VERSION "HNNBNNNYNNNNNNNNNNNNNNNNNNNNNNNNNNNNNNNNNN/4/%%%/4/'%**4NNN///"

NS_ :

BS_ :

BU_:  Airbag BAP_Tester ICAS1_Gateway ICAS1_KommunikationsServer LE1 LE2 Motor_BEV Schaltbetaetigung

BO_ 1019 TSK_Ausrollkurve_01: 8 Motor_BEV
 SG_ TSK_Ausrollkurve_Schub_Reku_01 m0 : 0|7@1+ (2.000000,0.000000) [0.000000|252.000000] "Unit_KiloMeterPerHour" ICAS1_Gateway
 SG_ TSK_Ausrollkurve_Schub_Reku_05 m1 : 0|7@1+ (2.000000,0.000000) [0.000000|252.000000] "Unit_KiloMeterPerHour" ICAS1_Gateway
 SG_ TSK_Ausrollkurve_Schub_Reku_09 m2 : 0|7@1+ (2.000000,0.000000) [0.000000|252.000000] "Unit_KiloMeterPerHour" ICAS1_Gateway
 SG_ TSK_Ausrollkurve_Schub_Reku_13 m3 : 0|7@1+ (2.000000,0.000000) [0.000000|252.000000] "Unit_KiloMeterPerHour" ICAS1_Gateway
 SG_ TSK_Ausrollkurve_Schub_Reku_17 m4 : 0|7@1+ (2.000000,0.000000) [0.000000|252.000000] "Unit_KiloMeterPerHour" ICAS1_Gateway
 SG_ TSK_Ausrollkurve_Schub_Reku_02 m0 : 7|7@1+ (2.000000,0.000000) [0.000000|252.000000] "Unit_KiloMeterPerHour" ICAS1_Gateway
 SG_ TSK_Ausrollkurve_Schub_Reku_06 m1 : 7|7@1+ (2.000000,0.000000) [0.000000|252.000000] "Unit_KiloMeterPerHour" ICAS1_Gateway
 SG_ TSK_Ausrollkurve_Schub_Reku_10 m2 : 7|7@1+ (2.000000,0.000000) [0.000000|252.000000] "Unit_KiloMeterPerHour" ICAS1_Gateway
 SG_ TSK_Ausrollkurve_Schub_Reku_14 m3 : 7|7@1+ (2.000000,0.000000) [0.000000|252.000000] "Unit_KiloMeterPerHour" ICAS1_Gateway
 SG_ TSK_Ausrollkurve_Schub_Reku_18 m4 : 7|7@1+ (2.000000,0.000000) [0.000000|252.000000] "Unit_KiloMeterPerHour" ICAS1_Gateway
 SG_ TSK_Ausrollkurve_Schub_Reku_03 m0 : 14|7@1+ (2.000000,0.000000) [0.000000|252.000000] "Unit_KiloMeterPerHour" ICAS1_Gateway
 SG_ TSK_Ausrollkurve_Schub_Reku_07 m1 : 14|7@1+ (2.000000,0.000000) [0.000000|252.000000] "Unit_KiloMeterPerHour" ICAS1_Gateway
 SG_ TSK_Ausrollkurve_Schub_Reku_11 m2 : 14|7@1+ (2.000000,0.000000) [0.000000|252.000000] "Unit_KiloMeterPerHour" ICAS1_Gateway
 SG_ TSK_Ausrollkurve_Schub_Reku_15 m3 : 14|7@1+ (2.000000,0.000000) [0.000000|252.000000] "Unit_KiloMeterPerHour" ICAS1_Gateway
 SG_ TSK_Ausrollkurve_Schub_Reku_19 m4 : 14|7@1+ (2.000000,0.000000) [0.000000|252.000000] "Unit_KiloMeterPerHour" ICAS1_Gateway
 SG_ TSK_Ausrollkurve_Schub_Reku_04 m0 : 21|7@1+ (2.000000,0.000000) [0.000000|252.000000] "Unit_KiloMeterPerHour" ICAS1_Gateway
 SG_ TSK_Ausrollkurve_Schub_Reku_08 m1 : 21|7@1+ (2.000000,0.000000) [0.000000|252.000000] "Unit_KiloMeterPerHour" ICAS1_Gateway
 SG_ TSK_Ausrollkurve_Schub_Reku_12 m2 : 21|7@1+ (2.000000,0.000000) [0.000000|252.000000] "Unit_KiloMeterPerHour" ICAS1_Gateway
 SG_ TSK_Ausrollkurve_Schub_Reku_16 m3 : 21|7@1+ (2.000000,0.000000) [0.000000|252.000000] "Unit_KiloMeterPerHour" ICAS1_Gateway
 SG_ TSK_Ausrollkurve_Schub_Reku_20 m4 : 21|7@1+ (2.000000,0.000000) [0.000000|252.000000] "Unit_KiloMeterPerHour" ICAS1_Gateway
 SG_ TSK_Ausrollkurve_Segeln_01 m0 : 28|7@1+ (2.000000,0.000000) [0.000000|252.000000] "Unit_KiloMeterPerHour" ICAS1_Gateway
 SG_ TSK_Ausrollkurve_Segeln_05 m1 : 28|7@1+ (2.000000,0.000000) [0.000000|252.000000] "Unit_KiloMeterPerHour" ICAS1_Gateway
 SG_ TSK_Ausrollkurve_Segeln_09 m2 : 28|7@1+ (2.000000,0.000000) [0.000000|252.000000] "Unit_KiloMeterPerHour" ICAS1_Gateway
 SG_ TSK_Ausrollkurve_Segeln_13 m3 : 28|7@1+ (2.000000,0.000000) [0.000000|252.000000] "Unit_KiloMeterPerHour" ICAS1_Gateway
 SG_ TSK_Ausrollkurve_Segeln_17 m4 : 28|7@1+ (2.000000,0.000000) [0.000000|252.000000] "Unit_KiloMeterPerHour" ICAS1_Gateway
 SG_ TSK_Ausrollkurve_Segeln_02 m0 : 35|7@1+ (2.000000,0.000000) [0.000000|252.000000] "Unit_KiloMeterPerHour" ICAS1_Gateway
 SG_ TSK_Ausrollkurve_Segeln_06 m1 : 35|7@1+ (2.000000,0.000000) [0.000000|252.000000] "Unit_KiloMeterPerHour" ICAS1_Gateway
 SG_ TSK_Ausrollkurve_Segeln_10 m2 : 35|7@1+ (2.000000,0.000000) [0.000000|252.000000] "Unit_KiloMeterPerHour" ICAS1_Gateway
 SG_ TSK_Ausrollkurve_Segeln_14 m3 : 35|7@1+ (2.000000,0.000000) [0.000000|252.000000] "Unit_KiloMeterPerHour" ICAS1_Gateway
 SG_ TSK_Ausrollkurve_Segeln_18 m4 : 35|7@1+ (2.000000,0.000000) [0.000000|252.000000] "Unit_KiloMeterPerHour" ICAS1_Gateway
 SG_ TSK_Ausrollkurve_Segeln_03 m0 : 42|7@1+ (2.000000,0.000000) [0.000000|252.000000] "Unit_KiloMeterPerHour" ICAS1_Gateway
 SG_ TSK_Ausrollkurve_Segeln_07 m1 : 42|7@1+ (2.000000,0.000000) [0.000000|252.000000] "Unit_KiloMeterPerHour" ICAS1_Gateway
 SG_ TSK_Ausrollkurve_Segeln_11 m2 : 42|7@1+ (2.000000,0.000000) [0.000000|252.000000] "Unit_KiloMeterPerHour" ICAS1_Gateway
 SG_ TSK_Ausrollkurve_Segeln_15 m3 : 42|7@1+ (2.000000,0.000000) [0.000000|252.000000] "Unit_KiloMeterPerHour" ICAS1_Gateway
 SG_ TSK_Ausrollkurve_Segeln_19 m4 : 42|7@1+ (2.000000,0.000000) [0.000000|252.000000] "Unit_KiloMeterPerHour" ICAS1_Gateway
 SG_ TSK_Ausrollkurve_Segeln_04 m0 : 49|7@1+ (2.000000,0.000000) [0.000000|252.000000] "Unit_KiloMeterPerHour" ICAS1_Gateway
 SG_ TSK_Ausrollkurve_Segeln_08 m1 : 49|7@1+ (2.000000,0.000000) [0.000000|252.000000] "Unit_KiloMeterPerHour" ICAS1_Gateway
 SG_ TSK_Ausrollkurve_Segeln_12 m2 : 49|7@1+ (2.000000,0.000000) [0.000000|252.000000] "Unit_KiloMeterPerHour" ICAS1_Gateway
 SG_ TSK_Ausrollkurve_Segeln_16 m3 : 49|7@1+ (2.000000,0.000000) [0.000000|252.000000] "Unit_KiloMeterPerHour" ICAS1_Gateway
 SG_ TSK_Ausrollkurve_Segeln_20 m4 : 49|7@1+ (2.000000,0.000000) [0.000000|252.000000] "Unit_KiloMeterPerHour" ICAS1_Gateway
 SG_ TSK_Ausrollkurve_Mux M : 56|3@1+ (1.000000,0.000000) [0.000000|7.000000] "" ICAS1_Gateway
 SG_ TSK_Ausrollkurve_Reku  : 59|1@1+ (1.000000,0.000000) [0.000000|1.000000] "" ICAS1_Gateway
 SG_ TSK_Ausrollkurve_Schrittweite  : 60|1@1+ (1.000000,0.000000) [0.000000|1.000000] "" ICAS1_Gateway
 SG_ TSK_Ausrollkurve_Zaehler  : 61|2@1+ (1.000000,0.000000) [0.000000|3.000000] "" ICAS1_Gateway

BO_ 1716 VIN_01: 8 ICAS1_Gateway
 SG_ VIN_01_MUX M : 0|2@1+ (1.000000,0.000000) [0.000000|3.000000] "" Airbag Motor_BEV
 SG_ KS_Geheimnis_1 m0 : 8|8@1+ (1.000000,0.000000) [0.000000|255.000000] "" Airbag
 SG_ VIN_4 m1 : 8|8@1+ (1.000000,0.000000) [0.000000|255.000000] "" Airbag Motor_BEV
 SG_ VIN_11 m2 : 8|8@1+ (1.000000,0.000000) [0.000000|255.000000] "" Airbag Motor_BEV
 SG_ KS_Geheimnis_2 m0 : 16|8@1+ (1.000000,0.000000) [0.000000|255.000000] "" Airbag
 SG_ VIN_5 m1 : 16|8@1+ (1.000000,0.000000) [0.000000|255.000000] "" Airbag Motor_BEV
 SG_ VIN_12 m2 : 16|8@1+ (1.000000,0.000000) [0.000000|255.000000] "" Airbag Motor_BEV
 SG_ KS_Geheimnis_3 m0 : 24|8@1+ (1.000000,0.000000) [0.000000|255.000000] "" Airbag
 SG_ VIN_6 m1 : 24|8@1+ (1.000000,0.000000) [0.000000|255.000000] "" Airbag Motor_BEV
 SG_ VIN_13 m2 : 24|8@1+ (1.000000,0.000000) [0.000000|255.000000] "" Airbag Motor_BEV
 SG_ KS_Geheimnis_4 m0 : 32|8@1+ (1.000000,0.000000) [0.000000|255.000000] "" Airbag
 SG_ VIN_7 m1 : 32|8@1+ (1.000000,0.000000) [0.000000|255.000000] "" Airbag Motor_BEV
 SG_ VIN_14 m2 : 32|8@1+ (1.000000,0.000000) [0.000000|255.000000] "" Airbag Motor_BEV
 SG_ VIN_1 m0 : 40|8@1+ (1.000000,0.000000) [0.000000|255.000000] "" Airbag Motor_BEV
 SG_ VIN_8 m1 : 40|8@1+ (1.000000,0.000000) [0.000000|255.000000] "" Airbag Motor_BEV
 SG_ VIN_15 m2 : 40|8@1+ (1.000000,0.000000) [0.000000|255.000000] "" Airbag Motor_BEV
 SG_ VIN_2 m0 : 48|8@1+ (1.000000,0.000000) [0.000000|255.000000] "" Airbag Motor_BEV
 SG_ VIN_9 m1 : 48|8@1+ (1.000000,0.000000) [0.000000|255.000000] "" Airbag Motor_BEV
 SG_ VIN_16 m2 : 48|8@1+ (1.000000,0.000000) [0.000000|255.000000] "" Airbag Motor_BEV
 SG_ VIN_3 m0 : 56|8@1+ (1.000000,0.000000) [0.000000|255.000000] "" Airbag Motor_BEV
 SG_ VIN_10 m1 : 56|8@1+ (1.000000,0.000000) [0.000000|255.000000] "" Airbag Motor_BEV
 SG_ VIN_17 m2 : 56|8@1+ (1.000000,0.000000) [0.000000|255.000000] "" Airbag Motor_BEV

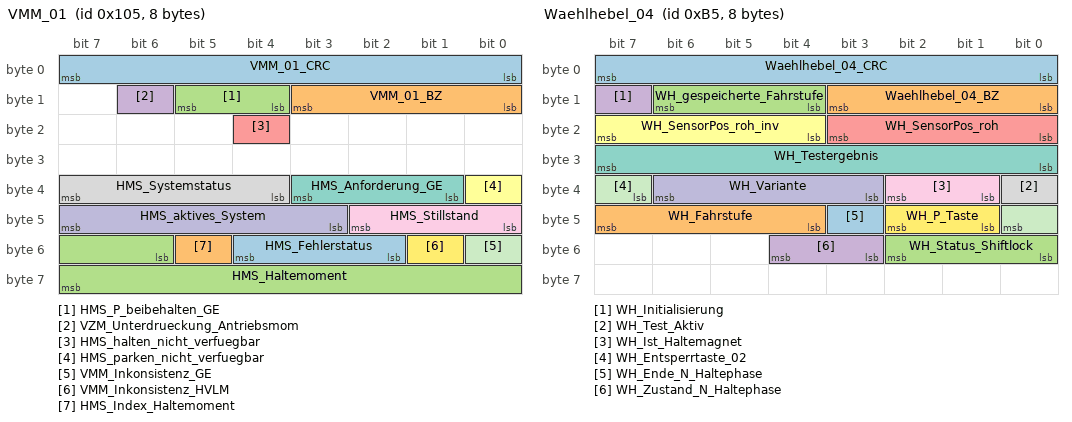
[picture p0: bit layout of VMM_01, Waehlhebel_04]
BO_ 261 VMM_01: 8 ICAS1_Gateway
 SG_ VMM_01_CRC  : 0|8@1+ (1.000000,0.000000) [0.000000|255.000000] "" Motor_BEV
 SG_ VMM_01_BZ  : 8|4@1+ (1.000000,0.000000) [0.000000|15.000000] "" Motor_BEV
 SG_ HMS_P_beibehalten_GE  : 12|2@1+ (1.000000,0.000000) [0.000000|3.000000] "" Vector__XXX
 SG_ VZM_Unterdrueckung_Antriebsmom  : 14|1@1+ (1.000000,0.000000) [0.000000|1.000000] "" Airbag Motor_BEV
 SG_ HMS_halten_nicht_verfuegbar  : 20|1@1+ (1.000000,0.000000) [0.000000|1.000000] "" Vector__XXX
 SG_ HMS_parken_nicht_verfuegbar  : 32|1@1+ (1.000000,0.000000) [0.000000|1.000000] "" Vector__XXX
 SG_ HMS_Anforderung_GE  : 33|3@1+ (1.000000,0.000000) [0.000000|7.000000] "" Vector__XXX
 SG_ HMS_Systemstatus  : 36|4@1+ (1.000000,0.000000) [0.000000|15.000000] "" Motor_BEV
 SG_ HMS_Stillstand  : 40|3@1+ (1.000000,0.000000) [0.000000|7.000000] "" Motor_BEV
 SG_ HMS_aktives_System  : 43|5@1+ (1.000000,0.000000) [0.000000|31.000000] "" Motor_BEV
 SG_ VMM_Inkonsistenz_GE  : 48|1@1+ (1.000000,0.000000) [0.000000|1.000000] "" Motor_BEV
 SG_ VMM_Inkonsistenz_HVLM  : 49|1@1+ (1.000000,0.000000) [0.000000|1.000000] "" Motor_BEV
 SG_ HMS_Fehlerstatus  : 50|3@1+ (1.000000,0.000000) [0.000000|7.000000] "" Vector__XXX
 SG_ HMS_Index_Haltemoment  : 53|1@1+ (1.000000,0.000000) [0.000000|1.000000] "" Motor_BEV
 SG_ HMS_Haltemoment  : 54|10@1+ (10.000000,0.000000) [0.000000|10210.000000] "Unit_NewtoMeter" Motor_BEV

BO_ 313 VMM_02: 32 ICAS1_Gateway
 SG_ VMM_02_CRC  : 0|8@1+ (1.000000,0.000000) [0.000000|255.000000] "" Motor_BEV
 SG_ VMM_02_BZ  : 8|4@1+ (1.000000,0.000000) [0.000000|15.000000] "" Motor_BEV
 SG_ VZM_aktiver_Basisservice  : 12|3@1+ (1.000000,0.000000) [0.000000|7.000000] "" Motor_BEV
 SG_ VZM_Anhalteweg_nicht_verfuegbar  : 15|1@1+ (1.000000,0.000000) [0.000000|1.000000] "" Motor_BEV
 SG_ VZM_Fahrer_bremst  : 16|1@1+ (1.000000,0.000000) [0.000000|1.000000] "" Motor_BEV
 SG_ VZM_QBit_Fahrer_bremst  : 17|1@1+ (1.000000,0.000000) [0.000000|1.000000] "" Motor_BEV
 SG_ VMM_MKB_codiert  : 18|1@1+ (1.000000,0.000000) [0.000000|1.000000] "" Airbag
 SG_ VMM_Inkonsistenz_EBKV  : 19|1@1+ (1.000000,0.000000) [0.000000|1.000000] "" Vector__XXX
 SG_ VMM_Notstopp_Status  : 20|3@1+ (1.000000,0.000000) [0.000000|7.000000] "" Motor_BEV
 SG_ VZM_Warnruck_nicht_verfuegbar  : 23|1@1+ (1.000000,0.000000) [0.000000|1.000000] "" Motor_BEV
 SG_ VZM_Warnruckeln_nicht_verfuegbar  : 24|1@1+ (1.000000,0.000000) [0.000000|1.000000] "" Motor_BEV
 SG_ VZM_Bkd_nicht_verfuegbar  : 25|1@1+ (1.000000,0.000000) [0.000000|1.000000] "" Motor_BEV
 SG_ VMM_Bremslicht_defekt  : 26|1@1+ (1.000000,0.000000) [0.000000|1.000000] "" Motor_BEV
 SG_ VZM_Fahrer_bremst_deutlich  : 27|1@1+ (1.000000,0.000000) [0.000000|1.000000] "" Airbag Motor_BEV
 SG_ VZM_TSK_SRBM_Anf  : 28|1@1+ (1.000000,0.000000) [0.000000|1.000000] "" Motor_BEV
 SG_ VZM_TSK_SRBM_nicht_verfuegbar  : 29|1@1+ (1.000000,0.000000) [0.000000|1.000000] "" Motor_BEV
 SG_ VZM_Verz_Reg_aktiv  : 30|5@1+ (1.000000,0.000000) [0.000000|31.000000] "" Motor_BEV
 SG_ VZM_Verz_Reg_nicht_verfuegbar  : 35|1@1+ (1.000000,0.000000) [0.000000|1.000000] "" Motor_BEV
 SG_ VMM_Inkonsistenz_KAS  : 36|1@1+ (1.000000,0.000000) [0.000000|1.000000] "" Motor_BEV
 SG_ VMM_Bremslicht_unplausibel  : 37|1@1+ (1.000000,0.000000) [0.000000|1.000000] "" Motor_BEV
 SG_ VMM_Inkonsistenz_ACC  : 38|1@1+ (1.000000,0.000000) [0.000000|1.000000] "" Motor_BEV
 SG_ VMM_Inkonsistenz_AWV_PCF  : 39|1@1+ (1.000000,0.000000) [0.000000|1.000000] "" Motor_BEV
 SG_ VMM_Inkonsistenz_ARA  : 40|1@1+ (1.000000,0.000000) [0.000000|1.000000] "" Motor_BEV
 SG_ VMM_Inkonsistenz_ParkAssist  : 41|1@1+ (1.000000,0.000000) [0.000000|1.000000] "" Motor_BEV
 SG_ VMM_Inkonsistenz_FAS_VK  : 42|1@1+ (1.000000,0.000000) [0.000000|1.000000] "" Motor_BEV
 SG_ VMM_Inkonsistenz_NV  : 43|1@1+ (1.000000,0.000000) [0.000000|1.000000] "" Motor_BEV
 SG_ VMM_Inkonsistenz_RCTA  : 44|1@1+ (1.000000,0.000000) [0.000000|1.000000] "" Motor_BEV
 SG_ VMM_Inkonsistenz_TSK  : 45|1@1+ (1.000000,0.000000) [0.000000|1.000000] "" Motor_BEV
 SG_ VMM_Inkonsistenz_MO  : 46|1@1+ (1.000000,0.000000) [0.000000|1.000000] "" Motor_BEV
 SG_ VMM_Inkonsistenz_AEB  : 47|1@1+ (1.000000,0.000000) [0.000000|1.000000] "" Vector__XXX
 SG_ VMM_Fahrer_Bremskraft_bestimmend  : 48|1@1+ (1.000000,0.000000) [0.000000|1.000000] "" Motor_BEV
 SG_ VMM_Inkonsistenz_EA  : 49|1@1+ (1.000000,0.000000) [0.000000|1.000000] "" Motor_BEV
 SG_ VZM_Status_Wegregelung  : 50|2@1+ (1.000000,0.000000) [0.000000|3.000000] "" Motor_BEV
 SG_ VZM_Verz_ASIL_Verfuegbarkeit  : 52|3@1+ (1.000000,0.000000) [0.000000|7.000000] "" Motor_BEV
 SG_ VZM_aktives_System  : 55|5@1+ (1.000000,0.000000) [0.000000|31.000000] "" Airbag Motor_BEV
 SG_ VZM_Verz_Begrenzung  : 60|1@1+ (1.000000,0.000000) [0.000000|1.000000] "" Motor_BEV
 SG_ VZM_Systemstatus  : 61|3@1+ (1.000000,0.000000) [0.000000|7.000000] "" Motor_BEV
 SG_ VZM_SRBM_Soll  : 64|12@1+ (8.000000,0.000000) [0.000000|32744.000000] "Unit_NewtoMeter" Motor_BEV
 SG_ VZM_SRBM_Ist  : 76|12@1+ (8.000000,0.000000) [0.000000|32744.000000] "Unit_NewtoMeter" Motor_BEV
 SG_ VZM_SRBM_max_Gradient  : 88|7@1+ (50.000000,0.000000) [0.000000|6250.000000] "Unit_NewtoMeterPerSecon" Motor_BEV
 SG_ VMM_Inkonsistenz_KAM  : 95|1@1+ (1.000000,0.000000) [0.000000|1.000000] "" Vector__XXX

BO_ 2463978663 VZE_04: 32 ICAS1_Gateway
 SG_ VZE_Anzeigemodus  : 0|2@1+ (1.000000,0.000000) [0.000000|3.000000] "" Vector__XXX
 SG_ VZE_Hinweistext  : 2|3@1+ (1.000000,0.000000) [1.000000|7.000000] "" Motor_BEV
 SG_ VZE_Verkehrszeichen_Einheit  : 8|1@1+ (1.000000,0.000000) [0.000000|1.000000] "" Vector__XXX
 SG_ VZE_Anzeigeunterdrueck_Zeichen_3  : 9|1@1+ (1.000000,0.000000) [0.000000|1.000000] "" Vector__XXX
 SG_ VZE_Anzeigeunterdrueck_Zeichen_2  : 10|1@1+ (1.000000,0.000000) [0.000000|1.000000] "" Vector__XXX
 SG_ VZE_Verkehrszeichen_1  : 11|8@1+ (1.000000,0.000000) [1.000000|255.000000] "" Motor_BEV
 SG_ VZE_Verkehrszeichen_2  : 19|8@1+ (1.000000,0.000000) [1.000000|255.000000] "" Vector__XXX
 SG_ VZE_Verkehrszeichen_3  : 27|8@1+ (1.000000,0.000000) [1.000000|255.000000] "" Vector__XXX
 SG_ VZE_Warnung_Verkehrszeichen_1  : 35|1@1+ (1.000000,0.000000) [0.000000|1.000000] "" Vector__XXX
 SG_ VZE_Warnung_Verkehrszeichen_2  : 36|1@1+ (1.000000,0.000000) [0.000000|1.000000] "" Vector__XXX
 SG_ VZE_Warnung_Verkehrszeichen_3  : 37|1@1+ (1.000000,0.000000) [0.000000|1.000000] "" Vector__XXX
 SG_ VZE_Zusatzschild_1  : 38|4@1+ (1.000000,0.000000) [1.000000|15.000000] "" Vector__XXX
 SG_ VZE_Zusatzschild_2  : 42|4@1+ (1.000000,0.000000) [1.000000|15.000000] "" Vector__XXX
 SG_ VZE_Zusatzschild_3  : 46|4@1+ (1.000000,0.000000) [1.000000|15.000000] "" Vector__XXX
 SG_ VZE_Anzeigeunterdrueck_Zeichen_1  : 50|1@1+ (1.000000,0.000000) [0.000000|1.000000] "" Vector__XXX
 SG_ VZE_Zeichen_01_KameraWied  : 51|1@1+ (1.000000,0.000000) [0.000000|1.000000] "" Motor_BEV
 SG_ VZE_Zeichen_02_KameraWied  : 52|1@1+ (1.000000,0.000000) [0.000000|1.000000] "" Vector__XXX
 SG_ VZE_Zeichen_03_KameraWied  : 53|1@1+ (1.000000,0.000000) [0.000000|1.000000] "" Vector__XXX
 SG_ VZE_Zeichen_01_Kamera  : 54|1@1+ (1.000000,0.000000) [0.000000|1.000000] "" Motor_BEV
 SG_ VZE_Zeichen_01_Karte  : 55|1@1+ (1.000000,0.000000) [0.000000|1.000000] "" Vector__XXX
 SG_ VZE_Zeichen_01_Gesetz  : 56|1@1+ (1.000000,0.000000) [0.000000|1.000000] "" Vector__XXX
 SG_ VZE_Zeichen_02_Kamera  : 57|1@1+ (1.000000,0.000000) [0.000000|1.000000] "" Vector__XXX
 SG_ VZE_Zeichen_02_Karte  : 58|1@1+ (1.000000,0.000000) [0.000000|1.000000] "" Vector__XXX
 SG_ VZE_Zeichen_02_Gesetz  : 59|1@1+ (1.000000,0.000000) [0.000000|1.000000] "" Vector__XXX
 SG_ VZE_Zeichen_03_Kamera  : 60|1@1+ (1.000000,0.000000) [0.000000|1.000000] "" Vector__XXX
 SG_ VZE_Zeichen_03_Karte  : 61|1@1+ (1.000000,0.000000) [0.000000|1.000000] "" Vector__XXX
 SG_ VZE_Zeichen_03_Gesetz  : 62|1@1+ (1.000000,0.000000) [0.000000|1.000000] "" Vector__XXX
 SG_ VZE_Gong  : 63|1@1+ (1.000000,0.000000) [0.000000|1.000000] "" Vector__XXX
 SG_ VZE_Anzeigeunterdrueck_Zeichen_5  : 72|1@1+ (1.000000,0.000000) [0.000000|1.000000] "" Vector__XXX
 SG_ VZE_Zeichen_05_KameraWied  : 73|1@1+ (1.000000,0.000000) [0.000000|1.000000] "" Vector__XXX
 SG_ VZE_Zeichen_05_Kamera  : 74|1@1+ (1.000000,0.000000) [0.000000|1.000000] "" Vector__XXX
 SG_ VZE_Verkehrszeichen_4  : 75|8@1+ (1.000000,0.000000) [1.000000|255.000000] "" Motor_BEV
 SG_ VZE_Verkehrszeichen_5  : 83|8@1+ (1.000000,0.000000) [1.000000|255.000000] "" Motor_BEV
 SG_ VZE_Anhaenger_Vmax  : 91|4@1+ (10.000000,10.000000) [10.000000|140.000000] "Unit_KiloMeterPerHour" Vector__XXX
 SG_ VZE_Zeichen_04_Gesetz  : 95|1@1+ (1.000000,0.000000) [0.000000|1.000000] "" Vector__XXX
 SG_ VZE_Zeichen_04_Kamera  : 96|1@1+ (1.000000,0.000000) [0.000000|1.000000] "" Vector__XXX
 SG_ VZE_Zeichen_04_KameraWied  : 97|1@1+ (1.000000,0.000000) [0.000000|1.000000] "" Vector__XXX
 SG_ VZE_Zeichen_04_Karte  : 98|1@1+ (1.000000,0.000000) [0.000000|1.000000] "" Vector__XXX
 SG_ VZE_Warnung_Verkehrszeichen_4  : 99|1@1+ (1.000000,0.000000) [0.000000|1.000000] "" Vector__XXX
 SG_ VZE_Warnung_Verkehrszeichen_5  : 100|1@1+ (1.000000,0.000000) [0.000000|1.000000] "" Vector__XXX
 SG_ VZE_Zeichen_05_Gesetz  : 101|1@1+ (1.000000,0.000000) [0.000000|1.000000] "" Vector__XXX
 SG_ VZE_Zusatzschild_4  : 102|4@1+ (1.000000,0.000000) [1.000000|15.000000] "" Vector__XXX
 SG_ VZE_Zusatzschild_5  : 106|4@1+ (1.000000,0.000000) [1.000000|15.000000] "" Vector__XXX
 SG_ VZE_Baustelle  : 110|2@1+ (1.000000,0.000000) [0.000000|3.000000] "" Vector__XXX
 SG_ VZE_Zeichen_05_Karte  : 112|1@1+ (1.000000,0.000000) [0.000000|1.000000] "" Vector__XXX
 SG_ VZE_Zeichen_05_Entfernung  : 113|7@1+ (1.000000,0.000000) [1.000000|127.000000] "Unit_Meter" Motor_BEV
 SG_ VZE_Zeichen_05_Entfernung_StdA  : 120|7@1+ (1.000000,0.000000) [1.000000|127.000000] "Unit_Meter" Motor_BEV
 SG_ VZE_Anzeigeunterdrueck_Zeichen_4  : 127|1@1+ (1.000000,0.000000) [0.000000|1.000000] "" Vector__XXX
 SG_ VZE_Verkehrszeichen_6  : 128|8@1+ (1.000000,0.000000) [1.000000|255.000000] "Unit_None" Motor_BEV
 SG_ VZE_Zusatzschild_6  : 136|4@1+ (1.000000,0.000000) [1.000000|15.000000] "" Vector__XXX
 SG_ VZE_Zeichen_06_Entfernung  : 140|7@1+ (1.000000,0.000000) [1.000000|127.000000] "Unit_Meter" Motor_BEV
 SG_ VZE_Zeichen_06_Entfernung_StdA  : 147|7@1+ (1.000000,0.000000) [1.000000|127.000000] "Unit_Meter" Motor_BEV
 SG_ VZE_Umweltinfo_Naesse  : 154|1@1+ (1.000000,0.000000) [0.000000|1.000000] "" Motor_BEV
 SG_ VZE_Umweltinfo_Nebel  : 155|1@1+ (1.000000,0.000000) [0.000000|1.000000] "" Motor_BEV
 SG_ VZE_Umweltinfo_Anhaengerbetrieb  : 156|1@1+ (1.000000,0.000000) [0.000000|1.000000] "" Vector__XXX
 SG_ VZE_Erweiterte_Information  : 157|8@1+ (1.000000,0.000000) [1.000000|255.000000] "Unit_None" Vector__XXX
 SG_ VZE_Tempowarnung_Status  : 165|1@1+ (1.000000,0.000000) [0.000000|1.000000] "" Vector__XXX
 SG_ VZE_Tempowarnung_Einheit  : 166|1@1+ (1.000000,0.000000) [0.000000|1.000000] "" Vector__XXX
 SG_ VZE_Tempowarnung_Offset  : 167|5@1+ (1.000000,0.000000) [1.000000|31.000000] "" Vector__XXX
 SG_ VZE_FoD_Status  : 206|2@1+ (1.000000,0.000000) [0.000000|3.000000] "" Vector__XXX
 SG_ VZE_Anzeige_ZS_1  : 208|4@1+ (1.000000,0.000000) [1.000000|15.000000] "Unit_None" Vector__XXX
 SG_ VZE_Anzeige_ZS_2  : 212|4@1+ (1.000000,0.000000) [1.000000|15.000000] "Unit_None" Vector__XXX
 SG_ VZE_Anzeige_ZS_3  : 216|4@1+ (1.000000,0.000000) [1.000000|15.000000] "Unit_None" Vector__XXX
 SG_ VZE_Hinweistext_03  : 220|4@1+ (1.000000,0.000000) [1.000000|15.000000] "" Vector__XXX
 SG_ VZE_Land  : 224|5@1+ (1.000000,0.000000) [1.000000|31.000000] "" Vector__XXX
 SG_ VZE_Warnung_VZ_1  : 229|1@1+ (1.000000,0.000000) [0.000000|1.000000] "" Vector__XXX
 SG_ VZE_Warnung_VZ_2  : 230|1@1+ (1.000000,0.000000) [0.000000|1.000000] "" Vector__XXX
 SG_ VZE_Warnung_VZ_3  : 231|1@1+ (1.000000,0.000000) [0.000000|1.000000] "" Vector__XXX
 SG_ VZE_Anzeige_VZ_1  : 232|8@1+ (1.000000,0.000000) [1.000000|255.000000] "" Vector__XXX
 SG_ VZE_Anzeige_VZ_2  : 240|8@1+ (1.000000,0.000000) [1.000000|255.000000] "Unit_None" Vector__XXX
 SG_ VZE_Anzeige_VZ_3  : 248|8@1+ (1.000000,0.000000) [1.000000|255.000000] "Unit_None" Vector__XXX

BO_ 181 Waehlhebel_04: 8 ICAS1_Gateway
 SG_ Waehlhebel_04_CRC  : 0|8@1+ (1.000000,0.000000) [0.000000|255.000000] "" Motor_BEV
 SG_ Waehlhebel_04_BZ  : 8|4@1+ (1.000000,0.000000) [0.000000|15.000000] "" Motor_BEV
 SG_ WH_gespeicherte_Fahrstufe  : 12|3@1+ (1.000000,0.000000) [0.000000|7.000000] "" Vector__XXX
 SG_ WH_Initialisierung  : 15|1@1+ (1.000000,0.000000) [0.000000|1.000000] "" Motor_BEV
 SG_ WH_SensorPos_roh  : 16|4@1+ (1.000000,0.000000) [0.000000|15.000000] "" Motor_BEV
 SG_ WH_SensorPos_roh_inv  : 20|4@1+ (1.000000,0.000000) [0.000000|15.000000] "" Motor_BEV
 SG_ WH_Testergebnis  : 24|8@1+ (1.000000,0.000000) [0.000000|255.000000] "" Vector__XXX
 SG_ WH_Test_Aktiv  : 32|1@1+ (1.000000,0.000000) [0.000000|1.000000] "" Vector__XXX
 SG_ WH_Ist_Haltemagnet  : 33|2@1+ (1.000000,0.000000) [0.000000|3.000000] "" Motor_BEV
 SG_ WH_Variante  : 35|4@1+ (1.000000,0.000000) [0.000000|15.000000] "" Motor_BEV
 SG_ WH_Entsperrtaste_02  : 39|2@1+ (1.000000,0.000000) [0.000000|3.000000] "" Motor_BEV
 SG_ WH_P_Taste  : 41|2@1+ (1.000000,0.000000) [0.000000|3.000000] "" Motor_BEV
 SG_ WH_Ende_N_Haltephase  : 43|1@1+ (1.000000,0.000000) [0.000000|1.000000] "" Vector__XXX
 SG_ WH_Fahrstufe  : 44|4@1+ (1.000000,0.000000) [0.000000|15.000000] "" Motor_BEV
 SG_ WH_Status_Shiftlock  : 48|3@1+ (1.000000,0.000000) [0.000000|7.000000] "" Motor_BEV
 SG_ WH_Zustand_N_Haltephase  : 51|2@1+ (1.000000,0.000000) [0.000000|3.000000] "" Vector__XXX

BO_ 2463978687 Waehlhebel_06: 8 ICAS1_Gateway
 SG_ WH_Fehler_Haltemagnet_Status  : 41|1@1+ (1.000000,0.000000) [0.000000|1.000000] "" Motor_BEV
 SG_ WH_Fehler_CRC_SBM  : 42|1@1+ (1.000000,0.000000) [0.000000|1.000000] "" Motor_BEV
 SG_ WH_Fehler_CRC_SBM_Status  : 43|1@1+ (1.000000,0.000000) [0.000000|1.000000] "" Motor_BEV
 SG_ WH_Fehler_Timeout_SBM  : 44|1@1+ (1.000000,0.000000) [0.000000|1.000000] "" Motor_BEV
 SG_ WH_Fehler_Timeout_SBM_Status  : 45|1@1+ (1.000000,0.000000) [0.000000|1.000000] "" Motor_BEV
 SG_ WH_Fehler_Ueberspannung  : 46|1@1+ (1.000000,0.000000) [0.000000|1.000000] "" Motor_BEV
 SG_ WH_Fehler_Ueberspannung_Status  : 47|1@1+ (1.000000,0.000000) [0.000000|1.000000] "" Motor_BEV
 SG_ WH_Fehler_BZ_SBM  : 48|1@1+ (1.000000,0.000000) [0.000000|1.000000] "" Motor_BEV
 SG_ WH_Fehler_BZ_SBM_Status  : 49|1@1+ (1.000000,0.000000) [0.000000|1.000000] "" Motor_BEV
 SG_ WH_Fehler_Unterspannung  : 50|1@1+ (1.000000,0.000000) [0.000000|1.000000] "" Motor_BEV
 SG_ WH_Fehler_Unterspannung_Status  : 51|1@1+ (1.000000,0.000000) [0.000000|1.000000] "" Motor_BEV
 SG_ WH_Fehler_Ausleuchtung  : 52|1@1+ (1.000000,0.000000) [0.000000|1.000000] "" Motor_BEV
 SG_ WH_Fehler_Ausleuchtung_Status  : 53|1@1+ (1.000000,0.000000) [0.000000|1.000000] "" Motor_BEV
 SG_ WH_Fehler_Entsperrtaste  : 54|1@1+ (1.000000,0.000000) [0.000000|1.000000] "" Motor_BEV
 SG_ WH_Fehler_Entsperrtaste_Status  : 55|1@1+ (1.000000,0.000000) [0.000000|1.000000] "" Motor_BEV
 SG_ WH_Fehler_P_Taste  : 56|1@1+ (1.000000,0.000000) [0.000000|1.000000] "" Motor_BEV
 SG_ WH_Fehler_P_Taste_Status  : 57|1@1+ (1.000000,0.000000) [0.000000|1.000000] "" Motor_BEV
 SG_ WH_Fehler_Sensor_einfach  : 58|1@1+ (1.000000,0.000000) [0.000000|1.000000] "" Motor_BEV
 SG_ WH_Fehler_Sensor_einfach_Status  : 59|1@1+ (1.000000,0.000000) [0.000000|1.000000] "" Motor_BEV
 SG_ WH_Fehler_Sensor_mehrfach  : 60|1@1+ (1.000000,0.000000) [0.000000|1.000000] "" Motor_BEV
 SG_ WH_Fehler_Sensor_mehrfach_Status  : 61|1@1+ (1.000000,0.000000) [0.000000|1.000000] "" Motor_BEV
 SG_ WH_Fehler_Shiftlock  : 62|1@1+ (1.000000,0.000000) [0.000000|1.000000] "" Motor_BEV
 SG_ WH_Fehler_Shiftlock_Status  : 63|1@1+ (1.000000,0.000000) [0.000000|1.000000] "" Motor_BEV

BO_ 916 WBA_03: 8 Motor_BEV
 SG_ WBA_03_CRC  : 0|8@1+ (1.000000,0.000000) [0.000000|255.000000] "" ICAS1_Gateway
 SG_ WBA_03_BZ  : 8|4@1+ (1.000000,0.000000) [0.000000|15.000000] "" ICAS1_Gateway
 SG_ WBA_Fahrstufe_02  : 12|4@1+ (1.000000,0.000000) [0.000000|15.000000] "" ICAS1_Gateway ICAS1_KommunikationsServer
 SG_ WBA_ZielFahrstufe  : 16|4@1+ (1.000000,0.000000) [0.000000|15.000000] "" ICAS1_Gateway
 SG_ WBA_GE_Warnung_02  : 20|4@1+ (1.000000,0.000000) [0.000000|15.000000] "" ICAS1_Gateway
 SG_ WBA_eing_Gang_02  : 24|4@1+ (1.000000,0.000000) [0.000000|15.000000] "" ICAS1_Gateway
 SG_ WBA_GE_Texte  : 28|3@1+ (1.000000,0.000000) [0.000000|7.000000] "" ICAS1_Gateway
 SG_ WBA_Segeln_aktiv  : 31|1@1+ (1.000000,0.000000) [0.000000|1.000000] "" ICAS1_Gateway
 SG_ WBA_Schaltschema_02  : 32|3@1+ (1.000000,0.000000) [0.000000|7.000000] "" ICAS1_Gateway
 SG_ WBA_Schaltschema_FS_inaktiv  : 35|2@1+ (1.000000,0.000000) [0.000000|3.000000] "" ICAS1_Gateway
 SG_ WBA_GE_Zusatzwarnungen  : 37|3@1+ (1.000000,0.000000) [0.000000|7.000000] "" ICAS1_Gateway
 SG_ GE_Sollgang  : 40|4@1+ (1.000000,0.000000) [0.000000|15.000000] "" ICAS1_Gateway
 SG_ GE_Tipschaltempf_verfuegbar  : 44|1@1+ (1.000000,0.000000) [0.000000|1.000000] "" ICAS1_Gateway
 SG_ WBA_GE_Texte_02  : 45|3@1+ (1.000000,0.000000) [0.000000|7.000000] "" ICAS1_Gateway
 SG_ WBA_Schaltschema_Tippgasse  : 48|1@1+ (1.000000,0.000000) [0.000000|1.000000] "" ICAS1_Gateway
 SG_ WBA_Schaltschema_Fahreraktion  : 49|1@1+ (1.000000,0.000000) [0.000000|1.000000] "" ICAS1_Gateway
 SG_ WBA_Schaltschema_FS_vorwaerts  : 50|2@1+ (1.000000,0.000000) [0.000000|3.000000] "" ICAS1_Gateway
 SG_ WBA_Shiftlock_Lampe  : 52|1@1+ (1.000000,0.000000) [0.000000|1.000000] "" ICAS1_Gateway
 SG_ WBA_Anforderung_Akustik  : 53|1@1+ (1.000000,0.000000) [0.000000|1.000000] "" ICAS1_Gateway
 SG_ WBA_Blinken  : 54|1@1+ (1.000000,0.000000) [0.000000|1.000000] "" ICAS1_Gateway
 SG_ GE_Wiederstart_Anz_Std  : 55|1@1+ (1.000000,0.000000) [0.000000|1.000000] "" ICAS1_Gateway
 SG_ GE_Stoppverbot_Anz_01  : 56|1@1+ (1.000000,0.000000) [0.000000|1.000000] "" ICAS1_Gateway
 SG_ GE_Stoppverbot_Anz_02  : 57|1@1+ (1.000000,0.000000) [0.000000|1.000000] "" ICAS1_Gateway
 SG_ GE_Stoppverbot_Anz_03  : 58|1@1+ (1.000000,0.000000) [0.000000|1.000000] "" ICAS1_Gateway
 SG_ GE_Stoppverbot_Anz_04  : 59|1@1+ (1.000000,0.000000) [0.000000|1.000000] "" ICAS1_Gateway
 SG_ GE_Stoppverbot_Anz_05  : 60|1@1+ (1.000000,0.000000) [0.000000|1.000000] "" ICAS1_Gateway
 SG_ GE_Stoppverbot_Anz_06  : 61|1@1+ (1.000000,0.000000) [0.000000|1.000000] "" ICAS1_Gateway
 SG_ GE_Stoppverbot_Anz_07  : 62|1@1+ (1.000000,0.000000) [0.000000|1.000000] "" ICAS1_Gateway
 SG_ GE_Stoppverbot_Anz_Std  : 63|1@1+ (1.000000,0.000000) [0.000000|1.000000] "" ICAS1_Gateway

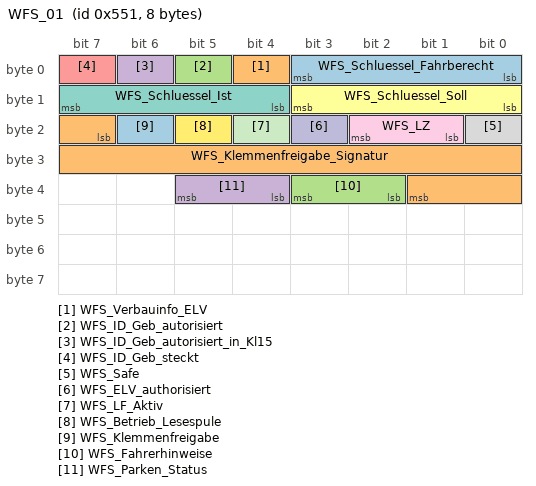
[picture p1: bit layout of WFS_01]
BO_ 1361 WFS_01: 8 ICAS1_Gateway
 SG_ WFS_Schluessel_Fahrberecht  : 0|4@1+ (1.000000,0.000000) [0.000000|15.000000] "" Vector__XXX
 SG_ WFS_Verbauinfo_ELV  : 4|1@1+ (1.000000,0.000000) [0.000000|1.000000] "" Vector__XXX
 SG_ WFS_ID_Geb_autorisiert  : 5|1@1+ (1.000000,0.000000) [0.000000|1.000000] "" Vector__XXX
 SG_ WFS_ID_Geb_autorisiert_in_Kl15  : 6|1@1+ (1.000000,0.000000) [0.000000|1.000000] "" Vector__XXX
 SG_ WFS_ID_Geb_steckt  : 7|1@1+ (1.000000,0.000000) [0.000000|1.000000] "" Vector__XXX
 SG_ WFS_Schluessel_Soll  : 8|4@1+ (1.000000,0.000000) [0.000000|15.000000] "" Vector__XXX
 SG_ WFS_Schluessel_Ist  : 12|4@1+ (1.000000,0.000000) [0.000000|15.000000] "" Vector__XXX
 SG_ WFS_Safe  : 16|1@1+ (1.000000,0.000000) [0.000000|1.000000] "" Vector__XXX
 SG_ WFS_LZ  : 17|2@1+ (1.000000,0.000000) [0.000000|3.000000] "" Vector__XXX
 SG_ WFS_ELV_authorisiert  : 19|1@1+ (1.000000,0.000000) [0.000000|1.000000] "" Vector__XXX
 SG_ WFS_LF_Aktiv  : 20|1@1+ (1.000000,0.000000) [0.000000|1.000000] "" Vector__XXX
 SG_ WFS_Betrieb_Lesespule  : 21|1@1+ (1.000000,0.000000) [0.000000|1.000000] "" Vector__XXX
 SG_ WFS_Klemmenfreigabe  : 22|1@1+ (1.000000,0.000000) [0.000000|1.000000] "" Motor_BEV
 SG_ WFS_Klemmenfreigabe_Signatur  : 23|11@1+ (1.000000,0.000000) [0.000000|2047.000000] "" Vector__XXX
 SG_ WFS_Fahrerhinweise  : 34|2@1+ (1.000000,0.000000) [0.000000|3.000000] "" Vector__XXX
 SG_ WFS_Parken_Status  : 36|2@1+ (1.000000,0.000000) [0.000000|3.000000] "" Vector__XXX

BO_ 2617028096 XCP_Airbag_CRO_01: 64 Vector__XXX
 SG_ XCP_Airbag_CRO_01_Data  : 0|512@1+ (1.000000,0.000000) [0.000000|13407807929942597099574024998205846127479365820592393377723561443721764030073546976801874298166903427690031858186486050853753882811946569946433649006084096.000000] "" Airbag

BO_ 2617028097 XCP_Airbag_DTO_01: 64 Airbag
 SG_ XCP_Airbag_DTO_01_Data  : 0|512@1+ (1.000000,0.000000) [0.000000|13407807929942597099574024998205846127479365820592393377723561443721764030073546976801874298166903427690031858186486050853753882811946569946433649006084096.000000] "" Vector__XXX

BO_ 2617239040 XCP_EMotor_01_CRO_01: 64 Vector__XXX
 SG_ XCP_EMotor_01_CRO_01_Data  : 0|64@1+ (1.000000,0.000000) [0.000000|18446744073709551616.000000] "" LE1

BO_ 2617239041 XCP_EMotor_01_DTO_01: 64 LE1
 SG_ XCP_EMotor_01_DTO_01_Data  : 0|64@1+ (1.000000,0.000000) [0.000000|18446744073709551616.000000] "" Vector__XXX

BO_ 2617239042 XCP_EMotor_01_DTO_02: 64 LE1
 SG_ XCP_EMotor_01_DTO_02_Data  : 0|64@1+ (1.000000,0.000000) [0.000000|18446744073709551616.000000] "" Vector__XXX

BO_ 2617239043 XCP_EMotor_01_DTO_03: 64 LE1
 SG_ XCP_EMotor_01_DTO_03_Data  : 0|64@1+ (1.000000,0.000000) [0.000000|18446744073709551616.000000] "" Vector__XXX

BO_ 2617239044 XCP_EMotor_01_DTO_04: 64 LE1
 SG_ XCP_EMotor_01_DTO_04_Data  : 0|64@1+ (1.000000,0.000000) [0.000000|18446744073709551616.000000] "" Vector__XXX

BO_ 2617122304 XCP_EMotor_02_CRO_01: 64 Vector__XXX
 SG_ XCP_EMotor_02_CRO_01_Data  : 0|64@1+ (1.000000,0.000000) [0.000000|18446744073709551616.000000] "" LE2

BO_ 2617122305 XCP_EMotor_02_DTO_01: 64 LE2
 SG_ XCP_EMotor_02_DTO_01_Data  : 0|64@1+ (1.000000,0.000000) [0.000000|18446744073709551616.000000] "" Vector__XXX

BO_ 2617122306 XCP_EMotor_02_DTO_02: 64 LE2
 SG_ XCP_EMotor_02_DTO_02_Data  : 0|64@1+ (1.000000,0.000000) [0.000000|18446744073709551616.000000] "" Vector__XXX

BO_ 2617122307 XCP_EMotor_02_DTO_03: 64 LE2
 SG_ XCP_EMotor_02_DTO_03_Data  : 0|64@1+ (1.000000,0.000000) [0.000000|18446744073709551616.000000] "" Vector__XXX

BO_ 2617122308 XCP_EMotor_02_DTO_04: 64 LE2
 SG_ XCP_EMotor_02_DTO_04_Data  : 0|64@1+ (1.000000,0.000000) [0.000000|18446744073709551616.000000] "" Vector__XXX

BO_ 2617226768 XCP_Motor_CRO_01: 64 Vector__XXX
 SG_ XCP_Motor_CRO_01_Data  : 0|64@1+ (1.000000,0.000000) [0.000000|18446744073709551616.000000] "" Motor_BEV

BO_ 2617226769 XCP_Motor_DTO_01: 64 Motor_BEV
 SG_ XCP_Motor_DTO_01_Data  : 0|64@1+ (1.000000,0.000000) [0.000000|18446744073709551616.000000] "" Vector__XXX

BO_ 1411 ZV_02: 8 ICAS1_Gateway
 SG_ ZV_verriegeln_Anf  : 0|1@1+ (1.000000,0.000000) [0.000000|1.000000] "" Vector__XXX
 SG_ ZV_STSG_HFS_Anf  : 1|1@1+ (1.000000,0.000000) [0.000000|1.000000] "" Vector__XXX
 SG_ ZV_STSG_HBFS_Anf  : 2|1@1+ (1.000000,0.000000) [0.000000|1.000000] "" Vector__XXX
 SG_ ZV_Anf_Challenge_Auth  : 3|1@1+ (1.000000,0.000000) [0.000000|1.000000] "" Vector__XXX
 SG_ BCM_FH_Freigabe  : 12|1@1+ (1.000000,0.000000) [0.000000|1.000000] "" Vector__XXX
 SG_ BCM_Komfortfkt_Freigabe  : 13|1@1+ (1.000000,0.000000) [0.000000|1.000000] "" Vector__XXX
 SG_ BCM_HSK_Freigabe  : 14|1@1+ (1.000000,0.000000) [0.000000|1.000000] "" Vector__XXX
 SG_ BCM_Verdeck_Freigabe  : 15|1@1+ (1.000000,0.000000) [0.000000|1.000000] "" Vector__XXX
 SG_ ZV_verriegelt_intern_ist  : 16|1@1+ (1.000000,0.000000) [0.000000|1.000000] "" Vector__XXX
 SG_ ZV_verriegelt_extern_ist  : 17|1@1+ (1.000000,0.000000) [0.000000|1.000000] "" Airbag
 SG_ ZV_verriegelt_intern_soll  : 18|1@1+ (1.000000,0.000000) [0.000000|1.000000] "" Vector__XXX
 SG_ ZV_verriegelt_extern_soll  : 19|1@1+ (1.000000,0.000000) [0.000000|1.000000] "" Airbag
 SG_ ZV_gesafet_extern_ist  : 20|1@1+ (1.000000,0.000000) [0.000000|1.000000] "" Vector__XXX
 SG_ ZV_gesafet_extern_soll  : 21|1@1+ (1.000000,0.000000) [0.000000|1.000000] "" Vector__XXX
 SG_ ZV_Einzeltuerentriegelung  : 22|1@1+ (1.000000,0.000000) [0.000000|1.000000] "" Vector__XXX
 SG_ ZV_Heckeinzelentriegelung  : 23|1@1+ (1.000000,0.000000) [0.000000|1.000000] "" Vector__XXX
 SG_ ZV_FT_offen  : 24|1@1+ (1.000000,0.000000) [0.000000|1.000000] "" Motor_BEV
 SG_ ZV_BT_offen  : 25|1@1+ (1.000000,0.000000) [0.000000|1.000000] "" Motor_BEV
 SG_ ZV_HFS_offen  : 26|1@1+ (1.000000,0.000000) [0.000000|1.000000] "" Motor_BEV
 SG_ ZV_HBFS_offen  : 27|1@1+ (1.000000,0.000000) [0.000000|1.000000] "" Motor_BEV
 SG_ ZV_HD_offen  : 28|1@1+ (1.000000,0.000000) [0.000000|1.000000] "" Motor_BEV
 SG_ ZV_HS_offen  : 29|1@1+ (1.000000,0.000000) [0.000000|1.000000] "" Vector__XXX
 SG_ IRUE_aktiv  : 30|1@1+ (1.000000,0.000000) [0.000000|1.000000] "" Vector__XXX
 SG_ DWA_aktiv  : 31|1@1+ (1.000000,0.000000) [0.000000|1.000000] "" Vector__XXX
 SG_ FFB_HDF_Taste  : 34|1@1+ (1.000000,0.000000) [0.000000|1.000000] "" Vector__XXX
 SG_ FFB_Panik_Taste  : 35|1@1+ (1.000000,0.000000) [0.000000|1.000000] "" Vector__XXX
 SG_ FFB_Auf_Taste  : 36|1@1+ (1.000000,0.000000) [0.000000|1.000000] "" Vector__XXX
 SG_ FFB_Zu_Taste  : 37|1@1+ (1.000000,0.000000) [0.000000|1.000000] "" Vector__XXX
 SG_ FFB_CarFinder  : 38|1@1+ (1.000000,0.000000) [0.000000|1.000000] "" Vector__XXX
 SG_ FFB_Komfortoeffnen  : 39|1@1+ (1.000000,0.000000) [0.000000|1.000000] "" Vector__XXX
 SG_ FFB_Komfortschliessen  : 40|1@1+ (1.000000,0.000000) [0.000000|1.000000] "" Vector__XXX
 SG_ FBS_IDG_in_Reichweite  : 41|1@1+ (1.000000,0.000000) [0.000000|1.000000] "" Vector__XXX
 SG_ ZV_Schluessel_Zugang  : 42|4@1+ (1.000000,0.000000) [0.000000|15.000000] "" Vector__XXX
 SG_ ZV_SafeFunktion_aktiv  : 46|1@1+ (1.000000,0.000000) [0.000000|1.000000] "" Vector__XXX
 SG_ FBS_Warn_Schluessel_Batt  : 47|1@1+ (1.000000,0.000000) [0.000000|1.000000] "" Vector__XXX
 SG_ ZV_Oeffnungsmodus  : 48|2@1+ (1.000000,0.000000) [0.000000|3.000000] "" Vector__XXX
 SG_ ZV_ist_Zustand_verfuegbar  : 54|1@1+ (1.000000,0.000000) [0.000000|1.000000] "" Vector__XXX
 SG_ IRUE_Taster_Fkts_LED  : 55|1@1+ (1.000000,0.000000) [0.000000|1.000000] "" Vector__XXX
 SG_ ZV_Tankklappe_offen  : 56|1@1+ (1.000000,0.000000) [0.000000|1.000000] "" Vector__XXX
 SG_ ZV_Rollo_auf  : 57|1@1+ (1.000000,0.000000) [0.000000|1.000000] "" Vector__XXX
 SG_ ZV_Rollo_zu  : 58|1@1+ (1.000000,0.000000) [0.000000|1.000000] "" Vector__XXX
 SG_ ZV_SAD_auf  : 59|1@1+ (1.000000,0.000000) [0.000000|1.000000] "" Vector__XXX
 SG_ ZV_SAD_zu  : 60|1@1+ (1.000000,0.000000) [0.000000|1.000000] "" Vector__XXX
 SG_ ZV_verriegelt_soll  : 62|2@1+ (1.000000,0.000000) [0.000000|3.000000] "" Vector__XXX

CM_ BO_ 1716 "200msbeiD4undfolgende";
CM_ BO_ 916 "ersetztWBA_02";
CM_ BO_ 2617239042 "abMQB";
CM_ BO_ 2617239043 "abMQB";
CM_ BO_ 2617239044 "abMQB";
CM_ SG_ 1019 TSK_Ausrollkurve_Schub_Reku_01 "DiesesSignalsendetdieStützstelle1derSchub-/Rekuausrollkurve.";
CM_ SG_ 1019 TSK_Ausrollkurve_Schub_Reku_05 "DiesesSignalsendetdieStützstelle5derSchub-/Rekuausrollkurve.";
CM_ SG_ 1019 TSK_Ausrollkurve_Schub_Reku_09 "DiesesSignalsendetdieStützstelle9derSchub-/Rekuausrollkurve.";
CM_ SG_ 1019 TSK_Ausrollkurve_Schub_Reku_13 "DiesesSignalsendetdieStützstelle13derSchub-/Rekuausrollkurve.";
CM_ SG_ 1019 TSK_Ausrollkurve_Schub_Reku_17 "DiesesSignalsendetdieStützstelle17derSchub-/Rekuausrollkurve.";
CM_ SG_ 1019 TSK_Ausrollkurve_Schub_Reku_02 "DiesesSignalsendetdieStützstelle2derSchub-/Rekuausrollkurve.";
CM_ SG_ 1019 TSK_Ausrollkurve_Schub_Reku_06 "DiesesSignalsendetdieStützstelle6derSchub-/Rekuausrollkurve.";
CM_ SG_ 1019 TSK_Ausrollkurve_Schub_Reku_10 "DiesesSignalsendetdieStützstelle10derSchub-/Rekuausrollkurve.";
CM_ SG_ 1019 TSK_Ausrollkurve_Schub_Reku_14 "DiesesSignalsendetdieStützstelle14derSchub-/Rekuausrollkurve.";
CM_ SG_ 1019 TSK_Ausrollkurve_Schub_Reku_18 "DiesesSignalsendetdieStützstelle18derSchub-/Rekuausrollkurve.";
CM_ SG_ 1019 TSK_Ausrollkurve_Schub_Reku_03 "DiesesSignalsendetdieStützstelle3derSchub-/Rekuausrollkurve.";
CM_ SG_ 1019 TSK_Ausrollkurve_Schub_Reku_07 "DiesesSignalsendetdieStützstelle7derSchub-/Rekuausrollkurve.";
CM_ SG_ 1019 TSK_Ausrollkurve_Schub_Reku_11 "DiesesSignalsendetdieStützstelle11derSchub-/Rekuausrollkurve.";
CM_ SG_ 1019 TSK_Ausrollkurve_Schub_Reku_15 "DiesesSignalsendetdieStützstelle15derSchub-/Rekuausrollkurve.";
CM_ SG_ 1019 TSK_Ausrollkurve_Schub_Reku_19 "DiesesSignalsendetdieStützstelle19derSchub-/Rekuausrollkurve.";
CM_ SG_ 1019 TSK_Ausrollkurve_Schub_Reku_04 "DiesesSignalsendetdieStützstelle4derSchub-/Rekuausrollkurve.";
CM_ SG_ 1019 TSK_Ausrollkurve_Schub_Reku_08 "DiesesSignalsendetdieStützstelle8derSchub-/Rekuausrollkurve.";
CM_ SG_ 1019 TSK_Ausrollkurve_Schub_Reku_12 "DiesesSignalsendetdieStützstelle12derSchub-/Rekuausrollkurve.";
CM_ SG_ 1019 TSK_Ausrollkurve_Schub_Reku_16 "DiesesSignalsendetdieStützstelle16derSchub-/Rekuausrollkurve.";
CM_ SG_ 1019 TSK_Ausrollkurve_Schub_Reku_20 "DiesesSignalsendetdieStützstelle20derSchub-/Rekuausrollkurve.";
CM_ SG_ 1019 TSK_Ausrollkurve_Segeln_01 "DiesesSignalsendetdieStützstelle1derSegelausrollkurve.";
CM_ SG_ 1019 TSK_Ausrollkurve_Segeln_05 "DiesesSignalsendetdieStützstelle5derSegelausrollkurve.";
CM_ SG_ 1019 TSK_Ausrollkurve_Segeln_09 "DiesesSignalsendetdieStützstelle9derSegelausrollkurve.";
CM_ SG_ 1019 TSK_Ausrollkurve_Segeln_13 "DiesesSignalsendetdieStützstelle13derSegelausrollkurve.";
CM_ SG_ 1019 TSK_Ausrollkurve_Segeln_17 "DiesesSignalsendetdieStützstelle17derSegelausrollkurve.";
CM_ SG_ 1019 TSK_Ausrollkurve_Segeln_02 "DiesesSignalsendetdieStützstelle2derSegelausrollkurve.";
CM_ SG_ 1019 TSK_Ausrollkurve_Segeln_06 "DiesesSignalsendetdieStützstelle6derSegelausrollkurve.";
CM_ SG_ 1019 TSK_Ausrollkurve_Segeln_10 "DiesesSignalsendetdieStützstelle10derSegelausrollkurve.";
CM_ SG_ 1019 TSK_Ausrollkurve_Segeln_14 "DiesesSignalsendetdieStützstelle14derSegelausrollkurve.";
CM_ SG_ 1019 TSK_Ausrollkurve_Segeln_18 "DiesesSignalsendetdieStützstelle18derSegelausrollkurve.";
CM_ SG_ 1019 TSK_Ausrollkurve_Segeln_03 "DiesesSignalsendetdieStützstelle3derSegelausrollkurve.";
CM_ SG_ 1019 TSK_Ausrollkurve_Segeln_07 "DiesesSignalsendetdieStützstelle7derSegelausrollkurve.";
CM_ SG_ 1019 TSK_Ausrollkurve_Segeln_11 "DiesesSignalsendetdieStützstelle11derSegelausrollkurve.";
CM_ SG_ 1019 TSK_Ausrollkurve_Segeln_15 "DiesesSignalsendetdieStützstelle15derSegelausrollkurve.";
CM_ SG_ 1019 TSK_Ausrollkurve_Segeln_19 "DiesesSignalsendetdieStützstelle19derSegelausrollkurve.";
CM_ SG_ 1019 TSK_Ausrollkurve_Segeln_04 "DiesesSignalsendetdieStützstelle4derSegelausrollkurve.";
CM_ SG_ 1019 TSK_Ausrollkurve_Segeln_08 "DiesesSignalsendetdieStützstelle8derSegelausrollkurve.";
CM_ SG_ 1019 TSK_Ausrollkurve_Segeln_12 "DiesesSignalsendetdieStützstelle12derSegelausrollkurve.";
CM_ SG_ 1019 TSK_Ausrollkurve_Segeln_16 "DiesesSignalsendetdieStützstelle16derSegelausrollkurve.";
CM_ SG_ 1019 TSK_Ausrollkurve_Segeln_20 "DiesesSignalsendetdieStützstelle20derSegelausrollkurve.";
CM_ SG_ 1019 TSK_Ausrollkurve_Mux "DiesesSignaldientalsMultiplexzählerfürdieSegel-bzw.Schub-/RekuAusrollkurve";
CM_ SG_ 1019 TSK_Ausrollkurve_Reku "DiesesSignalzeigtan,obbeiderSchub-/RekuausrollkurveaktuellRekuperationberücksichtigtwird.";
CM_ SG_ 1019 TSK_Ausrollkurve_Schrittweite "DiesesSignaldientdientzurUmschaltungderStützstellenschrittweitederSegel-bzw.Schub-/Rekuausrollkurve";
CM_ SG_ 1019 TSK_Ausrollkurve_Zaehler "DiesesSignalermöglichtdieUnterscheidungderAusrollkurven.EswirdnachdervollständigenÜbertragungeinerKennlinieinkrementiert.";
CM_ SG_ 1716 VIN_01_MUX "Achtung:
Die Botschaft ist nicht linear gemultiplext!!!
Sondern 0,1,0,2,0, usw.";
CM_ SG_ 1716 VIN_4 "Initwert:
0x2D bei Fahrzeugen mit Wegfahrsperrengeneration >= 5
0x58 bei Fahrzeugen mit Wegfahrsperrengeneration < 5 (z.B. WFS-4)";
CM_ SG_ 1716 VIN_11 "Initwert:
0x2D bei Fahrzeugen mit Wegfahrsperrengeneration >= 5
0x58 bei Fahrzeugen mit Wegfahrsperrengeneration < 5 (z.B. WFS-4)";
CM_ SG_ 1716 VIN_5 "Initwert:
0x2D bei Fahrzeugen mit Wegfahrsperrengeneration >= 5
0x58 bei Fahrzeugen mit Wegfahrsperrengeneration < 5 (z.B. WFS-4)";
CM_ SG_ 1716 VIN_12 "Initwert:
0x2D bei Fahrzeugen mit Wegfahrsperrengeneration >= 5
0x58 bei Fahrzeugen mit Wegfahrsperrengeneration < 5 (z.B. WFS-4)";
CM_ SG_ 1716 VIN_6 "Initwert:
0x2D bei Fahrzeugen mit Wegfahrsperrengeneration >= 5
0x58 bei Fahrzeugen mit Wegfahrsperrengeneration < 5 (z.B. WFS-4)";
CM_ SG_ 1716 VIN_13 "Initwert:
0x2D bei Fahrzeugen mit Wegfahrsperrengeneration >= 5
0x58 bei Fahrzeugen mit Wegfahrsperrengeneration < 5 (z.B. WFS-4)";
CM_ SG_ 1716 VIN_7 "Initwert:
0x2D bei Fahrzeugen mit Wegfahrsperrengeneration >= 5
0x58 bei Fahrzeugen mit Wegfahrsperrengeneration < 5 (z.B. WFS-4)";
CM_ SG_ 1716 VIN_14 "Initwert:
0x2D bei Fahrzeugen mit Wegfahrsperrengeneration >= 5
0x58 bei Fahrzeugen mit Wegfahrsperrengeneration < 5 (z.B. WFS-4)";
CM_ SG_ 1716 VIN_1 "Initwert:
0x2D bei Fahrzeugen mit Wegfahrsperrengeneration >= 5
0x58 bei Fahrzeugen mit Wegfahrsperrengeneration < 5 (z.B. WFS-4)";
CM_ SG_ 1716 VIN_8 "Initwert:
0x2D bei Fahrzeugen mit Wegfahrsperrengeneration >= 5
0x58 bei Fahrzeugen mit Wegfahrsperrengeneration < 5 (z.B. WFS-4)";
CM_ SG_ 1716 VIN_15 "Initwert:
0x2D bei Fahrzeugen mit Wegfahrsperrengeneration >= 5
0x58 bei Fahrzeugen mit Wegfahrsperrengeneration < 5 (z.B. WFS-4)";
CM_ SG_ 1716 VIN_2 "Initwert:
0x2D bei Fahrzeugen mit Wegfahrsperrengeneration >= 5
0x58 bei Fahrzeugen mit Wegfahrsperrengeneration < 5 (z.B. WFS-4)";
CM_ SG_ 1716 VIN_9 "Initwert:
0x2D bei Fahrzeugen mit Wegfahrsperrengeneration >= 5
0x58 bei Fahrzeugen mit Wegfahrsperrengeneration < 5 (z.B. WFS-4)";
CM_ SG_ 1716 VIN_16 "Initwert:
0x2D bei Fahrzeugen mit Wegfahrsperrengeneration >= 5
0x58 bei Fahrzeugen mit Wegfahrsperrengeneration < 5 (z.B. WFS-4)";
CM_ SG_ 1716 VIN_3 "Initwert:
0x2D bei Fahrzeugen mit Wegfahrsperrengeneration >= 5
0x58 bei Fahrzeugen mit Wegfahrsperrengeneration < 5 (z.B. WFS-4)";
CM_ SG_ 1716 VIN_10 "Initwert:
0x2D bei Fahrzeugen mit Wegfahrsperrengeneration >= 5
0x58 bei Fahrzeugen mit Wegfahrsperrengeneration < 5 (z.B. WFS-4)";
CM_ SG_ 1716 VIN_17 "Initwert:
0x2D bei Fahrzeugen mit Wegfahrsperrengeneration >= 5
0x58 bei Fahrzeugen mit Wegfahrsperrengeneration < 5 (z.B. WFS-4)";
CM_ SG_ 261 VMM_01_CRC "FürMLB:
Berechnung siehe Lastenheft 'Kommunikationsabsicherung für FlexRay und CAN'
Ab MQB und MLBevo:
Berechnung siehe Lastenheft 'End-to-End Kommunikationsabsicherung'

Endwerte siehe Begleitdokument 'S-PDU Kennungsfolgen'";
CM_ SG_ 261 VMM_01_BZ "4bitBotschaftszähler,wirdmitjederSendebotschaftinkrementiert";
CM_ SG_ 261 HMS_P_beibehalten_GE "FordertdasGetriebeaufinStellung'P'zubleiben.";
CM_ SG_ 261 VZM_Unterdrueckung_Antriebsmom "MitdiesemSignalwirddemTSKsignalisiertobeinpositivesAntriebsmomentangefordertwerdenkann.IneinerNotbremsungistdaspositiveAntriebsmomentzuunterdrücken.";
CM_ SG_ 261 HMS_halten_nicht_verfuegbar "RueckmeldungHMS-Teilfunktion'Halten'nichtverfuegbar.";
CM_ SG_ 261 HMS_parken_nicht_verfuegbar "RueckmeldungHMS-Teilfunktionen'Parken'nichtverfuegbar.";
CM_ SG_ 261 HMS_Anforderung_GE "FordertvomGetriebebestimmteSchaltstellungenan.";
CM_ SG_ 261 HMS_Systemstatus "ZeigtdenaktuellenSystemstatusdesHMSan.";
CM_ SG_ 261 HMS_Stillstand "DasSignalzeigt,basierendaufdenvierESP-Raddrehzahlinformatioen,gefiltertund/oderentprelltmehrstufigdenFahrzeuggeschwindigkeitszustandan.";
CM_ SG_ 261 HMS_aktives_System "Zeigtan,vonwelchemSystemdieAnforderunggeradeumgesetztwird.";
CM_ SG_ 261 VMM_Inkonsistenz_GE "Zeigtan,obdieKommunikationunddieAnforderungenplausibelsind.";
CM_ SG_ 261 VMM_Inkonsistenz_HVLM "RückmeldungInkonsistenzHVLM";
CM_ SG_ 261 HMS_Fehlerstatus "ZeigtdenFehlerstatusdesHaltemanagementsystemsHMSan.
Details zu den Werten 3/4:
3=Systemeinschränkung, Parken EPB oder GSG nicht möglich
4=Systemstörung bzw. Parken EPB und GSG nicht möglich  ";
CM_ SG_ 261 HMS_Index_Haltemoment "Zeigtan,obdasSummen-HMS_HaltemomenteinBremsmoment(bergab)odereinAntriebsmoment(bergauf)darstellt.";
CM_ SG_ 261 HMS_Haltemoment "ZeigtinAbhängigkeitvonHMS_Index_HaltemomentdasnotwendigeSummen-Radmomentan(bergab:Bremsmoment;bergauf:Antriebsmoment),dasmindestensnotwendigistumdasFahrzeuganderaktuellenNeigungzuhalten.";
CM_ SG_ 313 VMM_02_CRC "FürMLB:
Berechnung siehe Lastenheft 'Kommunikationsabsicherung für FlexRay und CAN'
Ab MQB und MLBevo:
Berechnung siehe Lastenheft 'End-to-End Kommunikationsabsicherung'

Endwerte siehe Begleitdokument 'S-PDU Kennungsfolgen'";
CM_ SG_ 313 VMM_02_BZ "4bitBotschaftszähler,wirdmitjederSendebotschaftinkrementiert";
CM_ SG_ 313 VZM_aktiver_Basisservice "IndiesemSignalwirdderaktiveBasisservicedesVerzögerungsmanagementzurückgegeben.";
CM_ SG_ 313 VZM_Anhalteweg_nicht_verfuegbar "RückmeldungobdieAnhaltewegregelungverfügbarist.";
CM_ SG_ 313 VZM_Fahrer_bremst "BitwirdgesetztbeimÜberschreitenderBremsdruckschwelle

Weiterführende Informationen im Lastenheft spezifiziert und in der entsprechenden Fachabteilung zu erfragen.";
CM_ SG_ 313 VZM_QBit_Fahrer_bremst "GültigkeitderBremsdruckschwelleninformationdesSignalsVZM_Fahrer_bremstundVZM_Fahrer_bremst_deutlich
0x1 = Druckschwelleninformation kann noch nicht oder aufgrund eines Fehlers nicht ausgegeben werden";
CM_ SG_ 313 VMM_MKB_codiert "DasSignalkennzeichnetdenCodierstatusdesESC-SGbzgl.derFunktionMultikollisionsbremse.";
CM_ SG_ 313 VMM_Inkonsistenz_EBKV "RückmeldungInkonsistenzEBKV";
CM_ SG_ 313 VMM_Notstopp_Status "StatusdesNotstoppsystems";
CM_ SG_ 313 VZM_Warnruck_nicht_verfuegbar "RückmeldungobeineinfacherWarnruckangefordertwerdenkann.";
CM_ SG_ 313 VZM_Warnruckeln_nicht_verfuegbar "RückmeldungobmehrfacheinWarnruckdurchgeführtwerdenkann.";
CM_ SG_ 313 VZM_Bkd_nicht_verfuegbar "DiesesSignalgibteineRückmeldungobeineBremsenkonditionierung(PrefillundSystemtotzeitminimierung)verfügbarist.";
CM_ SG_ 313 VMM_Bremslicht_defekt "RückmeldungobbeideBremslichterdefektsind.BeigestecktemAnhängerwerdendieAnhängerbremslichterausgewertet.";
CM_ SG_ 313 VZM_Fahrer_bremst_deutlich "RückmeldunganAWVobderFahrerdasBremspedaldeutlichbetätigthat";
CM_ SG_ 313 VZM_TSK_SRBM_Anf "QuittierungfürTSK(SRBM=Summenradbremsmoment)Anforderung";
CM_ SG_ 313 VZM_TSK_SRBM_nicht_verfuegbar "RückmeldungobdaseinSummenradbremsmomentangefordertwerdenkann.";
CM_ SG_ 313 VZM_Verz_Reg_aktiv "RueckmeldungVerzoegerungsregelungaktiv";
CM_ SG_ 313 VZM_Verz_Reg_nicht_verfuegbar "IndiesemSignalwirdausgegebenobeineVerzögerungsregelungverfügbarist.";
CM_ SG_ 313 VMM_Inkonsistenz_KAS "RückmeldungInkonsistenzKAS";
CM_ SG_ 313 VMM_Bremslicht_unplausibel "BremslichtplausibilitätausBasisderCANAnforderung";
CM_ SG_ 313 VMM_Inkonsistenz_ACC "RückmeldungInkonsistenzACC";
CM_ SG_ 313 VMM_Inkonsistenz_AWV_PCF "RückmeldungInkonsistenzAWVPCF";
CM_ SG_ 313 VMM_Inkonsistenz_ARA "RückmeldungInkonsistenzARA1.0";
CM_ SG_ 313 VMM_Inkonsistenz_ParkAssist "RückmeldungInkonsistenzderParkendenSysteme";
CM_ SG_ 313 VMM_Inkonsistenz_FAS_VK "RückmeldungInkonsistenzFahrerassistenzsystem";
CM_ SG_ 313 VMM_Inkonsistenz_NV "RückmeldungInkonsistenzNightvision";
CM_ SG_ 313 VMM_Inkonsistenz_RCTA "RückmeldungInkonsistenzdesRCTA";
CM_ SG_ 313 VMM_Inkonsistenz_TSK "RückmeldungInkonsistenzTSK";
CM_ SG_ 313 VMM_Inkonsistenz_MO "RückmeldungInkonsistenzMO";
CM_ SG_ 313 VMM_Inkonsistenz_AEB "RückmeldungInkonsistenzvomAEB";
CM_ SG_ 313 VMM_Fahrer_Bremskraft_bestimmend "DiesesSignalgibteineRückmeldungobderFahrerstärkerbremstalsdieangeforderteBremsung.";
CM_ SG_ 313 VMM_Inkonsistenz_EA "RückmeldungInkonsistenzEA";
CM_ SG_ 313 VZM_Status_Wegregelung "RückmeldungderWegregelungobdieserServiceInaktiv,aktivoderpassivist.
Bei Passiv_Überwachend Bremseingriff durch VZM im Notfall möglich.";
CM_ SG_ 313 VZM_Verz_ASIL_Verfuegbarkeit "DiesesSignalgibtdieRückmeldunginwelchemASILBereichaktuellverzögertwird.";
CM_ SG_ 313 VZM_aktives_System "RückmeldungüberdasaktivanforderndeSystembeidemVerzögerungsmanagement.";
CM_ SG_ 313 VZM_Verz_Begrenzung "RückmeldungangeforderteVerzögerungoderSummenradbremsmomentwirdbegrenztumgesetzt";
CM_ SG_ 313 VZM_Systemstatus "IndiesemSignalwirdderaktuelleSystemstatusdesVerzögerungsmanagmentsausgeben.";
CM_ SG_ 313 VZM_SRBM_Soll "GibtdasangeforderteSummenradbremsmomentaus.";
CM_ SG_ 313 VZM_SRBM_Ist "GibtdasaktuelleSummenradbremsmomentaus.";
CM_ SG_ 313 VZM_SRBM_max_Gradient "RückmeldungaktuellerMaximalgradient";
CM_ SG_ 313 VMM_Inkonsistenz_KAM "RückmeldungInkonsistenzderKamera";
CM_ SG_ 2463978663 VZE_Anzeigemodus "SteuertdieverschiedenenMöglichkeitenderAnzeige.";
CM_ SG_ 2463978663 VZE_Hinweistext "ÜberIndexwirdeinHinweistextbeschrieben,derdurchdasKombidargestelltewerdensoll.

Wertebereich lt. Hashtabelle";
CM_ SG_ 2463978663 VZE_Verkehrszeichen_Einheit "SignalgibtanobdasübertrageneVerkehrszeicheninmphoderkm/hübermitteltwird";
CM_ SG_ 2463978663 VZE_Anzeigeunterdrueck_Zeichen_3 "AnzeigerelevanzdesZeichensinVZE_Verkehrszeichen_3";
CM_ SG_ 2463978663 VZE_Anzeigeunterdrueck_Zeichen_2 "AnzeigerelevanzdesZeichensinVZE_Verkehrszeichen_2";
CM_ SG_ 2463978663 VZE_Verkehrszeichen_1 "DasSignalspiegelteinesderVerkehrszeichen:Geschwindigkeitsgebot,Überholverbot,Aufhebungszeichenwider.

Wertebereich lt. Hashtabelle";
CM_ SG_ 2463978663 VZE_Verkehrszeichen_2 "DasSignalspiegelteinesderVerkehrszeichen:Geschwindigkeitsgebot,Überholverbot,Aufhebungszeichenwider.

Wertebereich lt. Hashtabelle";
CM_ SG_ 2463978663 VZE_Verkehrszeichen_3 "DasSignalspiegelteinesderVerkehrszeichen:Geschwindigkeitsgebot,Überholverbot,Aufhebungszeichenwider.

Wertebereich lt. Hashtabelle";
CM_ SG_ 2463978663 VZE_Warnung_Verkehrszeichen_1 "IstdasSignalgesetzt,soistfürdasVerkehrszeichen1eineWarnungauszugeben.";
CM_ SG_ 2463978663 VZE_Warnung_Verkehrszeichen_2 "IstdasSignalgesetzt,soistfürdasVerkehrszeichen2eineWarnungauszugeben.";
CM_ SG_ 2463978663 VZE_Warnung_Verkehrszeichen_3 "IstdasSignalgesetzt,soistfürdasVerkehrszeichen3eineWarnungauszugeben.";
CM_ SG_ 2463978663 VZE_Zusatzschild_1 "Zusatzsschild,daszuVerkehrszeichen1angezeigtwerdensoll.

Wertebereich lt. Hashtabelle";
CM_ SG_ 2463978663 VZE_Zusatzschild_2 "Zusatzsschild,daszuVerkehrszeichen2angezeigtwerdensoll.

Wertebereich lt. Hashtabelle";
CM_ SG_ 2463978663 VZE_Zusatzschild_3 "Zusatzsschild,daszuVerkehrszeichen3angezeigtwerdensoll.

Wertebereich lt. Hashtabelle";
CM_ SG_ 2463978663 VZE_Anzeigeunterdrueck_Zeichen_1 "SteuerungssignalzurSteuerungderSichtbarkeitvonVerkehrszeichen";
CM_ SG_ 2463978663 VZE_Zeichen_01_KameraWied "DasVZE-TempolimitinVerkehrszeichen1wurdealsWiederholungsschildvonderKameraerkannt.";
CM_ SG_ 2463978663 VZE_Zeichen_02_KameraWied "DasVZE-TempolimitinVerkehrszeichen2wurdealsWiederholungsschildvonderKameraerkannt.";
CM_ SG_ 2463978663 VZE_Zeichen_03_KameraWied "DasVZE-TempolimitinVerkehrszeichen3wurdealsWiederholungsschildvonderKameraerkannt.";
CM_ SG_ 2463978663 VZE_Zeichen_01_Kamera "DasVZE-TempolimitinVerkehrszeichen1wurdevonderKameraerkannt.";
CM_ SG_ 2463978663 VZE_Zeichen_01_Karte "DasVZE-TempolimitinVerkehrszeichen1stammtausdenNavigationskartendaten.";
CM_ SG_ 2463978663 VZE_Zeichen_01_Gesetz "DasVZE-TempolimitinVerkehrszeichen1istdasgesetzlichgeltendeTempolimit(jeLand/Straßenklasse).";
CM_ SG_ 2463978663 VZE_Zeichen_02_Kamera "DasVZE-TempolimitinVerkehrszeichen2wurdevonderKameraerkannt.";
CM_ SG_ 2463978663 VZE_Zeichen_02_Karte "DasVZE-TempolimitinVerkehrszeichen2stammtausdenNavigationskartendaten.";
CM_ SG_ 2463978663 VZE_Zeichen_02_Gesetz "DasVZE-TempolimitinVerkehrszeichen2istdasgesetzlichgeltendeTempolimit(jeLand/Straßenklasse).";
CM_ SG_ 2463978663 VZE_Zeichen_03_Kamera "DasVZE-TempolimitinVerkehrszeichen3wurdevonderKameraerkannt.";
CM_ SG_ 2463978663 VZE_Zeichen_03_Karte "DasVZE-TempolimitinVerkehrszeichen3stammtausdenNavigationskartendaten.";
CM_ SG_ 2463978663 VZE_Zeichen_03_Gesetz "DasVZE-TempolimitinVerkehrszeichen3istdasgesetzlichgeltendeTempolimit(jeLand/Straßenklasse).";
CM_ SG_ 2463978663 VZE_Gong "DasSignalsignalisiertdemKombiinstrumentobbeiderVZE-TempowarnungeinGonggetriggertwerdensoll.";
CM_ SG_ 2463978663 VZE_Anzeigeunterdrueck_Zeichen_5 "AnzeigerelevanzdesZeichensinVZE_Anzeigerelevanz_Zeichen_5";
CM_ SG_ 2463978663 VZE_Zeichen_05_KameraWied "DasVZE-TempolimitwurdealsWiederholungsschildvonderKameraerkannt.";
CM_ SG_ 2463978663 VZE_Zeichen_05_Kamera "DasVZE-TempolimitwurdevonderKameraerkannt.";
CM_ SG_ 2463978663 VZE_Verkehrszeichen_4 "DasSignalspiegelteinesderVerkehrszeichen:Geschwindigkeitsgebot,Überholverbot,Aufhebungszeichenwider.

Wertebereich lt. Hashtabelle";
CM_ SG_ 2463978663 VZE_Verkehrszeichen_5 "DasSignalspiegelteinesderVerkehrszeichen:Geschwindigkeitsgebot,Überholverbot,Aufhebungszeichenwider.

Wertebereich lt. Hashtabelle";
CM_ SG_ 2463978663 VZE_Anhaenger_Vmax "ÜbertragungderausKundeneinstellungundländerspezifischenRegelungen(StVO,Rechtsprechung...)berechnetenlegalenHöchstgeschwindigkeitfürdasGespann.

10+ 0*10 = 10 km/h
10+ 1*10 = 20 km/h
...
10+ 5*10 = 60 km/h
10+ 6*10 = 70 km/h
...
10+ 1";
CM_ SG_ 2463978663 VZE_Zeichen_04_Gesetz "DasVZE-TempolimitistdasgesetzlichgeltendeTempolimit(jeLand/Straßenklasse).";
CM_ SG_ 2463978663 VZE_Zeichen_04_Kamera "DasVZE-TempolimitwurdevonderKameraerkannt.";
CM_ SG_ 2463978663 VZE_Zeichen_04_KameraWied "DasVZE-TempolimitwurdealsWiederholungsschildvonderKameraerkannt.";
CM_ SG_ 2463978663 VZE_Zeichen_04_Karte "DasVZE-TempolimitstammtausdenNavigationskartendaten.";
CM_ SG_ 2463978663 VZE_Warnung_Verkehrszeichen_4 "IstdasSignalgesetzt,soistfürdasVerkehrszeichen4eineWarnungauszugeben.";
CM_ SG_ 2463978663 VZE_Warnung_Verkehrszeichen_5 "IstdasSignalgesetzt,soistfürdasVerkehrszeichen5eineWarnungauszugeben.";
CM_ SG_ 2463978663 VZE_Zeichen_05_Gesetz "DasVZE-TempolimitistdasgesetzlichgeltendeTempolimit(jeLand/Straßenklasse).";
CM_ SG_ 2463978663 VZE_Zusatzschild_4 "Zusatzsschild,daszuVerkehrszeichen4angezeigtwerdensoll.

Wertebereich lt. Hashtabelle";
CM_ SG_ 2463978663 VZE_Zusatzschild_5 "Zusatzsschild,daszuVerkehrszeichen5angezeigtwerdensoll.

Wertebereich lt. Hashtabelle";
CM_ SG_ 2463978663 VZE_Baustelle "DasSignalgibtan,obaktuelleinBaustellenschildvonderVZEerkanntwurde.";
CM_ SG_ 2463978663 VZE_Zeichen_05_Karte "DasVZE-TempolimitstammtausdenNavigationskartendaten.";
CM_ SG_ 2463978663 VZE_Zeichen_05_Entfernung "IndemSignalwirddieEntfernungzumVerkehrszeichen5übertragen";
CM_ SG_ 2463978663 VZE_Zeichen_05_Entfernung_StdA "IndemSignalwirddieStandardabweichungbzgl.derEntfernungzumVerkehrszeichen5übertragen";
CM_ SG_ 2463978663 VZE_Anzeigeunterdrueck_Zeichen_4 "AnzeigerelevanzdesZeichensinVZE_Anzeigerelevanz_Zeichen_4";
CM_ SG_ 2463978663 VZE_Verkehrszeichen_6 "DasSignalspiegelteinesderVerkehrszeichen:Geschwindigkeitsgebot,Überholverbot,Aufhebungszeichenwider.

Wertebereich lt. Hashtabelle";
CM_ SG_ 2463978663 VZE_Zusatzschild_6 "Zusatzsschild,daszuVerkehrszeichen6angezeigtwerdensoll.

Wertebereich lt. Hashtabelle";
CM_ SG_ 2463978663 VZE_Zeichen_06_Entfernung "IndemSignalwirddieEntfernungzumVerkehrszeichen6übertragen";
CM_ SG_ 2463978663 VZE_Zeichen_06_Entfernung_StdA "IndemSignalwirddieStandardabweichungbzgl.derEntfernungzumVerkehrszeichen6übertragen";
CM_ SG_ 2463978663 VZE_Umweltinfo_Naesse "IndemSignalwerdenfürdieVerkehrszeichenerkennungrelevanteUmweltinformationenübertragen.

Info: Nässe";
CM_ SG_ 2463978663 VZE_Umweltinfo_Nebel "IndemSignalwerdenfürdieVerkehrszeichenerkennungrelevanteUmweltinformationenübertragen.

Info: Nebel";
CM_ SG_ 2463978663 VZE_Umweltinfo_Anhaengerbetrieb "IndemSignalwerdenfürdieVerkehrszeichenerkennungrelevanteUmweltinformationenübertragen.

Info: Anhängerbetrieb";
CM_ SG_ 2463978663 VZE_Erweiterte_Information "IndemSignalspiegelterweiterteVerkehrszeicheninformationenwieder(Ortsschild,Autobahnbeginn,Autobahnende)

Wertebereich lt. Hashtabelle";
CM_ SG_ 2463978663 VZE_Tempowarnung_Status "0-Tempowarnungaktiv
1 -  Tempowarnung desktiv";
CM_ SG_ 2463978663 VZE_Tempowarnung_Einheit "0-EinheitWarnoffsetkm/h
1 -  Einheit Warnoffset mph";
CM_ SG_ 2463978663 VZE_Tempowarnung_Offset "dasSignalüberträgtdenimCAR:MenügewähltenOffsetfürdieVZE-TempowarnungandaspACCSteuergerät.DiezugrhörigeEinheitwirdimSignalVZE_Tempowarnung_Einheitübertragen";
CM_ SG_ 2463978663 VZE_FoD_Status "StatusderVZEfürFoD";
CM_ SG_ 2463978663 VZE_Anzeige_ZS_1 "Zusatzsschild,daszuVerkehrszeichen1angezeigtwerdensoll.

Wertebereich lt. Hashtabelle";
CM_ SG_ 2463978663 VZE_Anzeige_ZS_2 "Zusatzsschild,daszuVerkehrszeichen1angezeigtwerdensoll.

Wertebereich lt. Hashtabelle";
CM_ SG_ 2463978663 VZE_Anzeige_ZS_3 "Zusatzsschild,daszuVerkehrszeichen1angezeigtwerdensoll.

Wertebereich lt. Hashtabelle";
CM_ SG_ 2463978663 VZE_Hinweistext_03 "ÜberIndexwirdeinHinweistextbeschrieben,derdurchdasKombidargestelltewerdensoll.

Wertebereich lt. Hashtabelle";
CM_ SG_ 2463978663 VZE_Land "SteuertdieverschiedenenMöglichkeitenderAnzeige.";
CM_ SG_ 2463978663 VZE_Warnung_VZ_1 "IstdasSignalgesetzt,soistfürdasVerkehrszeichen1eineWarnungauszugeben.";
CM_ SG_ 2463978663 VZE_Warnung_VZ_2 "IstdasSignalgesetzt,soistfürdasVerkehrszeichen1eineWarnungauszugeben.";
CM_ SG_ 2463978663 VZE_Warnung_VZ_3 "IstdasSignalgesetzt,soistfürdasVerkehrszeichen1eineWarnungauszugeben.";
CM_ SG_ 2463978663 VZE_Anzeige_VZ_1 "DasSignalspiegelteinesderVerkehrszeichen:Geschwindigkeitsgebot,Überholverbot,Aufhebungszeichenwider.

Wertebereich lt. Hashtabelle";
CM_ SG_ 2463978663 VZE_Anzeige_VZ_2 "DasSignalspiegelteinesderVerkehrszeichen:Geschwindigkeitsgebot,Überholverbot,Aufhebungszeichenwider.

Wertebereich lt. Hashtabelle";
CM_ SG_ 2463978663 VZE_Anzeige_VZ_3 "DasSignalspiegelteinesderVerkehrszeichen:Geschwindigkeitsgebot,Überholverbot,Aufhebungszeichenwider.

Wertebereich lt. Hashtabelle";
CM_ SG_ 181 Waehlhebel_04_CRC "FürMLB:
'Berechnung siehe Lastenheft 'Kommunikationsabsicherung für FlexRay und CAN''

Ab MQB und MLBevo:
'Berechnung siehe Lastenheft 'End-to-End Kommunikationsabsicherung''

Endwerte siehe Begleitdokument 'S-PDU Kennungsfolgen'";
CM_ SG_ 181 WH_gespeicherte_Fahrstufe "Kurzzeit-FahrstufenspeicherunginAbhängigkeitvonGE_Ist_Fahrstufe.";
CM_ SG_ 181 WH_Initialisierung "DasBitzeigtdemEmpfängeran,dassderWählhebelinderInitialisierungist(z.B.Reset).DasSignalstehtfürmaximal500msabSendebeginnauf1,danachdauerhaftauf0.";
CM_ SG_ 181 WH_SensorPos_roh "ZustandWählhebelposition.WirddasSignalWH_Variantenichtbedient,istdieSignalcodierung
wie im MQB zu verwenden.

MQB:
0=Init
1=Position_1
2=Position_2
3=Position_3
4=nicht_betaetigt
5=Position_D
6=Position_N
7=Position_R
8=Position_P
";
CM_ SG_ 181 WH_SensorPos_roh_inv "ZustandWählhebelposition.WirddasSignalWH_Variantenichtbedient,istdieSignalcodierung
wie im MQB zu verwenden.

MQB:
0=Fehler
1=Position_Tipp_Gasse
2=Position_L
3=Position_S
4=Position_Tipp_-
5=Position_Tipp_+
6=Position_N_ohne_Spotausl";
CM_ SG_ 181 WH_Testergebnis "Ergebnis(Antwort)desControllertestsinitiertdurchTestFreigabeFlag
und Testparameter 1 + 2";
CM_ SG_ 181 WH_Test_Aktiv "DasBitwirdauf1gesetzt,wenneingültigesTestergebnis(Antwort)gesendetwird.";
CM_ SG_ 181 WH_Ist_Haltemagnet "StatusderAnsteuerungdesParksperren-HaltemagnetenimWaehlhebel";
CM_ SG_ 181 WH_Variante "VerwendeteSchaltungs-VarianteimFahrzeug
Beschreibung:

Rastierter Wählhebel
Übermittlung Absolutpositionen P,R,N,D,S,M

Tasten:
Übermittlung Absolutpositionen P,R,N,D

Monostabil_2x2:
Übermittlung Relativpositionen, Entsperrtaste und P-Taste";
CM_ SG_ 181 WH_Entsperrtaste_02 "DasBitzeigtdenentprelltenStatusderEntsperrtasteamWählhebelan,inklusiveFehler-undInit-Zuständen.";
CM_ SG_ 181 WH_P_Taste "DasSignalzeigtdenStatusderP-Tastean.";
CM_ SG_ 181 WH_Ende_N_Haltephase "SignalisiertdemGetriebe/ASGdasEndederN-Haltephase,damitdieParksperreeingelegtwerdenkann.";
CM_ SG_ 181 WH_Fahrstufe "FahrstufenwunschderSchaltbetätigung(berechnetausFahreraktionamBedienelement)";
CM_ SG_ 181 WH_Status_Shiftlock "StatusdesHardware-Shiftlocks(dieSchaltbetätigungkanninPoderNgesperrtwerden)";
CM_ SG_ 181 WH_Zustand_N_Haltephase "SignalisiertdemSchaltbetätigungsmaster(GSGbzw.ASG),inwelchemZustandsichdieN-HaltephaseinderSchaltbetätigungbefindet.AbhängigdavonfordertderSchaltbetätigungsmsterPanoderbehältNbei.";
CM_ SG_ 2463978687 WH_Fehler_Haltemagnet_Status "StatusdesTests'ElektrischerFehlerHaltemagnetansteuerung'";
CM_ SG_ 2463978687 WH_Fehler_CRC_SBM "FehlerderChecksummedesSchaltbetätigungsmasterserkannt";
CM_ SG_ 2463978687 WH_Fehler_CRC_SBM_Status "StatusdesTests'FehlerderChecksummedesSchaltbetätigungsmasterserkannt'";
CM_ SG_ 2463978687 WH_Fehler_Timeout_SBM "TimeoutdesSchaltbetätigungsmasterserkannt";
CM_ SG_ 2463978687 WH_Fehler_Timeout_SBM_Status "StatusdesTests'TimeoutdesSchaltbetätigungsmasterserkannt'";
CM_ SG_ 2463978687 WH_Fehler_Ueberspannung "Ueberspannungsfehlererkannt";
CM_ SG_ 2463978687 WH_Fehler_Ueberspannung_Status "StatusdesTests'Ueberspannungsfehlererkannt'";
CM_ SG_ 2463978687 WH_Fehler_BZ_SBM "FehlerdesBotschaftszählersdesSchaltbetätigungsmasterserkannt";
CM_ SG_ 2463978687 WH_Fehler_BZ_SBM_Status "StatusdesTests'FehlerdesBotschaftszählersdesSchaltbetätigungsmasterserkannt'";
CM_ SG_ 2463978687 WH_Fehler_Unterspannung "Unterspannungsfehlererkannt";
CM_ SG_ 2463978687 WH_Fehler_Unterspannung_Status "StatusdesTests'Unterspannungsfehlererkannt'";
CM_ SG_ 2463978687 WH_Fehler_Ausleuchtung "FehlerinderAusleuchtungderFahrstufeerkannt";
CM_ SG_ 2463978687 WH_Fehler_Ausleuchtung_Status "StatusdesTests'FehlerinderAusleuchtungderFahrstufeerkannt'";
CM_ SG_ 2463978687 WH_Fehler_Entsperrtaste "FehlerderEntsperrtasteerkannt";
CM_ SG_ 2463978687 WH_Fehler_Entsperrtaste_Status "StatusdesTests'FehlerderEntsperrtasteerkannt'";
CM_ SG_ 2463978687 WH_Fehler_P_Taste "FehlerderP-Tasteerkannt";
CM_ SG_ 2463978687 WH_Fehler_P_Taste_Status "StatusdesTests'FehlerderP-Tasteerkannt'";
CM_ SG_ 2463978687 WH_Fehler_Sensor_einfach "EinfacherPositionssensorfehlererkannt";
CM_ SG_ 2463978687 WH_Fehler_Sensor_einfach_Status "StatusdesTests'einfacherPositionssensorfehlererkannt'";
CM_ SG_ 2463978687 WH_Fehler_Sensor_mehrfach "MehrfacherPositionssensorfehlererkannt";
CM_ SG_ 2463978687 WH_Fehler_Sensor_mehrfach_Status "StatusdesTests'mehrfacherPositionssensorfehlererkannt'";
CM_ SG_ 2463978687 WH_Fehler_Shiftlock "FehlerHardware-Shiftlockerkannt";
CM_ SG_ 2463978687 WH_Fehler_Shiftlock_Status "StatusdesTests'FehlerHardware-Shiftlockerkannt'";
CM_ SG_ 916 WBA_03_CRC "FürMLB:
'Berechnung siehe Lastenheft 'Kommunikationsabsicherung für FlexRay und CAN''

Ab MQB und MLBevo:
'Berechnung siehe Lastenheft 'End-to-End Kommunikationsabsicherung''

Endwerte siehe Begleitdokument 'S-PDU Kennungsfolgen'";
CM_ SG_ 916 WBA_Fahrstufe_02 "BeiAutomatgetriebenwirdindiesemSignaldieaktuelleanzuzeigendeFahrstufeausgegeben.

Die Signalkodierungen 0x9, 0xA und 0xB werden im MSS-R8NF und MQB-A1/B/A2 verwendet.

Die Signalkodierungen 0xC und 0xD werden nur im MQB-A1/B/A2 verwendet.
";
CM_ SG_ 916 WBA_ZielFahrstufe "Zielfahrprogramm(Darstellung),fürgetipptesS/E/MmitneuemWählhebelimMQB";
CM_ SG_ 916 WBA_GE_Warnung_02 "PrioritätswarnungenGetriebe";
CM_ SG_ 916 WBA_eing_Gang_02 "DasAutomatikgetriebegibtdenaktuelleingelegtenGangaus.
Besonderheiten:
0x0 = marktabhängig wird auf Ganganzeige zur Fahrstufe komplett verzichtet
0xA = kurzzeitige Unterdrückung der Ganganzeige (z. B. Segeln, Zwischenstellung, etc.)";
CM_ SG_ 916 WBA_GE_Texte "FahrerhinweisefürdasKombi";
CM_ SG_ 916 WBA_Segeln_aktiv "GetriebegehtindenSegelbetrieb";
CM_ SG_ 916 WBA_Schaltschema_02 "Basis-LayoutdesSchaltschemaszurAnzeigeimKombiinstrument";
CM_ SG_ 916 WBA_Schaltschema_FS_inaktiv "Gibtan,welcheFahrstufeninnerhalbvonWBA_Schaltschema_02aktuellnichterreichbarsind(z.B.aufgrundzuhoherFahrzeuggeschwindigkeitoderfehlenderFahrbereitschaft).";
CM_ SG_ 916 WBA_GE_Zusatzwarnungen "PrioritaetswarnungenGetriebeanKombi
Audi MLB Wertebereich 0 bis 3
VW MQB Projekte verwenden nur den Wertebereich 0 bis 2
VW MQB Getriebefehler werden über das Signal  GE_Warnungen_02 gesendet.";
CM_ SG_ 916 GE_Sollgang "SignalisiertdenSollgang,indengetipptwerdensoll.AbhängigvomSignal'WBA_eing_Gang_02'unddemSollgangkanndanndasKombidieHochschaltempfehlunginTipdarstellen.";
CM_ SG_ 916 GE_Tipschaltempf_verfuegbar "Signalisierung,obeineHochschaltempfehlungimTipmodusverfügbaristodernicht.";
CM_ SG_ 916 WBA_GE_Texte_02 "FahrerhinweisefürdasKombi";
CM_ SG_ 916 WBA_Schaltschema_Tippgasse "ZeigtdenVerbaueinerTippgassezurAnzeigeimSchaltschemaan.";
CM_ SG_ 916 WBA_Schaltschema_Fahreraktion "SignalisiertFahreraktionanderSchaltbetaetigung";
CM_ SG_ 916 WBA_Schaltschema_FS_vorwaerts "Zeigtan,welchederzweiVorwärtsfahrstufenaktivistundobindieinaktivegeschaltetwerdenkann.";
CM_ SG_ 916 WBA_Shiftlock_Lampe "SignalisiertdemKombi,dassdieShiftlock-Lampe(grünes'Bremsetreten'Symbol)anzuzeigenist.

Anmerkung: Signal ist nur von Kombis auszuwerten, die die Shiftlock-Info über Soft- oder Hard-LED und nicht als reine Textmeldung anzeigen.";
CM_ SG_ 916 WBA_Anforderung_Akustik "AnforderungeinesSignaltonsbeiAnwahlderFahrstufeR";
CM_ SG_ 916 WBA_Blinken "DiesesBitsteuertdieFehlerlampeanoderwirdzumBlinkenderWBA-Anzeigegenutzt-nurfallsWBA_Senderkennung=00(GSG)
";
CM_ SG_ 916 GE_Wiederstart_Anz_Std "DiesesSignalgibtdiedetaillierteBegründungfüreinenWiederstartvomGetriebesteuergerätan.";
CM_ SG_ 916 GE_Stoppverbot_Anz_01 "DiesesSignalgibtdiedetaillierteBegründungfüreinStoppverbotvomGetriebesteuergerätan.";
CM_ SG_ 916 GE_Stoppverbot_Anz_02 "DiesesSignalgibtdiedetaillierteBegründungfüreinStoppverbotvomGetriebesteuergerätan.";
CM_ SG_ 916 GE_Stoppverbot_Anz_03 "DiesesSignalgibtdiedetaillierteBegründungfüreinStoppverbotvomGetriebesteuergerätan.";
CM_ SG_ 916 GE_Stoppverbot_Anz_04 "DiesesSignalgibtdiedetaillierteBegründungfüreinStoppverbotvomGetriebesteuergerätan.";
CM_ SG_ 916 GE_Stoppverbot_Anz_05 "DiesesSignalgibtdiedetaillierteBegründungfüreinStoppverbotvomGetriebesteuergerätan.";
CM_ SG_ 916 GE_Stoppverbot_Anz_06 "DiesesSignalgibtdiedetaillierteBegründungfüreinStoppverbotvomGetriebesteuergerätan.";
CM_ SG_ 916 GE_Stoppverbot_Anz_07 "DiesesSignalgibtdiedetaillierteBegründungfüreinStoppverbotvomGetriebesteuergerätan.";
CM_ SG_ 916 GE_Stoppverbot_Anz_Std "DiesesSignalgibtdiedetaillierteBegründungfüreinStoppverbotvomGetriebesteuergerätan.";
CM_ SG_ 1361 WFS_Schluessel_Fahrberecht "SchlüsselnummerFahrberechtigung
0 = ungueltig, xxxx = Schluessel-Nr.";
CM_ SG_ 1361 WFS_Verbauinfo_ELV "InfoüberdieKonfigurationderELVimWFS-Master";
CM_ SG_ 1361 WFS_ID_Geb_autorisiert "AuthorisierungSchluessel(ID-Geber)
";
CM_ SG_ 1361 WFS_ID_Geb_autorisiert_in_Kl15 "AuthorisierungdesSchlüsselsimaktivenKlemme-15-Zyklus";
CM_ SG_ 1361 WFS_ID_Geb_steckt "Schluessel(ID-Geber)imZuendschloss
";
CM_ SG_ 1361 WFS_Schluessel_Soll "SollwertderzulernendenSchluessel";
CM_ SG_ 1361 WFS_Schluessel_Ist "IstwertdergelerntenSchluessel";
CM_ SG_ 1361 WFS_Safe "StatusWFS
";
CM_ SG_ 1361 WFS_LZ "AnforderungausLastenheftWFSV
";
CM_ SG_ 1361 WFS_ELV_authorisiert "AuthorisierungderelektrischenLenkungsverriegelunganderWFS";
CM_ SG_ 1361 WFS_LF_Aktiv "LFSchluesselkommunikation
";
CM_ SG_ 1361 WFS_Betrieb_Lesespule "SchlüsselkommunikationüberdieLesespule";
CM_ SG_ 1361 WFS_Klemmenfreigabe "FreigabevonderWFSzumEinschaltenderKlemme15undKlemmeS";
CM_ SG_ 1361 WFS_Klemmenfreigabe_Signatur "SignaturzurKlemmenfreigabedurchdieWFS";
CM_ SG_ 1361 WFS_Fahrerhinweise "Meldungen,Fahrer-undWarnhinweisederWegfahrsperre";
CM_ SG_ 1361 WFS_Parken_Status "SchnittstellezwischenWFSundZFASfürdasPilotierteParkenuminRichtungZFASdenStatusderWFSimBCM2zukommunizieren";
CM_ SG_ 2617226768 XCP_Motor_CRO_01_Data "INCA->MSG";
CM_ SG_ 2617226769 XCP_Motor_DTO_01_Data "MSG->INCA";
CM_ SG_ 1411 ZV_verriegeln_Anf "GesammelteexterneZV-VerriegelungsanforderungdesKunden(z.B.zurAktivierungderAnzeigedesLadezustandsüberAussenlicht).";
CM_ SG_ 1411 ZV_STSG_HFS_Anf "DieZVforderteinenLaufbzw.StoppderSchiebetüran.";
CM_ SG_ 1411 ZV_STSG_HBFS_Anf "DieZVforderteinenLaufbzw.StoppderSchiebetüran.";
CM_ SG_ 1411 ZV_Anf_Challenge_Auth "AnforderunganallebeteiligtenSteuergerätedieChallengeandenZV-Masterzusenden.";
CM_ SG_ 1411 BCM_FH_Freigabe "FunktionsfreigabeFensterheber";
CM_ SG_ 1411 BCM_Komfortfkt_Freigabe "globaleFreigabederKomfortfunktion";
CM_ SG_ 1411 BCM_HSK_Freigabe "Handschuhkastenfreigabe";
CM_ SG_ 1411 BCM_Verdeck_Freigabe "FreigabeVerdeckbetrieb
";
CM_ SG_ 1411 ZV_verriegelt_intern_ist "Istzustand:VerriegelungFahrzeuginnen
";
CM_ SG_ 1411 ZV_verriegelt_extern_ist "Istzustand:VerriegelungFahrzeugaussen
";
CM_ SG_ 1411 ZV_verriegelt_intern_soll "Sollzustand:VerriegelungFahrzeuginnen
";
CM_ SG_ 1411 ZV_verriegelt_extern_soll "Sollzustand:VerriegelungFahrzeugaussen
";
CM_ SG_ 1411 ZV_gesafet_extern_ist "Istzustand:Fahrzeugaussengesafet
";
CM_ SG_ 1411 ZV_gesafet_extern_soll "Sollzustand:Fahrzeuggesafetextern
";
CM_ SG_ 1411 ZV_Einzeltuerentriegelung "EinzeltürentriegelungZV
";
CM_ SG_ 1411 ZV_Heckeinzelentriegelung "Heckdeckeleinzelentriegelung";
CM_ SG_ 1411 ZV_FT_offen "gespiegeltesBitFT_Tuer_geoeffnetTSG_FT_1Botschaft";
CM_ SG_ 1411 ZV_BT_offen "gespiegeltesBitBT_Tuer_geoeffnetTSG_BT_1Botschaft";
CM_ SG_ 1411 ZV_HFS_offen "gespiegeltesBitHFS_Tuer_geoeffnetTSG_HFS_1Botschaft";
CM_ SG_ 1411 ZV_HBFS_offen "gespiegeltesBitHBFS_Tuer_geoeffnetTSG_HBFS_1Botschaft";
CM_ SG_ 1411 ZV_HD_offen "StatusHeckdeckel
";
CM_ SG_ 1411 ZV_HS_offen "StatusHeckscheibe
";
CM_ SG_ 1411 IRUE_aktiv "StatusInnenraumüberwachung
";
CM_ SG_ 1411 DWA_aktiv "StatusDWA
";
CM_ SG_ 1411 FFB_HDF_Taste "HDFTasteamFunkschluessel
";
CM_ SG_ 1411 FFB_Panik_Taste "PanikTasteFunkschluessel
";
CM_ SG_ 1411 FFB_Auf_Taste "Auf-TasteFunkschluessel

";
CM_ SG_ 1411 FFB_Zu_Taste "Zu-TasteFunkschluessel
";
CM_ SG_ 1411 FFB_CarFinder "CarFinderFunktion(Blinkenohnezuentriegeln)";
CM_ SG_ 1411 FFB_Komfortoeffnen "KomfortoeffnenFunk
";
CM_ SG_ 1411 FFB_Komfortschliessen "KomfortschliessenFunk
";
CM_ SG_ 1411 FBS_IDG_in_Reichweite "FürelektrischbetätigteTürenundKlappenmussfüreineBetätigungüberFunkeineReichweitenbegrenzungeingeführtwerden.DieseBitzeigtan,dasssichderFunkschlüsselinnerhalbdergefordertenReichweitebefindet";
CM_ SG_ 1411 ZV_Schluessel_Zugang "aktuelleFunkschlüsselnummer";
CM_ SG_ 1411 ZV_SafeFunktion_aktiv "StatusübermittlungobdieSafeFunktionimFzg.aktivist.DasKombibenötigtdasSignal,umdenTextSafelockaktivanzuzeigen.";
CM_ SG_ 1411 FBS_Warn_Schluessel_Batt "KombiPrioWarnungSchluesselBatterie
'Bitte Schlüsselbatterie wechseln!'";
CM_ SG_ 1411 ZV_Oeffnungsmodus "KonfigurierterOeffnungsmodusfuerZV:
0 = globale Oeffnung (alle Tueren)
1 = ZV mit Einzeltuerentriegelung (FFB - nur Fahrertuer, Kessy - nur bediente Tuer)
2 = ZV individuell selektive Oeffnung (FFB - Fahrerseite, Kessy - bediente Tuer + Fahrertuer)";
CM_ SG_ 1411 ZV_ist_Zustand_verfuegbar "VerfügbarkeitIST-ZustandZV

";
CM_ SG_ 1411 IRUE_Taster_Fkts_LED "AnforderungFunktions-LEDIRUE-Taster(LEDwirdvomTSGangesteuert)
MQB: Bei Verbau eines einzelnen Taster zur Deaktivierung von IRUE und NGS wird dieses Signal zur Ansteuerung der Funktions-LED gesendet.";
CM_ SG_ 1411 ZV_Tankklappe_offen "ÖffnungsstatusderTankklappe";
CM_ SG_ 1411 ZV_Rollo_auf "KomfortöffnendesDachrollos";
CM_ SG_ 1411 ZV_Rollo_zu "KomfortschließendesDachrollos";
CM_ SG_ 1411 ZV_SAD_auf "KomfortöffnendesSchiebeausstelldaches";
CM_ SG_ 1411 ZV_SAD_zu "KomfortschließendesSchiebeausstelldaches";
CM_ SG_ 1411 ZV_verriegelt_soll "FahrzeugGesamtverriegelungsstatusSollzustandfürLadestecker-undLadeklappenverriegelung.";
BA_DEF_ BO_ "DiagRequest" ENUM "No", "Yes";
BA_DEF_ BO_ "DiagResponse" ENUM "No", "Yes";
BA_DEF_ BO_ "DiagState" ENUM "No", "Yes";
BA_DEF_ BO_ "GenMsgChkConstant" HEX 0 4095;
BA_DEF_ BO_ "GenMsgCycleTime" INT 0 65535;
BA_DEF_ BO_ "GenMsgCycleTimeFast" INT 0 65535;
BA_DEF_ BO_ "GenMsgDelayTime" INT 0 100000;
BA_DEF_ BO_ "GenMsgILSupport" ENUM "No", "Yes";
BA_DEF_ BO_ "GenMsgNrOfRepetition" INT 0 100;
BA_DEF_ BO_ "GenMsgPDUConstants" STRING;
BA_DEF_ BO_ "GenMsgSendType" ENUM "Cyclic", "not_used", "not_used", "not_used", "not_used", "not_used", "not_used", "IfActive", "NoMsgSendType";
BA_DEF_ BO_ "GenMsgStartDelayTime" INT 0 100000;
BA_DEF_ BO_ "NmMessage" ENUM "No", "Yes";
BA_DEF_ BO_ "NmhMessage" ENUM "No", "Yes";
BA_DEF_ BO_ "MsgType" ENUM "Application", "NM", "NMH", "TP2.0", "ISO-TP", "BAP", "EID", "KS";
BA_DEF_ BO_ "VAGTP20_API" HEX 0 255;
BA_DEF_ BO_ "VAGTP20_DynConnection" ENUM "No", "Yes";
BA_DEF_ BO_ "VAGTP20_DynSetup" ENUM "No", "Yes";
BA_DEF_ BO_ "VAGTP20_StatConnection" ENUM "No", "Yes";
BA_DEF_ BO_ "CANFD_BRS" ENUM "0", "1";
BA_DEF_ BO_ "VFrameFormat" ENUM "StandardCAN", "ExtendedCAN", "reserved", "reserved", "reserved", "reserved", "reserved", "reserved", "reserved", "reserved", "reserved", "reserved", "reserved", "reserved", "StandardCAN_FD", "ExtendedCAN_FD";
BA_DEF_ SG_ "GenSigActiveRepetitions" INT -2147483648 2147483647;
BA_DEF_ SG_ "GenSigInactiveValue" INT -2147483648 2147483647;
BA_DEF_ SG_ "GenSigSendType" ENUM "Cyclic", "OnWrite", "OnWriteWithRepetition", "OnChange", "OnChangeWithRepetition", "IfActive", "IfActiveWithRepetition", "NoSigSendType", "OnChangeAndIfActive", "OnChangeAndIfActiveWithRepetition";
BA_DEF_ SG_ "GenSigStartValue" INT -2147483648 2147483647;
BA_DEF_ SG_ "NWM-WakeupAllowed" ENUM "No", "Yes";
BA_DEF_ SG_ "GenSigFuncType" ENUM "NoFunction", "MsgCounter", "CRC-8", "XOR", "XOR-2", "DatedBit", "SW-Kl15", "CHK", "Constant", "Protocol", "CRC-8-SAE_J1850";
BA_DEF_ SG_ "GenSigSwitchedByIgnition" ENUM "No", "Yes";
BA_DEF_ SG_ "Fehlerwert" HEX 0 2147483647;
BA_DEF_ SG_ "GenSigMissingSourceValue" HEX 0 2147483647;
BA_DEF_DEF_  "DiagRequest" "No";
BA_DEF_DEF_  "DiagResponse" "No";
BA_DEF_DEF_  "DiagState" "No";
BA_DEF_DEF_  "GenMsgChkConstant" 0;
BA_DEF_DEF_  "GenMsgCycleTime" 0;
BA_DEF_DEF_  "GenMsgCycleTimeFast" 0;
BA_DEF_DEF_  "GenMsgDelayTime" 0;
BA_DEF_DEF_  "GenMsgILSupport" "No";
BA_DEF_DEF_  "GenMsgNrOfRepetition" 0;
BA_DEF_DEF_  "GenMsgPDUConstants" "";
BA_DEF_DEF_  "GenMsgSendType" "NoMsgSendType";
BA_DEF_DEF_  "GenMsgStartDelayTime" 0;
BA_DEF_DEF_  "NmMessage" "No";
BA_DEF_DEF_  "NmhMessage" "No";
BA_DEF_DEF_  "MsgType" "Application";
BA_DEF_DEF_  "VAGTP20_API" 0;
BA_DEF_DEF_  "VAGTP20_DynConnection" "No";
BA_DEF_DEF_  "VAGTP20_DynSetup" "No";
BA_DEF_DEF_  "VAGTP20_StatConnection" "No";
BA_DEF_DEF_  "CANFD_BRS" "1";
BA_DEF_DEF_  "VFrameFormat" "StandardCAN";
BA_DEF_DEF_  "GenSigActiveRepetitions" 0;
BA_DEF_DEF_  "GenSigInactiveValue" 0;
BA_DEF_DEF_  "GenSigSendType" "NoSigSendType";
BA_DEF_DEF_  "GenSigStartValue" 0;
BA_DEF_DEF_  "NWM-WakeupAllowed" "No";
BA_DEF_DEF_  "GenSigFuncType" "NoFunction";
BA_DEF_DEF_  "GenSigSwitchedByIgnition" "Yes";
BA_DEF_DEF_  "Fehlerwert" 0;
BA_DEF_DEF_  "GenSigMissingSourceValue" 0;
BA_ "GenMsgCycleTime" BO_ 1019 80;
BA_ "GenMsgILSupport" BO_ 1019 "Yes";
BA_ "GenMsgSendType" BO_ 1019 "Cyclic";
BA_ "VFrameFormat" BO_ 1019 "StandardCAN_FD";
BA_ "GenMsgCycleTime" BO_ 1716 200;
BA_ "GenMsgILSupport" BO_ 1716 "Yes";
BA_ "GenMsgSendType" BO_ 1716 "Cyclic";
BA_ "VFrameFormat" BO_ 1716 "StandardCAN_FD";
BA_ "GenMsgCycleTime" BO_ 261 20;
BA_ "GenMsgILSupport" BO_ 261 "Yes";
BA_ "GenMsgPDUConstants" BO_ 261 "0xde,0x0e,0xa7,0x1d,0xc3,0x83,0xbd,0x82,0x8c,0xa2,0x0c,0x7b,0x4d,0x3c,0x58,0x79";
BA_ "GenMsgSendType" BO_ 261 "Cyclic";
BA_ "VFrameFormat" BO_ 261 "StandardCAN_FD";
BA_ "GenMsgCycleTime" BO_ 313 20;
BA_ "GenMsgILSupport" BO_ 313 "Yes";
BA_ "GenMsgPDUConstants" BO_ 313 "0xed,0x03,0x1c,0x13,0xc6,0x23,0x78,0x7a,0x8b,0x40,0x14,0x51,0xbf,0x68,0x32,0xba";
BA_ "GenMsgSendType" BO_ 313 "Cyclic";
BA_ "VFrameFormat" BO_ 313 "StandardCAN_FD";
BA_ "GenMsgCycleTime" BO_ 2463978663 200;
BA_ "GenMsgDelayTime" BO_ 2463978663 40;
BA_ "GenMsgILSupport" BO_ 2463978663 "Yes";
BA_ "GenMsgSendType" BO_ 2463978663 "Cyclic";
BA_ "VFrameFormat" BO_ 2463978663 "ExtendedCAN_FD";
BA_ "GenMsgChkConstant" BO_ 181 228;
BA_ "GenMsgCycleTime" BO_ 181 10;
BA_ "GenMsgILSupport" BO_ 181 "Yes";
BA_ "GenMsgPDUConstants" BO_ 181 "0xe4,0xe4,0xe4,0xe4,0xe4,0xe4,0xe4,0xe4,0xe4,0xe4,0xe4,0xe4,0xe4,0xe4,0xe4,0xe4";
BA_ "GenMsgSendType" BO_ 181 "Cyclic";
BA_ "VFrameFormat" BO_ 181 "StandardCAN_FD";
BA_ "GenMsgCycleTime" BO_ 2463978687 1000;
BA_ "GenMsgDelayTime" BO_ 2463978687 100;
BA_ "GenMsgILSupport" BO_ 2463978687 "Yes";
BA_ "GenMsgSendType" BO_ 2463978687 "Cyclic";
BA_ "VFrameFormat" BO_ 2463978687 "ExtendedCAN_FD";
BA_ "GenMsgCycleTime" BO_ 916 160;
BA_ "GenMsgDelayTime" BO_ 916 10;
BA_ "GenMsgILSupport" BO_ 916 "Yes";
BA_ "GenMsgPDUConstants" BO_ 916 "0x47,0x94,0x92,0x6a,0x67,0xb5,0x0d,0x38,0xe3,0x8a,0x5d,0xb4,0x54,0xab,0xae,0x27";
BA_ "GenMsgSendType" BO_ 916 "Cyclic";
BA_ "VFrameFormat" BO_ 916 "StandardCAN_FD";
BA_ "GenMsgCycleTime" BO_ 1361 200;
BA_ "GenMsgDelayTime" BO_ 1361 50;
BA_ "GenMsgILSupport" BO_ 1361 "Yes";
BA_ "GenMsgSendType" BO_ 1361 "Cyclic";
BA_ "VFrameFormat" BO_ 1361 "StandardCAN_FD";
BA_ "MsgType" BO_ 2617028096 "EID";
BA_ "VFrameFormat" BO_ 2617028096 "ExtendedCAN_FD";
BA_ "MsgType" BO_ 2617028097 "EID";
BA_ "VFrameFormat" BO_ 2617028097 "ExtendedCAN_FD";
BA_ "MsgType" BO_ 2617239040 "EID";
BA_ "VFrameFormat" BO_ 2617239040 "ExtendedCAN_FD";
BA_ "MsgType" BO_ 2617239041 "EID";
BA_ "VFrameFormat" BO_ 2617239041 "ExtendedCAN_FD";
BA_ "MsgType" BO_ 2617239042 "EID";
BA_ "VFrameFormat" BO_ 2617239042 "ExtendedCAN_FD";
BA_ "MsgType" BO_ 2617239043 "EID";
BA_ "VFrameFormat" BO_ 2617239043 "ExtendedCAN_FD";
BA_ "MsgType" BO_ 2617239044 "EID";
BA_ "VFrameFormat" BO_ 2617239044 "ExtendedCAN_FD";
BA_ "MsgType" BO_ 2617122304 "EID";
BA_ "VFrameFormat" BO_ 2617122304 "ExtendedCAN_FD";
BA_ "MsgType" BO_ 2617122305 "EID";
BA_ "VFrameFormat" BO_ 2617122305 "ExtendedCAN_FD";
BA_ "MsgType" BO_ 2617122306 "EID";
BA_ "VFrameFormat" BO_ 2617122306 "ExtendedCAN_FD";
BA_ "MsgType" BO_ 2617122307 "EID";
BA_ "VFrameFormat" BO_ 2617122307 "ExtendedCAN_FD";
BA_ "MsgType" BO_ 2617122308 "EID";
BA_ "VFrameFormat" BO_ 2617122308 "ExtendedCAN_FD";
BA_ "MsgType" BO_ 2617226768 "EID";
BA_ "VFrameFormat" BO_ 2617226768 "ExtendedCAN_FD";
BA_ "MsgType" BO_ 2617226769 "EID";
BA_ "VFrameFormat" BO_ 2617226769 "ExtendedCAN_FD";
BA_ "GenMsgCycleTime" BO_ 1411 200;
BA_ "GenMsgCycleTimeFast" BO_ 1411 50;
BA_ "GenMsgDelayTime" BO_ 1411 20;
BA_ "GenMsgILSupport" BO_ 1411 "Yes";
BA_ "GenMsgNrOfRepetition" BO_ 1411 3;
BA_ "GenMsgSendType" BO_ 1411 "Cyclic";
BA_ "VFrameFormat" BO_ 1411 "StandardCAN_FD";
BA_ "GenSigStartValue" SG_ 1019 TSK_Ausrollkurve_Schub_Reku_01 127;
BA_ "GenSigSwitchedByIgnition" SG_ 1019 TSK_Ausrollkurve_Schub_Reku_01 "No";
BA_ "GenSigStartValue" SG_ 1019 TSK_Ausrollkurve_Schub_Reku_05 127;
BA_ "GenSigSwitchedByIgnition" SG_ 1019 TSK_Ausrollkurve_Schub_Reku_05 "No";
BA_ "GenSigStartValue" SG_ 1019 TSK_Ausrollkurve_Schub_Reku_09 127;
BA_ "GenSigSwitchedByIgnition" SG_ 1019 TSK_Ausrollkurve_Schub_Reku_09 "No";
BA_ "GenSigStartValue" SG_ 1019 TSK_Ausrollkurve_Schub_Reku_13 127;
BA_ "GenSigSwitchedByIgnition" SG_ 1019 TSK_Ausrollkurve_Schub_Reku_13 "No";
BA_ "GenSigStartValue" SG_ 1019 TSK_Ausrollkurve_Schub_Reku_17 127;
BA_ "GenSigSwitchedByIgnition" SG_ 1019 TSK_Ausrollkurve_Schub_Reku_17 "No";
BA_ "GenSigStartValue" SG_ 1019 TSK_Ausrollkurve_Schub_Reku_02 127;
BA_ "GenSigSwitchedByIgnition" SG_ 1019 TSK_Ausrollkurve_Schub_Reku_02 "No";
BA_ "GenSigStartValue" SG_ 1019 TSK_Ausrollkurve_Schub_Reku_06 127;
BA_ "GenSigSwitchedByIgnition" SG_ 1019 TSK_Ausrollkurve_Schub_Reku_06 "No";
BA_ "GenSigStartValue" SG_ 1019 TSK_Ausrollkurve_Schub_Reku_10 127;
BA_ "GenSigSwitchedByIgnition" SG_ 1019 TSK_Ausrollkurve_Schub_Reku_10 "No";
BA_ "GenSigStartValue" SG_ 1019 TSK_Ausrollkurve_Schub_Reku_14 127;
BA_ "GenSigSwitchedByIgnition" SG_ 1019 TSK_Ausrollkurve_Schub_Reku_14 "No";
BA_ "GenSigStartValue" SG_ 1019 TSK_Ausrollkurve_Schub_Reku_18 127;
BA_ "GenSigSwitchedByIgnition" SG_ 1019 TSK_Ausrollkurve_Schub_Reku_18 "No";
BA_ "GenSigStartValue" SG_ 1019 TSK_Ausrollkurve_Schub_Reku_03 127;
BA_ "GenSigSwitchedByIgnition" SG_ 1019 TSK_Ausrollkurve_Schub_Reku_03 "No";
BA_ "GenSigStartValue" SG_ 1019 TSK_Ausrollkurve_Schub_Reku_07 127;
BA_ "GenSigSwitchedByIgnition" SG_ 1019 TSK_Ausrollkurve_Schub_Reku_07 "No";
BA_ "GenSigStartValue" SG_ 1019 TSK_Ausrollkurve_Schub_Reku_11 127;
BA_ "GenSigSwitchedByIgnition" SG_ 1019 TSK_Ausrollkurve_Schub_Reku_11 "No";
BA_ "GenSigStartValue" SG_ 1019 TSK_Ausrollkurve_Schub_Reku_15 127;
BA_ "GenSigSwitchedByIgnition" SG_ 1019 TSK_Ausrollkurve_Schub_Reku_15 "No";
BA_ "GenSigStartValue" SG_ 1019 TSK_Ausrollkurve_Schub_Reku_19 127;
BA_ "GenSigSwitchedByIgnition" SG_ 1019 TSK_Ausrollkurve_Schub_Reku_19 "No";
BA_ "GenSigStartValue" SG_ 1019 TSK_Ausrollkurve_Schub_Reku_04 127;
BA_ "GenSigSwitchedByIgnition" SG_ 1019 TSK_Ausrollkurve_Schub_Reku_04 "No";
BA_ "GenSigStartValue" SG_ 1019 TSK_Ausrollkurve_Schub_Reku_08 127;
BA_ "GenSigSwitchedByIgnition" SG_ 1019 TSK_Ausrollkurve_Schub_Reku_08 "No";
BA_ "GenSigStartValue" SG_ 1019 TSK_Ausrollkurve_Schub_Reku_12 127;
BA_ "GenSigSwitchedByIgnition" SG_ 1019 TSK_Ausrollkurve_Schub_Reku_12 "No";
BA_ "GenSigStartValue" SG_ 1019 TSK_Ausrollkurve_Schub_Reku_16 127;
BA_ "GenSigSwitchedByIgnition" SG_ 1019 TSK_Ausrollkurve_Schub_Reku_16 "No";
BA_ "GenSigStartValue" SG_ 1019 TSK_Ausrollkurve_Schub_Reku_20 127;
BA_ "GenSigSwitchedByIgnition" SG_ 1019 TSK_Ausrollkurve_Schub_Reku_20 "No";
BA_ "GenSigStartValue" SG_ 1019 TSK_Ausrollkurve_Segeln_01 127;
BA_ "GenSigSwitchedByIgnition" SG_ 1019 TSK_Ausrollkurve_Segeln_01 "No";
BA_ "GenSigStartValue" SG_ 1019 TSK_Ausrollkurve_Segeln_05 127;
BA_ "GenSigSwitchedByIgnition" SG_ 1019 TSK_Ausrollkurve_Segeln_05 "No";
BA_ "GenSigStartValue" SG_ 1019 TSK_Ausrollkurve_Segeln_09 127;
BA_ "GenSigSwitchedByIgnition" SG_ 1019 TSK_Ausrollkurve_Segeln_09 "No";
BA_ "GenSigStartValue" SG_ 1019 TSK_Ausrollkurve_Segeln_13 127;
BA_ "GenSigSwitchedByIgnition" SG_ 1019 TSK_Ausrollkurve_Segeln_13 "No";
BA_ "GenSigStartValue" SG_ 1019 TSK_Ausrollkurve_Segeln_17 127;
BA_ "GenSigSwitchedByIgnition" SG_ 1019 TSK_Ausrollkurve_Segeln_17 "No";
BA_ "GenSigStartValue" SG_ 1019 TSK_Ausrollkurve_Segeln_02 127;
BA_ "GenSigSwitchedByIgnition" SG_ 1019 TSK_Ausrollkurve_Segeln_02 "No";
BA_ "GenSigStartValue" SG_ 1019 TSK_Ausrollkurve_Segeln_06 127;
BA_ "GenSigSwitchedByIgnition" SG_ 1019 TSK_Ausrollkurve_Segeln_06 "No";
BA_ "GenSigStartValue" SG_ 1019 TSK_Ausrollkurve_Segeln_10 127;
BA_ "GenSigSwitchedByIgnition" SG_ 1019 TSK_Ausrollkurve_Segeln_10 "No";
BA_ "GenSigStartValue" SG_ 1019 TSK_Ausrollkurve_Segeln_14 127;
BA_ "GenSigSwitchedByIgnition" SG_ 1019 TSK_Ausrollkurve_Segeln_14 "No";
BA_ "GenSigStartValue" SG_ 1019 TSK_Ausrollkurve_Segeln_18 127;
BA_ "GenSigSwitchedByIgnition" SG_ 1019 TSK_Ausrollkurve_Segeln_18 "No";
BA_ "GenSigStartValue" SG_ 1019 TSK_Ausrollkurve_Segeln_03 127;
BA_ "GenSigSwitchedByIgnition" SG_ 1019 TSK_Ausrollkurve_Segeln_03 "No";
BA_ "GenSigStartValue" SG_ 1019 TSK_Ausrollkurve_Segeln_07 127;
BA_ "GenSigSwitchedByIgnition" SG_ 1019 TSK_Ausrollkurve_Segeln_07 "No";
BA_ "GenSigStartValue" SG_ 1019 TSK_Ausrollkurve_Segeln_11 127;
BA_ "GenSigSwitchedByIgnition" SG_ 1019 TSK_Ausrollkurve_Segeln_11 "No";
BA_ "GenSigStartValue" SG_ 1019 TSK_Ausrollkurve_Segeln_15 127;
BA_ "GenSigSwitchedByIgnition" SG_ 1019 TSK_Ausrollkurve_Segeln_15 "No";
BA_ "GenSigStartValue" SG_ 1019 TSK_Ausrollkurve_Segeln_19 127;
BA_ "GenSigSwitchedByIgnition" SG_ 1019 TSK_Ausrollkurve_Segeln_19 "No";
BA_ "GenSigStartValue" SG_ 1019 TSK_Ausrollkurve_Segeln_04 127;
BA_ "GenSigSwitchedByIgnition" SG_ 1019 TSK_Ausrollkurve_Segeln_04 "No";
BA_ "GenSigStartValue" SG_ 1019 TSK_Ausrollkurve_Segeln_08 127;
BA_ "GenSigSwitchedByIgnition" SG_ 1019 TSK_Ausrollkurve_Segeln_08 "No";
BA_ "GenSigStartValue" SG_ 1019 TSK_Ausrollkurve_Segeln_12 127;
BA_ "GenSigSwitchedByIgnition" SG_ 1019 TSK_Ausrollkurve_Segeln_12 "No";
BA_ "GenSigStartValue" SG_ 1019 TSK_Ausrollkurve_Segeln_16 127;
BA_ "GenSigSwitchedByIgnition" SG_ 1019 TSK_Ausrollkurve_Segeln_16 "No";
BA_ "GenSigStartValue" SG_ 1019 TSK_Ausrollkurve_Segeln_20 127;
BA_ "GenSigSwitchedByIgnition" SG_ 1019 TSK_Ausrollkurve_Segeln_20 "No";
BA_ "GenSigSendType" SG_ 1019 TSK_Ausrollkurve_Mux "Cyclic";
BA_ "GenSigSwitchedByIgnition" SG_ 1019 TSK_Ausrollkurve_Mux "No";
BA_ "GenSigSendType" SG_ 1019 TSK_Ausrollkurve_Reku "Cyclic";
BA_ "GenSigSwitchedByIgnition" SG_ 1019 TSK_Ausrollkurve_Reku "No";
BA_ "GenSigSendType" SG_ 1019 TSK_Ausrollkurve_Schrittweite "Cyclic";
BA_ "GenSigSwitchedByIgnition" SG_ 1019 TSK_Ausrollkurve_Schrittweite "No";
BA_ "GenSigSendType" SG_ 1019 TSK_Ausrollkurve_Zaehler "Cyclic";
BA_ "GenSigSwitchedByIgnition" SG_ 1019 TSK_Ausrollkurve_Zaehler "No";
BA_ "GenSigSendType" SG_ 1716 VIN_01_MUX "Cyclic";
BA_ "GenSigSwitchedByIgnition" SG_ 1716 VIN_01_MUX "No";
BA_ "GenSigSwitchedByIgnition" SG_ 1716 KS_Geheimnis_1 "No";
BA_ "GenSigStartValue" SG_ 1716 VIN_4 45;
BA_ "GenSigSwitchedByIgnition" SG_ 1716 VIN_4 "No";
BA_ "GenSigStartValue" SG_ 1716 VIN_11 45;
BA_ "GenSigSwitchedByIgnition" SG_ 1716 VIN_11 "No";
BA_ "GenSigSwitchedByIgnition" SG_ 1716 KS_Geheimnis_2 "No";
BA_ "GenSigStartValue" SG_ 1716 VIN_5 45;
BA_ "GenSigSwitchedByIgnition" SG_ 1716 VIN_5 "No";
BA_ "GenSigStartValue" SG_ 1716 VIN_12 45;
BA_ "GenSigSwitchedByIgnition" SG_ 1716 VIN_12 "No";
BA_ "GenSigSwitchedByIgnition" SG_ 1716 KS_Geheimnis_3 "No";
BA_ "GenSigStartValue" SG_ 1716 VIN_6 45;
BA_ "GenSigSwitchedByIgnition" SG_ 1716 VIN_6 "No";
BA_ "GenSigStartValue" SG_ 1716 VIN_13 45;
BA_ "GenSigSwitchedByIgnition" SG_ 1716 VIN_13 "No";
BA_ "GenSigSwitchedByIgnition" SG_ 1716 KS_Geheimnis_4 "No";
BA_ "GenSigStartValue" SG_ 1716 VIN_7 45;
BA_ "GenSigSwitchedByIgnition" SG_ 1716 VIN_7 "No";
BA_ "GenSigStartValue" SG_ 1716 VIN_14 45;
BA_ "GenSigSwitchedByIgnition" SG_ 1716 VIN_14 "No";
BA_ "GenSigStartValue" SG_ 1716 VIN_1 45;
BA_ "GenSigSwitchedByIgnition" SG_ 1716 VIN_1 "No";
BA_ "GenSigStartValue" SG_ 1716 VIN_8 45;
BA_ "GenSigSwitchedByIgnition" SG_ 1716 VIN_8 "No";
BA_ "GenSigStartValue" SG_ 1716 VIN_15 45;
BA_ "GenSigSwitchedByIgnition" SG_ 1716 VIN_15 "No";
BA_ "GenSigStartValue" SG_ 1716 VIN_2 45;
BA_ "GenSigSwitchedByIgnition" SG_ 1716 VIN_2 "No";
BA_ "GenSigStartValue" SG_ 1716 VIN_9 45;
BA_ "GenSigSwitchedByIgnition" SG_ 1716 VIN_9 "No";
BA_ "GenSigStartValue" SG_ 1716 VIN_16 45;
BA_ "GenSigSwitchedByIgnition" SG_ 1716 VIN_16 "No";
BA_ "GenSigStartValue" SG_ 1716 VIN_3 45;
BA_ "GenSigSwitchedByIgnition" SG_ 1716 VIN_3 "No";
BA_ "GenSigStartValue" SG_ 1716 VIN_10 45;
BA_ "GenSigSwitchedByIgnition" SG_ 1716 VIN_10 "No";
BA_ "GenSigStartValue" SG_ 1716 VIN_17 45;
BA_ "GenSigSwitchedByIgnition" SG_ 1716 VIN_17 "No";
BA_ "GenSigSendType" SG_ 261 VMM_01_CRC "Cyclic";
BA_ "GenSigFuncType" SG_ 261 VMM_01_CRC "CRC-8";
BA_ "GenSigSwitchedByIgnition" SG_ 261 VMM_01_CRC "No";
BA_ "GenSigSendType" SG_ 261 VMM_01_BZ "Cyclic";
BA_ "GenSigFuncType" SG_ 261 VMM_01_BZ "MsgCounter";
BA_ "GenSigSwitchedByIgnition" SG_ 261 VMM_01_BZ "No";
BA_ "GenSigSendType" SG_ 261 HMS_P_beibehalten_GE "Cyclic";
BA_ "GenSigStartValue" SG_ 261 HMS_P_beibehalten_GE 2;
BA_ "GenSigSwitchedByIgnition" SG_ 261 HMS_P_beibehalten_GE "No";
BA_ "Fehlerwert" SG_ 261 HMS_P_beibehalten_GE 3;
BA_ "GenSigSendType" SG_ 261 VZM_Unterdrueckung_Antriebsmom "Cyclic";
BA_ "GenSigSwitchedByIgnition" SG_ 261 VZM_Unterdrueckung_Antriebsmom "No";
BA_ "GenSigSendType" SG_ 261 HMS_halten_nicht_verfuegbar "Cyclic";
BA_ "GenSigSwitchedByIgnition" SG_ 261 HMS_halten_nicht_verfuegbar "No";
BA_ "GenSigSendType" SG_ 261 HMS_parken_nicht_verfuegbar "Cyclic";
BA_ "GenSigSwitchedByIgnition" SG_ 261 HMS_parken_nicht_verfuegbar "No";
BA_ "GenSigSendType" SG_ 261 HMS_Anforderung_GE "Cyclic";
BA_ "GenSigSwitchedByIgnition" SG_ 261 HMS_Anforderung_GE "No";
BA_ "GenSigSendType" SG_ 261 HMS_Systemstatus "Cyclic";
BA_ "GenSigStartValue" SG_ 261 HMS_Systemstatus 14;
BA_ "GenSigSwitchedByIgnition" SG_ 261 HMS_Systemstatus "No";
BA_ "Fehlerwert" SG_ 261 HMS_Systemstatus 15;
BA_ "GenSigSendType" SG_ 261 HMS_Stillstand "Cyclic";
BA_ "GenSigStartValue" SG_ 261 HMS_Stillstand 6;
BA_ "GenSigSwitchedByIgnition" SG_ 261 HMS_Stillstand "No";
BA_ "Fehlerwert" SG_ 261 HMS_Stillstand 7;
BA_ "GenSigSendType" SG_ 261 HMS_aktives_System "Cyclic";
BA_ "GenSigSwitchedByIgnition" SG_ 261 HMS_aktives_System "No";
BA_ "GenSigSendType" SG_ 261 VMM_Inkonsistenz_GE "Cyclic";
BA_ "GenSigSwitchedByIgnition" SG_ 261 VMM_Inkonsistenz_GE "No";
BA_ "GenSigSendType" SG_ 261 VMM_Inkonsistenz_HVLM "Cyclic";
BA_ "GenSigSwitchedByIgnition" SG_ 261 VMM_Inkonsistenz_HVLM "No";
BA_ "GenSigSendType" SG_ 261 HMS_Fehlerstatus "Cyclic";
BA_ "GenSigSwitchedByIgnition" SG_ 261 HMS_Fehlerstatus "No";
BA_ "GenSigSendType" SG_ 261 HMS_Index_Haltemoment "Cyclic";
BA_ "GenSigSwitchedByIgnition" SG_ 261 HMS_Index_Haltemoment "No";
BA_ "GenSigSendType" SG_ 261 HMS_Haltemoment "Cyclic";
BA_ "GenSigStartValue" SG_ 261 HMS_Haltemoment 1022;
BA_ "GenSigSwitchedByIgnition" SG_ 261 HMS_Haltemoment "No";
BA_ "Fehlerwert" SG_ 261 HMS_Haltemoment 1023;
BA_ "GenSigSendType" SG_ 313 VMM_02_CRC "Cyclic";
BA_ "GenSigFuncType" SG_ 313 VMM_02_CRC "CRC-8";
BA_ "GenSigSwitchedByIgnition" SG_ 313 VMM_02_CRC "No";
BA_ "GenSigSendType" SG_ 313 VMM_02_BZ "Cyclic";
BA_ "GenSigFuncType" SG_ 313 VMM_02_BZ "MsgCounter";
BA_ "GenSigSwitchedByIgnition" SG_ 313 VMM_02_BZ "No";
BA_ "GenSigSendType" SG_ 313 VZM_aktiver_Basisservice "Cyclic";
BA_ "GenSigSwitchedByIgnition" SG_ 313 VZM_aktiver_Basisservice "No";
BA_ "GenSigSendType" SG_ 313 VZM_Anhalteweg_nicht_verfuegbar "Cyclic";
BA_ "GenSigSwitchedByIgnition" SG_ 313 VZM_Anhalteweg_nicht_verfuegbar "No";
BA_ "GenSigSendType" SG_ 313 VZM_Fahrer_bremst "Cyclic";
BA_ "GenSigSwitchedByIgnition" SG_ 313 VZM_Fahrer_bremst "No";
BA_ "GenSigSendType" SG_ 313 VZM_QBit_Fahrer_bremst "Cyclic";
BA_ "GenSigStartValue" SG_ 313 VZM_QBit_Fahrer_bremst 1;
BA_ "GenSigSwitchedByIgnition" SG_ 313 VZM_QBit_Fahrer_bremst "No";
BA_ "GenSigSendType" SG_ 313 VMM_MKB_codiert "Cyclic";
BA_ "GenSigSwitchedByIgnition" SG_ 313 VMM_MKB_codiert "No";
BA_ "GenSigSendType" SG_ 313 VMM_Inkonsistenz_EBKV "Cyclic";
BA_ "GenSigSwitchedByIgnition" SG_ 313 VMM_Inkonsistenz_EBKV "No";
BA_ "GenSigSendType" SG_ 313 VMM_Notstopp_Status "Cyclic";
BA_ "GenSigSwitchedByIgnition" SG_ 313 VMM_Notstopp_Status "No";
BA_ "Fehlerwert" SG_ 313 VMM_Notstopp_Status 7;
BA_ "GenSigSendType" SG_ 313 VZM_Warnruck_nicht_verfuegbar "Cyclic";
BA_ "GenSigSwitchedByIgnition" SG_ 313 VZM_Warnruck_nicht_verfuegbar "No";
BA_ "GenSigSendType" SG_ 313 VZM_Warnruckeln_nicht_verfuegbar "Cyclic";
BA_ "GenSigSwitchedByIgnition" SG_ 313 VZM_Warnruckeln_nicht_verfuegbar "No";
BA_ "GenSigSendType" SG_ 313 VZM_Bkd_nicht_verfuegbar "Cyclic";
BA_ "GenSigSwitchedByIgnition" SG_ 313 VZM_Bkd_nicht_verfuegbar "No";
BA_ "GenSigSendType" SG_ 313 VMM_Bremslicht_defekt "Cyclic";
BA_ "GenSigSwitchedByIgnition" SG_ 313 VMM_Bremslicht_defekt "No";
BA_ "GenSigSendType" SG_ 313 VZM_Fahrer_bremst_deutlich "Cyclic";
BA_ "GenSigSwitchedByIgnition" SG_ 313 VZM_Fahrer_bremst_deutlich "No";
BA_ "GenSigSendType" SG_ 313 VZM_TSK_SRBM_Anf "Cyclic";
BA_ "GenSigSwitchedByIgnition" SG_ 313 VZM_TSK_SRBM_Anf "No";
BA_ "GenSigSendType" SG_ 313 VZM_TSK_SRBM_nicht_verfuegbar "Cyclic";
BA_ "GenSigSwitchedByIgnition" SG_ 313 VZM_TSK_SRBM_nicht_verfuegbar "No";
BA_ "GenSigSendType" SG_ 313 VZM_Verz_Reg_aktiv "Cyclic";
BA_ "GenSigSwitchedByIgnition" SG_ 313 VZM_Verz_Reg_aktiv "No";
BA_ "GenSigSendType" SG_ 313 VZM_Verz_Reg_nicht_verfuegbar "Cyclic";
BA_ "GenSigSwitchedByIgnition" SG_ 313 VZM_Verz_Reg_nicht_verfuegbar "No";
BA_ "GenSigSendType" SG_ 313 VMM_Inkonsistenz_KAS "Cyclic";
BA_ "GenSigSwitchedByIgnition" SG_ 313 VMM_Inkonsistenz_KAS "No";
BA_ "GenSigSendType" SG_ 313 VMM_Bremslicht_unplausibel "Cyclic";
BA_ "GenSigSwitchedByIgnition" SG_ 313 VMM_Bremslicht_unplausibel "No";
BA_ "GenSigSendType" SG_ 313 VMM_Inkonsistenz_ACC "Cyclic";
BA_ "GenSigSwitchedByIgnition" SG_ 313 VMM_Inkonsistenz_ACC "No";
BA_ "GenSigSendType" SG_ 313 VMM_Inkonsistenz_AWV_PCF "Cyclic";
BA_ "GenSigSwitchedByIgnition" SG_ 313 VMM_Inkonsistenz_AWV_PCF "No";
BA_ "GenSigSendType" SG_ 313 VMM_Inkonsistenz_ARA "Cyclic";
BA_ "GenSigSwitchedByIgnition" SG_ 313 VMM_Inkonsistenz_ARA "No";
BA_ "GenSigSendType" SG_ 313 VMM_Inkonsistenz_ParkAssist "Cyclic";
BA_ "GenSigSwitchedByIgnition" SG_ 313 VMM_Inkonsistenz_ParkAssist "No";
BA_ "GenSigSendType" SG_ 313 VMM_Inkonsistenz_FAS_VK "Cyclic";
BA_ "GenSigSwitchedByIgnition" SG_ 313 VMM_Inkonsistenz_FAS_VK "No";
BA_ "GenSigSendType" SG_ 313 VMM_Inkonsistenz_NV "Cyclic";
BA_ "GenSigSwitchedByIgnition" SG_ 313 VMM_Inkonsistenz_NV "No";
BA_ "GenSigSendType" SG_ 313 VMM_Inkonsistenz_RCTA "Cyclic";
BA_ "GenSigSwitchedByIgnition" SG_ 313 VMM_Inkonsistenz_RCTA "No";
BA_ "GenSigSendType" SG_ 313 VMM_Inkonsistenz_TSK "Cyclic";
BA_ "GenSigSwitchedByIgnition" SG_ 313 VMM_Inkonsistenz_TSK "No";
BA_ "GenSigSendType" SG_ 313 VMM_Inkonsistenz_MO "Cyclic";
BA_ "GenSigSwitchedByIgnition" SG_ 313 VMM_Inkonsistenz_MO "No";
BA_ "GenSigSendType" SG_ 313 VMM_Inkonsistenz_AEB "Cyclic";
BA_ "GenSigSwitchedByIgnition" SG_ 313 VMM_Inkonsistenz_AEB "No";
BA_ "GenSigSendType" SG_ 313 VMM_Fahrer_Bremskraft_bestimmend "Cyclic";
BA_ "GenSigSwitchedByIgnition" SG_ 313 VMM_Fahrer_Bremskraft_bestimmend "No";
BA_ "GenSigSendType" SG_ 313 VMM_Inkonsistenz_EA "Cyclic";
BA_ "GenSigSwitchedByIgnition" SG_ 313 VMM_Inkonsistenz_EA "No";
BA_ "GenSigSendType" SG_ 313 VZM_Status_Wegregelung "Cyclic";
BA_ "GenSigSwitchedByIgnition" SG_ 313 VZM_Status_Wegregelung "No";
BA_ "GenSigSendType" SG_ 313 VZM_Verz_ASIL_Verfuegbarkeit "Cyclic";
BA_ "GenSigSwitchedByIgnition" SG_ 313 VZM_Verz_ASIL_Verfuegbarkeit "No";
BA_ "GenSigSendType" SG_ 313 VZM_aktives_System "Cyclic";
BA_ "GenSigSwitchedByIgnition" SG_ 313 VZM_aktives_System "No";
BA_ "GenSigSendType" SG_ 313 VZM_Verz_Begrenzung "Cyclic";
BA_ "GenSigSwitchedByIgnition" SG_ 313 VZM_Verz_Begrenzung "No";
BA_ "GenSigSendType" SG_ 313 VZM_Systemstatus "Cyclic";
BA_ "GenSigSwitchedByIgnition" SG_ 313 VZM_Systemstatus "No";
BA_ "Fehlerwert" SG_ 313 VZM_Systemstatus 4;
BA_ "GenSigSendType" SG_ 313 VZM_SRBM_Soll "Cyclic";
BA_ "GenSigStartValue" SG_ 313 VZM_SRBM_Soll 4094;
BA_ "GenSigSwitchedByIgnition" SG_ 313 VZM_SRBM_Soll "No";
BA_ "Fehlerwert" SG_ 313 VZM_SRBM_Soll 4095;
BA_ "GenSigSendType" SG_ 313 VZM_SRBM_Ist "Cyclic";
BA_ "GenSigStartValue" SG_ 313 VZM_SRBM_Ist 4094;
BA_ "GenSigSwitchedByIgnition" SG_ 313 VZM_SRBM_Ist "No";
BA_ "Fehlerwert" SG_ 313 VZM_SRBM_Ist 4095;
BA_ "GenSigSendType" SG_ 313 VZM_SRBM_max_Gradient "Cyclic";
BA_ "GenSigStartValue" SG_ 313 VZM_SRBM_max_Gradient 126;
BA_ "GenSigSwitchedByIgnition" SG_ 313 VZM_SRBM_max_Gradient "No";
BA_ "Fehlerwert" SG_ 313 VZM_SRBM_max_Gradient 127;
BA_ "GenSigSendType" SG_ 313 VMM_Inkonsistenz_KAM "Cyclic";
BA_ "GenSigSwitchedByIgnition" SG_ 313 VMM_Inkonsistenz_KAM "No";
BA_ "GenSigSendType" SG_ 2463978663 VZE_Anzeigemodus "OnChange";
BA_ "GenSigSendType" SG_ 2463978663 VZE_Hinweistext "OnChange";
BA_ "GenSigSendType" SG_ 2463978663 VZE_Verkehrszeichen_Einheit "OnChange";
BA_ "GenSigSwitchedByIgnition" SG_ 2463978663 VZE_Verkehrszeichen_Einheit "No";
BA_ "GenSigSendType" SG_ 2463978663 VZE_Anzeigeunterdrueck_Zeichen_3 "OnChange";
BA_ "GenSigSendType" SG_ 2463978663 VZE_Anzeigeunterdrueck_Zeichen_2 "OnChange";
BA_ "GenSigSendType" SG_ 2463978663 VZE_Verkehrszeichen_1 "OnChange";
BA_ "GenSigSendType" SG_ 2463978663 VZE_Verkehrszeichen_2 "OnChange";
BA_ "GenSigSendType" SG_ 2463978663 VZE_Verkehrszeichen_3 "OnChange";
BA_ "GenSigSendType" SG_ 2463978663 VZE_Warnung_Verkehrszeichen_1 "OnChange";
BA_ "GenSigSendType" SG_ 2463978663 VZE_Warnung_Verkehrszeichen_2 "OnChange";
BA_ "GenSigSendType" SG_ 2463978663 VZE_Warnung_Verkehrszeichen_3 "OnChange";
BA_ "GenSigSendType" SG_ 2463978663 VZE_Zusatzschild_1 "OnChange";
BA_ "GenSigSendType" SG_ 2463978663 VZE_Zusatzschild_2 "OnChange";
BA_ "GenSigSendType" SG_ 2463978663 VZE_Zusatzschild_3 "OnChange";
BA_ "GenSigSendType" SG_ 2463978663 VZE_Anzeigeunterdrueck_Zeichen_1 "OnChange";
BA_ "GenSigSendType" SG_ 2463978663 VZE_Zeichen_01_KameraWied "OnChange";
BA_ "GenSigSendType" SG_ 2463978663 VZE_Zeichen_02_KameraWied "OnChange";
BA_ "GenSigSendType" SG_ 2463978663 VZE_Zeichen_03_KameraWied "OnChange";
BA_ "GenSigSendType" SG_ 2463978663 VZE_Zeichen_01_Kamera "OnChange";
BA_ "GenSigSendType" SG_ 2463978663 VZE_Zeichen_01_Karte "OnChange";
BA_ "GenSigSendType" SG_ 2463978663 VZE_Zeichen_01_Gesetz "OnChange";
BA_ "GenSigSendType" SG_ 2463978663 VZE_Zeichen_02_Kamera "OnChange";
BA_ "GenSigSendType" SG_ 2463978663 VZE_Zeichen_02_Karte "OnChange";
BA_ "GenSigSendType" SG_ 2463978663 VZE_Zeichen_02_Gesetz "OnChange";
BA_ "GenSigSendType" SG_ 2463978663 VZE_Zeichen_03_Kamera "OnChange";
BA_ "GenSigSendType" SG_ 2463978663 VZE_Zeichen_03_Karte "OnChange";
BA_ "GenSigSendType" SG_ 2463978663 VZE_Zeichen_03_Gesetz "OnChange";
BA_ "GenSigSendType" SG_ 2463978663 VZE_Gong "OnChange";
BA_ "GenSigSendType" SG_ 2463978663 VZE_Anzeigeunterdrueck_Zeichen_5 "OnChange";
BA_ "GenSigSendType" SG_ 2463978663 VZE_Zeichen_05_KameraWied "OnChange";
BA_ "GenSigSendType" SG_ 2463978663 VZE_Zeichen_05_Kamera "OnChange";
BA_ "GenSigSendType" SG_ 2463978663 VZE_Verkehrszeichen_4 "OnChange";
BA_ "GenSigSendType" SG_ 2463978663 VZE_Verkehrszeichen_5 "OnChange";
BA_ "GenSigSendType" SG_ 2463978663 VZE_Anhaenger_Vmax "OnChange";
BA_ "GenSigStartValue" SG_ 2463978663 VZE_Anhaenger_Vmax 14;
BA_ "Fehlerwert" SG_ 2463978663 VZE_Anhaenger_Vmax 15;
BA_ "GenSigSendType" SG_ 2463978663 VZE_Zeichen_04_Gesetz "OnChange";
BA_ "GenSigSendType" SG_ 2463978663 VZE_Zeichen_04_Kamera "OnChange";
BA_ "GenSigSendType" SG_ 2463978663 VZE_Zeichen_04_KameraWied "OnChange";
BA_ "GenSigSendType" SG_ 2463978663 VZE_Zeichen_04_Karte "OnChange";
BA_ "GenSigSendType" SG_ 2463978663 VZE_Warnung_Verkehrszeichen_4 "OnChange";
BA_ "GenSigSendType" SG_ 2463978663 VZE_Warnung_Verkehrszeichen_5 "OnChange";
BA_ "GenSigSendType" SG_ 2463978663 VZE_Zeichen_05_Gesetz "OnChange";
BA_ "GenSigSendType" SG_ 2463978663 VZE_Zusatzschild_4 "OnChange";
BA_ "GenSigSendType" SG_ 2463978663 VZE_Zusatzschild_5 "OnChange";
BA_ "GenSigSendType" SG_ 2463978663 VZE_Baustelle "OnChange";
BA_ "GenSigSendType" SG_ 2463978663 VZE_Zeichen_05_Karte "OnChange";
BA_ "GenSigSendType" SG_ 2463978663 VZE_Zeichen_05_Entfernung "Cyclic";
BA_ "GenSigSendType" SG_ 2463978663 VZE_Zeichen_05_Entfernung_StdA "Cyclic";
BA_ "GenSigSendType" SG_ 2463978663 VZE_Anzeigeunterdrueck_Zeichen_4 "OnChange";
BA_ "GenSigSendType" SG_ 2463978663 VZE_Verkehrszeichen_6 "Cyclic";
BA_ "GenSigSendType" SG_ 2463978663 VZE_Zusatzschild_6 "Cyclic";
BA_ "GenSigSendType" SG_ 2463978663 VZE_Zeichen_06_Entfernung "Cyclic";
BA_ "GenSigSendType" SG_ 2463978663 VZE_Zeichen_06_Entfernung_StdA "Cyclic";
BA_ "GenSigSendType" SG_ 2463978663 VZE_Umweltinfo_Naesse "Cyclic";
BA_ "GenSigSendType" SG_ 2463978663 VZE_Umweltinfo_Nebel "Cyclic";
BA_ "GenSigSendType" SG_ 2463978663 VZE_Umweltinfo_Anhaengerbetrieb "Cyclic";
BA_ "GenSigSendType" SG_ 2463978663 VZE_Erweiterte_Information "Cyclic";
BA_ "GenSigSendType" SG_ 2463978663 VZE_Tempowarnung_Status "Cyclic";
BA_ "GenSigSwitchedByIgnition" SG_ 2463978663 VZE_Tempowarnung_Status "No";
BA_ "GenSigSendType" SG_ 2463978663 VZE_Tempowarnung_Einheit "Cyclic";
BA_ "GenSigSendType" SG_ 2463978663 VZE_Tempowarnung_Offset "Cyclic";
BA_ "GenSigSendType" SG_ 2463978663 VZE_FoD_Status "Cyclic";
BA_ "GenSigSwitchedByIgnition" SG_ 2463978663 VZE_FoD_Status "No";
BA_ "GenSigSendType" SG_ 2463978663 VZE_Anzeige_ZS_1 "Cyclic";
BA_ "GenSigSwitchedByIgnition" SG_ 2463978663 VZE_Anzeige_ZS_1 "No";
BA_ "GenSigSendType" SG_ 2463978663 VZE_Anzeige_ZS_2 "Cyclic";
BA_ "GenSigSwitchedByIgnition" SG_ 2463978663 VZE_Anzeige_ZS_2 "No";
BA_ "GenSigSendType" SG_ 2463978663 VZE_Anzeige_ZS_3 "Cyclic";
BA_ "GenSigSwitchedByIgnition" SG_ 2463978663 VZE_Anzeige_ZS_3 "No";
BA_ "GenSigSendType" SG_ 2463978663 VZE_Hinweistext_03 "Cyclic";
BA_ "GenSigSwitchedByIgnition" SG_ 2463978663 VZE_Hinweistext_03 "No";
BA_ "GenSigSendType" SG_ 2463978663 VZE_Land "Cyclic";
BA_ "GenSigSwitchedByIgnition" SG_ 2463978663 VZE_Land "No";
BA_ "GenSigSendType" SG_ 2463978663 VZE_Warnung_VZ_1 "Cyclic";
BA_ "GenSigSwitchedByIgnition" SG_ 2463978663 VZE_Warnung_VZ_1 "No";
BA_ "GenSigSendType" SG_ 2463978663 VZE_Warnung_VZ_2 "Cyclic";
BA_ "GenSigSwitchedByIgnition" SG_ 2463978663 VZE_Warnung_VZ_2 "No";
BA_ "GenSigSendType" SG_ 2463978663 VZE_Warnung_VZ_3 "Cyclic";
BA_ "GenSigSwitchedByIgnition" SG_ 2463978663 VZE_Warnung_VZ_3 "No";
BA_ "GenSigSendType" SG_ 2463978663 VZE_Anzeige_VZ_1 "Cyclic";
BA_ "GenSigSwitchedByIgnition" SG_ 2463978663 VZE_Anzeige_VZ_1 "No";
BA_ "GenSigSendType" SG_ 2463978663 VZE_Anzeige_VZ_2 "Cyclic";
BA_ "GenSigSwitchedByIgnition" SG_ 2463978663 VZE_Anzeige_VZ_2 "No";
BA_ "GenSigSendType" SG_ 2463978663 VZE_Anzeige_VZ_3 "Cyclic";
BA_ "GenSigSwitchedByIgnition" SG_ 2463978663 VZE_Anzeige_VZ_3 "No";
BA_ "GenSigSendType" SG_ 181 Waehlhebel_04_CRC "Cyclic";
BA_ "GenSigFuncType" SG_ 181 Waehlhebel_04_CRC "CRC-8";
BA_ "GenSigSwitchedByIgnition" SG_ 181 Waehlhebel_04_CRC "No";
BA_ "GenSigSendType" SG_ 181 Waehlhebel_04_BZ "Cyclic";
BA_ "GenSigFuncType" SG_ 181 Waehlhebel_04_BZ "MsgCounter";
BA_ "GenSigSwitchedByIgnition" SG_ 181 Waehlhebel_04_BZ "No";
BA_ "GenSigSendType" SG_ 181 WH_gespeicherte_Fahrstufe "Cyclic";
BA_ "GenSigSwitchedByIgnition" SG_ 181 WH_gespeicherte_Fahrstufe "No";
BA_ "GenSigSendType" SG_ 181 WH_Initialisierung "Cyclic";
BA_ "GenSigStartValue" SG_ 181 WH_Initialisierung 1;
BA_ "GenSigSwitchedByIgnition" SG_ 181 WH_Initialisierung "No";
BA_ "GenSigSendType" SG_ 181 WH_SensorPos_roh "Cyclic";
BA_ "GenSigSwitchedByIgnition" SG_ 181 WH_SensorPos_roh "No";
BA_ "Fehlerwert" SG_ 181 WH_SensorPos_roh 15;
BA_ "GenSigSendType" SG_ 181 WH_SensorPos_roh_inv "Cyclic";
BA_ "GenSigStartValue" SG_ 181 WH_SensorPos_roh_inv 15;
BA_ "GenSigSwitchedByIgnition" SG_ 181 WH_SensorPos_roh_inv "No";
BA_ "GenSigSendType" SG_ 181 WH_Testergebnis "Cyclic";
BA_ "GenSigSwitchedByIgnition" SG_ 181 WH_Testergebnis "No";
BA_ "GenSigSendType" SG_ 181 WH_Test_Aktiv "Cyclic";
BA_ "GenSigSwitchedByIgnition" SG_ 181 WH_Test_Aktiv "No";
BA_ "GenSigSendType" SG_ 181 WH_Ist_Haltemagnet "Cyclic";
BA_ "GenSigSwitchedByIgnition" SG_ 181 WH_Ist_Haltemagnet "No";
BA_ "Fehlerwert" SG_ 181 WH_Ist_Haltemagnet 3;
BA_ "GenSigSendType" SG_ 181 WH_Variante "Cyclic";
BA_ "GenSigSwitchedByIgnition" SG_ 181 WH_Variante "No";
BA_ "GenSigSendType" SG_ 181 WH_Entsperrtaste_02 "Cyclic";
BA_ "GenSigSwitchedByIgnition" SG_ 181 WH_Entsperrtaste_02 "No";
BA_ "Fehlerwert" SG_ 181 WH_Entsperrtaste_02 3;
BA_ "GenSigSendType" SG_ 181 WH_P_Taste "Cyclic";
BA_ "GenSigSwitchedByIgnition" SG_ 181 WH_P_Taste "No";
BA_ "Fehlerwert" SG_ 181 WH_P_Taste 3;
BA_ "GenSigSendType" SG_ 181 WH_Ende_N_Haltephase "Cyclic";
BA_ "GenSigSwitchedByIgnition" SG_ 181 WH_Ende_N_Haltephase "No";
BA_ "GenSigSendType" SG_ 181 WH_Fahrstufe "Cyclic";
BA_ "GenSigSwitchedByIgnition" SG_ 181 WH_Fahrstufe "No";
BA_ "Fehlerwert" SG_ 181 WH_Fahrstufe 15;
BA_ "GenSigSendType" SG_ 181 WH_Status_Shiftlock "Cyclic";
BA_ "GenSigSwitchedByIgnition" SG_ 181 WH_Status_Shiftlock "No";
BA_ "Fehlerwert" SG_ 181 WH_Status_Shiftlock 7;
BA_ "GenSigSendType" SG_ 181 WH_Zustand_N_Haltephase "Cyclic";
BA_ "GenSigSwitchedByIgnition" SG_ 181 WH_Zustand_N_Haltephase "No";
BA_ "GenSigSendType" SG_ 2463978687 WH_Fehler_Haltemagnet_Status "OnChange";
BA_ "GenSigSwitchedByIgnition" SG_ 2463978687 WH_Fehler_Haltemagnet_Status "No";
BA_ "GenSigSendType" SG_ 2463978687 WH_Fehler_CRC_SBM "OnChange";
BA_ "GenSigSwitchedByIgnition" SG_ 2463978687 WH_Fehler_CRC_SBM "No";
BA_ "GenSigSendType" SG_ 2463978687 WH_Fehler_CRC_SBM_Status "OnChange";
BA_ "GenSigSwitchedByIgnition" SG_ 2463978687 WH_Fehler_CRC_SBM_Status "No";
BA_ "GenSigSendType" SG_ 2463978687 WH_Fehler_Timeout_SBM "OnChange";
BA_ "GenSigSwitchedByIgnition" SG_ 2463978687 WH_Fehler_Timeout_SBM "No";
BA_ "GenSigSendType" SG_ 2463978687 WH_Fehler_Timeout_SBM_Status "OnChange";
BA_ "GenSigSwitchedByIgnition" SG_ 2463978687 WH_Fehler_Timeout_SBM_Status "No";
BA_ "GenSigSendType" SG_ 2463978687 WH_Fehler_Ueberspannung "OnChange";
BA_ "GenSigSwitchedByIgnition" SG_ 2463978687 WH_Fehler_Ueberspannung "No";
BA_ "GenSigSendType" SG_ 2463978687 WH_Fehler_Ueberspannung_Status "OnChange";
BA_ "GenSigSwitchedByIgnition" SG_ 2463978687 WH_Fehler_Ueberspannung_Status "No";
BA_ "GenSigSendType" SG_ 2463978687 WH_Fehler_BZ_SBM "OnChange";
BA_ "GenSigSwitchedByIgnition" SG_ 2463978687 WH_Fehler_BZ_SBM "No";
BA_ "GenSigSendType" SG_ 2463978687 WH_Fehler_BZ_SBM_Status "OnChange";
BA_ "GenSigSwitchedByIgnition" SG_ 2463978687 WH_Fehler_BZ_SBM_Status "No";
BA_ "GenSigSendType" SG_ 2463978687 WH_Fehler_Unterspannung "OnChange";
BA_ "GenSigSwitchedByIgnition" SG_ 2463978687 WH_Fehler_Unterspannung "No";
BA_ "GenSigSendType" SG_ 2463978687 WH_Fehler_Unterspannung_Status "OnChange";
BA_ "GenSigSwitchedByIgnition" SG_ 2463978687 WH_Fehler_Unterspannung_Status "No";
BA_ "GenSigSendType" SG_ 2463978687 WH_Fehler_Ausleuchtung "OnChange";
BA_ "GenSigSwitchedByIgnition" SG_ 2463978687 WH_Fehler_Ausleuchtung "No";
BA_ "GenSigSendType" SG_ 2463978687 WH_Fehler_Ausleuchtung_Status "OnChange";
BA_ "GenSigSwitchedByIgnition" SG_ 2463978687 WH_Fehler_Ausleuchtung_Status "No";
BA_ "GenSigSendType" SG_ 2463978687 WH_Fehler_Entsperrtaste "OnChange";
BA_ "GenSigSwitchedByIgnition" SG_ 2463978687 WH_Fehler_Entsperrtaste "No";
BA_ "GenSigSendType" SG_ 2463978687 WH_Fehler_Entsperrtaste_Status "OnChange";
BA_ "GenSigSwitchedByIgnition" SG_ 2463978687 WH_Fehler_Entsperrtaste_Status "No";
BA_ "GenSigSendType" SG_ 2463978687 WH_Fehler_P_Taste "OnChange";
BA_ "GenSigSwitchedByIgnition" SG_ 2463978687 WH_Fehler_P_Taste "No";
BA_ "GenSigSendType" SG_ 2463978687 WH_Fehler_P_Taste_Status "OnChange";
BA_ "GenSigSwitchedByIgnition" SG_ 2463978687 WH_Fehler_P_Taste_Status "No";
BA_ "GenSigSendType" SG_ 2463978687 WH_Fehler_Sensor_einfach "OnChange";
BA_ "GenSigSwitchedByIgnition" SG_ 2463978687 WH_Fehler_Sensor_einfach "No";
BA_ "GenSigSendType" SG_ 2463978687 WH_Fehler_Sensor_einfach_Status "OnChange";
BA_ "GenSigSwitchedByIgnition" SG_ 2463978687 WH_Fehler_Sensor_einfach_Status "No";
BA_ "GenSigSendType" SG_ 2463978687 WH_Fehler_Sensor_mehrfach "OnChange";
BA_ "GenSigSwitchedByIgnition" SG_ 2463978687 WH_Fehler_Sensor_mehrfach "No";
BA_ "GenSigSendType" SG_ 2463978687 WH_Fehler_Sensor_mehrfach_Status "OnChange";
BA_ "GenSigSwitchedByIgnition" SG_ 2463978687 WH_Fehler_Sensor_mehrfach_Status "No";
BA_ "GenSigSendType" SG_ 2463978687 WH_Fehler_Shiftlock "OnChange";
BA_ "GenSigSwitchedByIgnition" SG_ 2463978687 WH_Fehler_Shiftlock "No";
BA_ "GenSigSendType" SG_ 2463978687 WH_Fehler_Shiftlock_Status "OnChange";
BA_ "GenSigSwitchedByIgnition" SG_ 2463978687 WH_Fehler_Shiftlock_Status "No";
BA_ "GenSigSendType" SG_ 916 WBA_03_CRC "Cyclic";
BA_ "GenSigFuncType" SG_ 916 WBA_03_CRC "CRC-8";
BA_ "GenSigSwitchedByIgnition" SG_ 916 WBA_03_CRC "No";
BA_ "GenSigSendType" SG_ 916 WBA_03_BZ "Cyclic";
BA_ "GenSigFuncType" SG_ 916 WBA_03_BZ "MsgCounter";
BA_ "GenSigSwitchedByIgnition" SG_ 916 WBA_03_BZ "No";
BA_ "GenSigSendType" SG_ 916 WBA_Fahrstufe_02 "OnChange";
BA_ "GenSigSwitchedByIgnition" SG_ 916 WBA_Fahrstufe_02 "No";
BA_ "GenSigSendType" SG_ 916 WBA_ZielFahrstufe "OnChange";
BA_ "GenSigSwitchedByIgnition" SG_ 916 WBA_ZielFahrstufe "No";
BA_ "GenSigSendType" SG_ 916 WBA_GE_Warnung_02 "OnChange";
BA_ "GenSigSwitchedByIgnition" SG_ 916 WBA_GE_Warnung_02 "No";
BA_ "GenSigSendType" SG_ 916 WBA_eing_Gang_02 "OnChange";
BA_ "GenSigSwitchedByIgnition" SG_ 916 WBA_eing_Gang_02 "No";
BA_ "GenSigSendType" SG_ 916 WBA_GE_Texte "OnChange";
BA_ "GenSigSwitchedByIgnition" SG_ 916 WBA_GE_Texte "No";
BA_ "GenSigSendType" SG_ 916 WBA_Segeln_aktiv "OnChange";
BA_ "GenSigSwitchedByIgnition" SG_ 916 WBA_Segeln_aktiv "No";
BA_ "GenSigSendType" SG_ 916 WBA_Schaltschema_02 "OnChange";
BA_ "GenSigSwitchedByIgnition" SG_ 916 WBA_Schaltschema_02 "No";
BA_ "GenSigSendType" SG_ 916 WBA_Schaltschema_FS_inaktiv "OnChange";
BA_ "GenSigSwitchedByIgnition" SG_ 916 WBA_Schaltschema_FS_inaktiv "No";
BA_ "GenSigSendType" SG_ 916 WBA_GE_Zusatzwarnungen "OnChange";
BA_ "GenSigSwitchedByIgnition" SG_ 916 WBA_GE_Zusatzwarnungen "No";
BA_ "GenSigSendType" SG_ 916 GE_Sollgang "OnChange";
BA_ "GenSigSwitchedByIgnition" SG_ 916 GE_Sollgang "No";
BA_ "GenSigSendType" SG_ 916 GE_Tipschaltempf_verfuegbar "Cyclic";
BA_ "GenSigFuncType" SG_ 916 GE_Tipschaltempf_verfuegbar "Constant";
BA_ "GenSigSwitchedByIgnition" SG_ 916 GE_Tipschaltempf_verfuegbar "No";
BA_ "GenSigSendType" SG_ 916 WBA_GE_Texte_02 "Cyclic";
BA_ "GenSigSwitchedByIgnition" SG_ 916 WBA_GE_Texte_02 "No";
BA_ "GenSigSendType" SG_ 916 WBA_Schaltschema_Tippgasse "OnChange";
BA_ "GenSigSwitchedByIgnition" SG_ 916 WBA_Schaltschema_Tippgasse "No";
BA_ "GenSigSendType" SG_ 916 WBA_Schaltschema_Fahreraktion "OnChange";
BA_ "GenSigSwitchedByIgnition" SG_ 916 WBA_Schaltschema_Fahreraktion "No";
BA_ "GenSigSendType" SG_ 916 WBA_Schaltschema_FS_vorwaerts "OnChange";
BA_ "GenSigSwitchedByIgnition" SG_ 916 WBA_Schaltschema_FS_vorwaerts "No";
BA_ "GenSigSendType" SG_ 916 WBA_Shiftlock_Lampe "OnChange";
BA_ "GenSigSwitchedByIgnition" SG_ 916 WBA_Shiftlock_Lampe "No";
BA_ "GenSigSendType" SG_ 916 WBA_Anforderung_Akustik "OnChange";
BA_ "GenSigSwitchedByIgnition" SG_ 916 WBA_Anforderung_Akustik "No";
BA_ "GenSigSendType" SG_ 916 WBA_Blinken "OnChange";
BA_ "GenSigSwitchedByIgnition" SG_ 916 WBA_Blinken "No";
BA_ "GenSigSendType" SG_ 916 GE_Wiederstart_Anz_Std "Cyclic";
BA_ "GenSigSwitchedByIgnition" SG_ 916 GE_Wiederstart_Anz_Std "No";
BA_ "GenSigSendType" SG_ 916 GE_Stoppverbot_Anz_01 "Cyclic";
BA_ "GenSigSwitchedByIgnition" SG_ 916 GE_Stoppverbot_Anz_01 "No";
BA_ "GenSigSendType" SG_ 916 GE_Stoppverbot_Anz_02 "Cyclic";
BA_ "GenSigSwitchedByIgnition" SG_ 916 GE_Stoppverbot_Anz_02 "No";
BA_ "GenSigSendType" SG_ 916 GE_Stoppverbot_Anz_03 "Cyclic";
BA_ "GenSigSwitchedByIgnition" SG_ 916 GE_Stoppverbot_Anz_03 "No";
BA_ "GenSigSendType" SG_ 916 GE_Stoppverbot_Anz_04 "Cyclic";
BA_ "GenSigSwitchedByIgnition" SG_ 916 GE_Stoppverbot_Anz_04 "No";
BA_ "GenSigSendType" SG_ 916 GE_Stoppverbot_Anz_05 "Cyclic";
BA_ "GenSigSwitchedByIgnition" SG_ 916 GE_Stoppverbot_Anz_05 "No";
BA_ "GenSigSendType" SG_ 916 GE_Stoppverbot_Anz_06 "Cyclic";
BA_ "GenSigSwitchedByIgnition" SG_ 916 GE_Stoppverbot_Anz_06 "No";
BA_ "GenSigSendType" SG_ 916 GE_Stoppverbot_Anz_07 "Cyclic";
BA_ "GenSigSwitchedByIgnition" SG_ 916 GE_Stoppverbot_Anz_07 "No";
BA_ "GenSigSendType" SG_ 916 GE_Stoppverbot_Anz_Std "Cyclic";
BA_ "GenSigSwitchedByIgnition" SG_ 916 GE_Stoppverbot_Anz_Std "No";
BA_ "GenSigSendType" SG_ 1361 WFS_Schluessel_Fahrberecht "Cyclic";
BA_ "GenSigSwitchedByIgnition" SG_ 1361 WFS_Schluessel_Fahrberecht "No";
BA_ "GenSigSendType" SG_ 1361 WFS_Verbauinfo_ELV "OnChange";
BA_ "GenSigSwitchedByIgnition" SG_ 1361 WFS_Verbauinfo_ELV "No";
BA_ "GenSigSendType" SG_ 1361 WFS_ID_Geb_autorisiert "OnChange";
BA_ "GenSigSwitchedByIgnition" SG_ 1361 WFS_ID_Geb_autorisiert "No";
BA_ "GenSigSendType" SG_ 1361 WFS_ID_Geb_autorisiert_in_Kl15 "OnChange";
BA_ "GenSigSwitchedByIgnition" SG_ 1361 WFS_ID_Geb_autorisiert_in_Kl15 "No";
BA_ "GenSigSendType" SG_ 1361 WFS_ID_Geb_steckt "OnChange";
BA_ "GenSigSwitchedByIgnition" SG_ 1361 WFS_ID_Geb_steckt "No";
BA_ "GenSigSendType" SG_ 1361 WFS_Schluessel_Soll "OnChange";
BA_ "GenSigSwitchedByIgnition" SG_ 1361 WFS_Schluessel_Soll "No";
BA_ "GenSigSendType" SG_ 1361 WFS_Schluessel_Ist "OnChange";
BA_ "GenSigSwitchedByIgnition" SG_ 1361 WFS_Schluessel_Ist "No";
BA_ "GenSigSendType" SG_ 1361 WFS_Safe "OnChange";
BA_ "GenSigSwitchedByIgnition" SG_ 1361 WFS_Safe "No";
BA_ "GenSigSendType" SG_ 1361 WFS_LZ "OnChange";
BA_ "GenSigSwitchedByIgnition" SG_ 1361 WFS_LZ "No";
BA_ "GenSigSendType" SG_ 1361 WFS_ELV_authorisiert "OnChange";
BA_ "GenSigSwitchedByIgnition" SG_ 1361 WFS_ELV_authorisiert "No";
BA_ "GenSigSendType" SG_ 1361 WFS_LF_Aktiv "OnChange";
BA_ "GenSigSwitchedByIgnition" SG_ 1361 WFS_LF_Aktiv "No";
BA_ "GenSigSendType" SG_ 1361 WFS_Betrieb_Lesespule "OnChange";
BA_ "GenSigSwitchedByIgnition" SG_ 1361 WFS_Betrieb_Lesespule "No";
BA_ "GenSigSendType" SG_ 1361 WFS_Klemmenfreigabe "OnChange";
BA_ "GenSigSwitchedByIgnition" SG_ 1361 WFS_Klemmenfreigabe "No";
BA_ "GenSigSendType" SG_ 1361 WFS_Klemmenfreigabe_Signatur "OnChange";
BA_ "GenSigSwitchedByIgnition" SG_ 1361 WFS_Klemmenfreigabe_Signatur "No";
BA_ "GenSigSendType" SG_ 1361 WFS_Fahrerhinweise "OnChange";
BA_ "GenSigSwitchedByIgnition" SG_ 1361 WFS_Fahrerhinweise "No";
BA_ "GenSigSendType" SG_ 1361 WFS_Parken_Status "OnChange";
BA_ "GenSigSwitchedByIgnition" SG_ 1361 WFS_Parken_Status "No";
BA_ "GenSigSwitchedByIgnition" SG_ 2617028096 XCP_Airbag_CRO_01_Data "No";
BA_ "GenSigSwitchedByIgnition" SG_ 2617028097 XCP_Airbag_DTO_01_Data "No";
BA_ "GenSigFuncType" SG_ 2617239040 XCP_EMotor_01_CRO_01_Data "Protocol";
BA_ "GenSigSwitchedByIgnition" SG_ 2617239040 XCP_EMotor_01_CRO_01_Data "No";
BA_ "GenSigFuncType" SG_ 2617239041 XCP_EMotor_01_DTO_01_Data "Protocol";
BA_ "GenSigSwitchedByIgnition" SG_ 2617239041 XCP_EMotor_01_DTO_01_Data "No";
BA_ "GenSigSwitchedByIgnition" SG_ 2617239042 XCP_EMotor_01_DTO_02_Data "No";
BA_ "GenSigSwitchedByIgnition" SG_ 2617239043 XCP_EMotor_01_DTO_03_Data "No";
BA_ "GenSigSwitchedByIgnition" SG_ 2617239044 XCP_EMotor_01_DTO_04_Data "No";
BA_ "GenSigFuncType" SG_ 2617122304 XCP_EMotor_02_CRO_01_Data "Protocol";
BA_ "GenSigSwitchedByIgnition" SG_ 2617122304 XCP_EMotor_02_CRO_01_Data "No";
BA_ "GenSigFuncType" SG_ 2617122305 XCP_EMotor_02_DTO_01_Data "Protocol";
BA_ "GenSigSwitchedByIgnition" SG_ 2617122305 XCP_EMotor_02_DTO_01_Data "No";
BA_ "GenSigFuncType" SG_ 2617122306 XCP_EMotor_02_DTO_02_Data "Protocol";
BA_ "GenSigSwitchedByIgnition" SG_ 2617122306 XCP_EMotor_02_DTO_02_Data "No";
BA_ "GenSigFuncType" SG_ 2617122307 XCP_EMotor_02_DTO_03_Data "Protocol";
BA_ "GenSigSwitchedByIgnition" SG_ 2617122307 XCP_EMotor_02_DTO_03_Data "No";
BA_ "GenSigFuncType" SG_ 2617122308 XCP_EMotor_02_DTO_04_Data "Protocol";
BA_ "GenSigSwitchedByIgnition" SG_ 2617122308 XCP_EMotor_02_DTO_04_Data "No";
BA_ "GenSigFuncType" SG_ 2617226768 XCP_Motor_CRO_01_Data "Protocol";
BA_ "GenSigSwitchedByIgnition" SG_ 2617226768 XCP_Motor_CRO_01_Data "No";
BA_ "GenSigFuncType" SG_ 2617226769 XCP_Motor_DTO_01_Data "Protocol";
BA_ "GenSigSwitchedByIgnition" SG_ 2617226769 XCP_Motor_DTO_01_Data "No";
BA_ "GenSigSendType" SG_ 1411 ZV_verriegeln_Anf "IfActiveWithRepetition";
BA_ "GenSigSwitchedByIgnition" SG_ 1411 ZV_verriegeln_Anf "No";
BA_ "GenSigSendType" SG_ 1411 ZV_STSG_HFS_Anf "OnChange";
BA_ "GenSigSwitchedByIgnition" SG_ 1411 ZV_STSG_HFS_Anf "No";
BA_ "GenSigSendType" SG_ 1411 ZV_STSG_HBFS_Anf "OnChange";
BA_ "GenSigSwitchedByIgnition" SG_ 1411 ZV_STSG_HBFS_Anf "No";
BA_ "GenSigSendType" SG_ 1411 ZV_Anf_Challenge_Auth "IfActiveWithRepetition";
BA_ "GenSigSwitchedByIgnition" SG_ 1411 ZV_Anf_Challenge_Auth "No";
BA_ "GenSigSendType" SG_ 1411 BCM_FH_Freigabe "OnChange";
BA_ "GenSigSwitchedByIgnition" SG_ 1411 BCM_FH_Freigabe "No";
BA_ "GenSigSendType" SG_ 1411 BCM_Komfortfkt_Freigabe "OnChange";
BA_ "GenSigSwitchedByIgnition" SG_ 1411 BCM_Komfortfkt_Freigabe "No";
BA_ "GenSigSendType" SG_ 1411 BCM_HSK_Freigabe "OnChange";
BA_ "GenSigSwitchedByIgnition" SG_ 1411 BCM_HSK_Freigabe "No";
BA_ "GenSigSendType" SG_ 1411 BCM_Verdeck_Freigabe "OnChange";
BA_ "GenSigSwitchedByIgnition" SG_ 1411 BCM_Verdeck_Freigabe "No";
BA_ "GenSigSendType" SG_ 1411 ZV_verriegelt_intern_ist "OnChange";
BA_ "GenSigSwitchedByIgnition" SG_ 1411 ZV_verriegelt_intern_ist "No";
BA_ "GenSigSendType" SG_ 1411 ZV_verriegelt_extern_ist "OnChange";
BA_ "GenSigSwitchedByIgnition" SG_ 1411 ZV_verriegelt_extern_ist "No";
BA_ "GenSigSendType" SG_ 1411 ZV_verriegelt_intern_soll "OnChange";
BA_ "GenSigSwitchedByIgnition" SG_ 1411 ZV_verriegelt_intern_soll "No";
BA_ "GenSigSendType" SG_ 1411 ZV_verriegelt_extern_soll "OnChange";
BA_ "GenSigSwitchedByIgnition" SG_ 1411 ZV_verriegelt_extern_soll "No";
BA_ "GenSigSendType" SG_ 1411 ZV_gesafet_extern_ist "OnChange";
BA_ "GenSigSwitchedByIgnition" SG_ 1411 ZV_gesafet_extern_ist "No";
BA_ "GenSigSendType" SG_ 1411 ZV_gesafet_extern_soll "OnChange";
BA_ "GenSigSwitchedByIgnition" SG_ 1411 ZV_gesafet_extern_soll "No";
BA_ "GenSigSendType" SG_ 1411 ZV_Einzeltuerentriegelung "OnChange";
BA_ "GenSigSwitchedByIgnition" SG_ 1411 ZV_Einzeltuerentriegelung "No";
BA_ "GenSigSendType" SG_ 1411 ZV_Heckeinzelentriegelung "OnChange";
BA_ "GenSigSwitchedByIgnition" SG_ 1411 ZV_Heckeinzelentriegelung "No";
BA_ "GenSigSendType" SG_ 1411 ZV_FT_offen "OnChange";
BA_ "GenSigSwitchedByIgnition" SG_ 1411 ZV_FT_offen "No";
BA_ "GenSigSendType" SG_ 1411 ZV_BT_offen "OnChange";
BA_ "GenSigSwitchedByIgnition" SG_ 1411 ZV_BT_offen "No";
BA_ "GenSigSendType" SG_ 1411 ZV_HFS_offen "OnChange";
BA_ "GenSigSwitchedByIgnition" SG_ 1411 ZV_HFS_offen "No";
BA_ "GenSigSendType" SG_ 1411 ZV_HBFS_offen "OnChange";
BA_ "GenSigSwitchedByIgnition" SG_ 1411 ZV_HBFS_offen "No";
BA_ "GenSigSendType" SG_ 1411 ZV_HD_offen "OnChange";
BA_ "GenSigSwitchedByIgnition" SG_ 1411 ZV_HD_offen "No";
BA_ "GenSigSendType" SG_ 1411 ZV_HS_offen "OnChange";
BA_ "GenSigSwitchedByIgnition" SG_ 1411 ZV_HS_offen "No";
BA_ "GenSigSendType" SG_ 1411 IRUE_aktiv "OnChange";
BA_ "GenSigSwitchedByIgnition" SG_ 1411 IRUE_aktiv "No";
BA_ "GenSigSendType" SG_ 1411 DWA_aktiv "OnChange";
BA_ "GenSigSwitchedByIgnition" SG_ 1411 DWA_aktiv "No";
BA_ "GenSigSendType" SG_ 1411 FFB_HDF_Taste "IfActiveWithRepetition";
BA_ "GenSigSwitchedByIgnition" SG_ 1411 FFB_HDF_Taste "No";
BA_ "GenSigSendType" SG_ 1411 FFB_Panik_Taste "IfActiveWithRepetition";
BA_ "GenSigSwitchedByIgnition" SG_ 1411 FFB_Panik_Taste "No";
BA_ "GenSigSendType" SG_ 1411 FFB_Auf_Taste "IfActiveWithRepetition";
BA_ "GenSigSwitchedByIgnition" SG_ 1411 FFB_Auf_Taste "No";
BA_ "GenSigSendType" SG_ 1411 FFB_Zu_Taste "IfActiveWithRepetition";
BA_ "GenSigSwitchedByIgnition" SG_ 1411 FFB_Zu_Taste "No";
BA_ "GenSigSendType" SG_ 1411 FFB_CarFinder "IfActiveWithRepetition";
BA_ "GenSigSwitchedByIgnition" SG_ 1411 FFB_CarFinder "No";
BA_ "GenSigSendType" SG_ 1411 FFB_Komfortoeffnen "IfActiveWithRepetition";
BA_ "GenSigSwitchedByIgnition" SG_ 1411 FFB_Komfortoeffnen "No";
BA_ "GenSigSendType" SG_ 1411 FFB_Komfortschliessen "IfActiveWithRepetition";
BA_ "GenSigSwitchedByIgnition" SG_ 1411 FFB_Komfortschliessen "No";
BA_ "GenSigSendType" SG_ 1411 FBS_IDG_in_Reichweite "IfActiveWithRepetition";
BA_ "GenSigSwitchedByIgnition" SG_ 1411 FBS_IDG_in_Reichweite "No";
BA_ "GenSigSendType" SG_ 1411 ZV_Schluessel_Zugang "OnChange";
BA_ "GenSigSwitchedByIgnition" SG_ 1411 ZV_Schluessel_Zugang "No";
BA_ "GenSigSendType" SG_ 1411 ZV_SafeFunktion_aktiv "OnChange";
BA_ "GenSigSwitchedByIgnition" SG_ 1411 ZV_SafeFunktion_aktiv "No";
BA_ "GenSigSendType" SG_ 1411 FBS_Warn_Schluessel_Batt "OnChange";
BA_ "GenSigSwitchedByIgnition" SG_ 1411 FBS_Warn_Schluessel_Batt "No";
BA_ "GenSigSendType" SG_ 1411 ZV_Oeffnungsmodus "OnChange";
BA_ "GenSigSwitchedByIgnition" SG_ 1411 ZV_Oeffnungsmodus "No";
BA_ "GenSigSendType" SG_ 1411 ZV_ist_Zustand_verfuegbar "OnChange";
BA_ "GenSigSwitchedByIgnition" SG_ 1411 ZV_ist_Zustand_verfuegbar "No";
BA_ "GenSigSendType" SG_ 1411 IRUE_Taster_Fkts_LED "OnChange";
BA_ "GenSigSwitchedByIgnition" SG_ 1411 IRUE_Taster_Fkts_LED "No";
BA_ "GenSigSendType" SG_ 1411 ZV_Tankklappe_offen "Cyclic";
BA_ "GenSigSwitchedByIgnition" SG_ 1411 ZV_Tankklappe_offen "No";
BA_ "GenSigSendType" SG_ 1411 ZV_Rollo_auf "OnChange";
BA_ "GenSigSwitchedByIgnition" SG_ 1411 ZV_Rollo_auf "No";
BA_ "GenSigSendType" SG_ 1411 ZV_Rollo_zu "OnChange";
BA_ "GenSigSwitchedByIgnition" SG_ 1411 ZV_Rollo_zu "No";
BA_ "GenSigSendType" SG_ 1411 ZV_SAD_auf "OnChange";
BA_ "GenSigSwitchedByIgnition" SG_ 1411 ZV_SAD_auf "No";
BA_ "GenSigSendType" SG_ 1411 ZV_SAD_zu "OnChange";
BA_ "GenSigSwitchedByIgnition" SG_ 1411 ZV_SAD_zu "No";
BA_ "GenSigSendType" SG_ 1411 ZV_verriegelt_soll "OnChange";
BA_ "GenSigSwitchedByIgnition" SG_ 1411 ZV_verriegelt_soll "No";
VAL_ 1019 TSK_Ausrollkurve_Schub_Reku_01 127 "Init";
VAL_ 1019 TSK_Ausrollkurve_Schub_Reku_05 127 "Init";
VAL_ 1019 TSK_Ausrollkurve_Schub_Reku_09 127 "Init";
VAL_ 1019 TSK_Ausrollkurve_Schub_Reku_13 127 "Init";
VAL_ 1019 TSK_Ausrollkurve_Schub_Reku_17 127 "Init";
VAL_ 1019 TSK_Ausrollkurve_Schub_Reku_02 127 "Init";
VAL_ 1019 TSK_Ausrollkurve_Schub_Reku_06 127 "Init";
VAL_ 1019 TSK_Ausrollkurve_Schub_Reku_10 127 "Init";
VAL_ 1019 TSK_Ausrollkurve_Schub_Reku_14 127 "Init";
VAL_ 1019 TSK_Ausrollkurve_Schub_Reku_18 127 "Init";
VAL_ 1019 TSK_Ausrollkurve_Schub_Reku_03 127 "Init";
VAL_ 1019 TSK_Ausrollkurve_Schub_Reku_07 127 "Init";
VAL_ 1019 TSK_Ausrollkurve_Schub_Reku_11 127 "Init";
VAL_ 1019 TSK_Ausrollkurve_Schub_Reku_15 127 "Init";
VAL_ 1019 TSK_Ausrollkurve_Schub_Reku_19 127 "Init";
VAL_ 1019 TSK_Ausrollkurve_Schub_Reku_04 127 "Init";
VAL_ 1019 TSK_Ausrollkurve_Schub_Reku_08 127 "Init";
VAL_ 1019 TSK_Ausrollkurve_Schub_Reku_12 127 "Init";
VAL_ 1019 TSK_Ausrollkurve_Schub_Reku_16 127 "Init";
VAL_ 1019 TSK_Ausrollkurve_Schub_Reku_20 127 "Init";
VAL_ 1019 TSK_Ausrollkurve_Segeln_01 127 "Init";
VAL_ 1019 TSK_Ausrollkurve_Segeln_05 127 "Init";
VAL_ 1019 TSK_Ausrollkurve_Segeln_09 127 "Init";
VAL_ 1019 TSK_Ausrollkurve_Segeln_13 127 "Init";
VAL_ 1019 TSK_Ausrollkurve_Segeln_17 127 "Init";
VAL_ 1019 TSK_Ausrollkurve_Segeln_02 127 "Init";
VAL_ 1019 TSK_Ausrollkurve_Segeln_06 127 "Init";
VAL_ 1019 TSK_Ausrollkurve_Segeln_10 127 "Init";
VAL_ 1019 TSK_Ausrollkurve_Segeln_14 127 "Init";
VAL_ 1019 TSK_Ausrollkurve_Segeln_18 127 "Init";
VAL_ 1019 TSK_Ausrollkurve_Segeln_03 127 "Init";
VAL_ 1019 TSK_Ausrollkurve_Segeln_07 127 "Init";
VAL_ 1019 TSK_Ausrollkurve_Segeln_11 127 "Init";
VAL_ 1019 TSK_Ausrollkurve_Segeln_15 127 "Init";
VAL_ 1019 TSK_Ausrollkurve_Segeln_19 127 "Init";
VAL_ 1019 TSK_Ausrollkurve_Segeln_04 127 "Init";
VAL_ 1019 TSK_Ausrollkurve_Segeln_08 127 "Init";
VAL_ 1019 TSK_Ausrollkurve_Segeln_12 127 "Init";
VAL_ 1019 TSK_Ausrollkurve_Segeln_16 127 "Init";
VAL_ 1019 TSK_Ausrollkurve_Segeln_20 127 "Init";
VAL_ 1019 TSK_Ausrollkurve_Reku 0 "Rekuperation_nicht_beruecksichtigt" 1 "Rekuperation_beruecksichtigt";
VAL_ 1019 TSK_Ausrollkurve_Schrittweite 0 "Normale_Schrittweite" 1 "Grosse_Schrittweite";
VAL_ 261 HMS_P_beibehalten_GE 0 "P_nicht_beibehalten" 1 "P_beibehalten" 2 "Init" 3 "Fehler";
VAL_ 261 VZM_Unterdrueckung_Antriebsmom 0 "Pos_Antriebsmoment_moeglich" 1 "Pos_Antriebsmoment_unterdruecken";
VAL_ 261 HMS_halten_nicht_verfuegbar 0 "verfuegbar" 1 "nicht_verfuegbar";
VAL_ 261 HMS_parken_nicht_verfuegbar 0 "verfuegbar" 1 "nicht_verfuegbar";
VAL_ 261 HMS_Anforderung_GE 0 "keine_Anforderung" 1 "P_einlegen";
VAL_ 261 HMS_Systemstatus 0 "keine_Funktion_aktiv" 1 "Halten_aktiv" 2 "Parken_angefordert" 3 "Parken_aktiv" 4 "Parken_beibehalten_aktiv" 5 "Anfahren_aktiv" 6 "Loeseanforderung_aktiv" 7 "Loeseanforderung_durch_Fahrer" 8 "Abrutschen_erkannt" 9 "Halten_Standby_aktiv" 10 "Anfahren_Standby_aktiv" 14 "Init" 15 "Fehler";
VAL_ 261 HMS_Stillstand 0 "kein_Stillstand" 1 "Stillstand_frueh" 2 "Stillstand" 6 "Init" 7 "Fehler";
VAL_ 261 HMS_aktives_System 0 "kein_System__Init_Fehler" 1 "Fahreranforderung_aktiv" 2 "HMS_intern_aktiv" 3 "ACC_aktiv" 4 "Autohold_aktiv" 5 "HHC_aktiv" 6 "HVLM_aktiv" 7 "Getriebe_aktiv" 8 "EBKV_aktiv" 9 "ParkAssist_aktiv" 10 "ARA_aktiv" 12 "autonomous_Hold_aktiv" 13 "STA_aktiv" 14 "Motor_aktiv" 15 "EA_aktiv" 16 "VLK_aktiv";
VAL_ 261 VMM_Inkonsistenz_GE 0 "konsistent" 1 "nicht_konsistent";
VAL_ 261 VMM_Inkonsistenz_HVLM 0 "konsistent" 1 "nicht_konsistent";
VAL_ 261 HMS_Fehlerstatus 0 "kein_Fehler" 1 "Halten_nicht_moeglich" 2 "Sonderbetriebsmodus_aktiv" 3 "Systemeinschraenkung" 4 "Systemstoerung";
VAL_ 261 HMS_Index_Haltemoment 0 "Bremsmoment" 1 "Antriebsmoment";
VAL_ 261 HMS_Haltemoment 1022 "Init" 1023 "Fehler";
VAL_ 313 VZM_aktiver_Basisservice 0 "Keine_Aktivitaet" 1 "Bremsenkonditionierung" 2 "Bremsruck" 3 "Verzoegerungsregelung" 4 "Wegregelung";
VAL_ 313 VZM_Anhalteweg_nicht_verfuegbar 0 "verfuegbar" 1 "nicht_verfuegbar";
VAL_ 313 VZM_Fahrer_bremst 0 "Bremsdruckschwelle_nicht_ueberschritten" 1 "Bremsdruckschwelle_ueberschritten";
VAL_ 313 VZM_QBit_Fahrer_bremst 0 "gueltiger_Wert" 1 "Ersatz_Init_oder_Fehlerwert";
VAL_ 313 VMM_MKB_codiert 0 "MKB_nicht_codiert" 1 "MKB_codiert";
VAL_ 313 VMM_Inkonsistenz_EBKV 0 "konsistent" 1 "nicht_konsistent";
VAL_ 313 VMM_Notstopp_Status 0 "Init" 1 "verfuegbar" 2 "warten_auf_sekundaer_System" 3 "passiv_Ueberwachung" 4 "aktiv_ausgeloest" 7 "Fehler";
VAL_ 313 VZM_Warnruck_nicht_verfuegbar 0 "verfuegbar" 1 "nicht_verfuegbar";
VAL_ 313 VZM_Warnruckeln_nicht_verfuegbar 0 "verfuegbar" 1 "nicht_verfuegbar";
VAL_ 313 VZM_Bkd_nicht_verfuegbar 0 "verfuegbar" 1 "nicht_verfuegbar";
VAL_ 313 VMM_Bremslicht_defekt 0 "Bremslichter_nicht_defekt" 1 "Bremslichter_defekt";
VAL_ 313 VZM_Fahrer_bremst_deutlich 0 "Fahrer_bremst_nicht_deutlich" 1 "Fahrer_bremst_deutlich";
VAL_ 313 VZM_TSK_SRBM_Anf 0 "keine_Aktivitaet" 1 "Aktivitaet_durch_TSK";
VAL_ 313 VZM_TSK_SRBM_nicht_verfuegbar 0 "verfuegbar" 1 "nicht_verfuegbar";
VAL_ 313 VZM_Verz_Reg_aktiv 8 "Aktivitaet_durch_ARA" 0 "keine_Aktivitaet" 2 "Aktivitaet_durch_AWV_PCF" 3 "Aktivitaet_durch_EA" 4 "Aktivitaet_durch_TSK" 5 "Aktivitaet_durch_RCTA" 6 "Aktivitaet_durch_ParkAssist" 7 "Aktivitaet_durch_ACC" 9 "Aktivitaet_durch_NV" 10 "Aktivitaet_durch_KAS" 11 "Aktivitaet_durch_FAS_VK" 12 "Aktivitaet_durch_vESC" 13 "Aktivitaet_durch_KAM" 14 "Aktivitaet_durch_BRS_intern" 15 "Aktivitaet_durch_AEB" 16 "Aktivitaet_durch_MKB";
VAL_ 313 VZM_Verz_Reg_nicht_verfuegbar 0 "verfuegbar" 1 "nicht_verfuegbar";
VAL_ 313 VMM_Inkonsistenz_KAS 0 "konsistent" 1 "nicht_konsistent";
VAL_ 313 VMM_Bremslicht_unplausibel 0 "plausibel" 1 "unplausibel";
VAL_ 313 VMM_Inkonsistenz_ACC 0 "konsistent" 1 "nicht_konsistent";
VAL_ 313 VMM_Inkonsistenz_AWV_PCF 0 "konsistent" 1 "nicht_konsistent";
VAL_ 313 VMM_Inkonsistenz_ARA 0 "konsistent" 1 "nicht_konsistent";
VAL_ 313 VMM_Inkonsistenz_ParkAssist 0 "konsistent" 1 "nicht_konsistent";
VAL_ 313 VMM_Inkonsistenz_FAS_VK 0 "konsistent" 1 "nicht_konsistent";
VAL_ 313 VMM_Inkonsistenz_NV 0 "konsistent" 1 "nicht_konsistent";
VAL_ 313 VMM_Inkonsistenz_RCTA 0 "konsistent" 1 "nicht_konsistent";
VAL_ 313 VMM_Inkonsistenz_TSK 0 "konsistent" 1 "nicht_konsistent";
VAL_ 313 VMM_Inkonsistenz_MO 0 "konsistent" 1 "nicht_konsistent";
VAL_ 313 VMM_Inkonsistenz_AEB 0 "konsistent" 1 "nicht_konsistent";
VAL_ 313 VMM_Fahrer_Bremskraft_bestimmend 0 "Nicht_Bremskraft_bestimmend" 1 "Bremskraft_bestimmend";
VAL_ 313 VMM_Inkonsistenz_EA 0 "konsistent" 1 "nicht_konsistent";
VAL_ 313 VZM_Status_Wegregelung 0 "Inaktiv" 1 "Passiv" 2 "Aktiv" 3 "Passiv_Ueberwachend";
VAL_ 313 VZM_Verz_ASIL_Verfuegbarkeit 0 "Nicht_verfuegbar" 1 "Verfuegbar_ab_ASIL_QM" 2 "Verfuegbar_ab_ASIL_A" 3 "Verfuegbar_ab_ASIL_B" 4 "Verfuegbar_ab_ASIL_C";
VAL_ 313 VZM_aktives_System 0 "Kein_aktiver_Teilnehmer" 1 "VZM_intern" 2 "AWV_PCF" 3 "EA" 4 "TSK" 5 "RCTA" 6 "ParkAssist" 7 "ACC" 8 "ARA" 9 "NV" 10 "KAS" 11 "FAS_VK" 12 "vESC" 13 "KAM" 14 "reserviert" 15 "AEB" 16 "MKB";
VAL_ 313 VZM_Verz_Begrenzung 0 "keine_Begrenzung" 1 "Begrenzung_aktiv";
VAL_ 313 VZM_Systemstatus 0 "Initialisierung" 1 "Verfuegbar" 2 "Verfuegbar_eingeschr_Performance" 3 "Nicht_Verfuegbar" 4 "Fehler" 5 "Sonderbetriebsmodus";
VAL_ 313 VZM_SRBM_Soll 4094 "Init" 4095 "Fehler";
VAL_ 313 VZM_SRBM_Ist 4094 "Init" 4095 "Fehler";
VAL_ 313 VZM_SRBM_max_Gradient 126 "Init" 127 "Fehler";
VAL_ 313 VMM_Inkonsistenz_KAM 0 "konsistent" 1 "nicht_konsistent";
VAL_ 2463978663 VZE_Anzeigemodus 0 "EU_RDW" 1 "USA" 2 "Canada" 3 "China";
VAL_ 2463978663 VZE_Hinweistext 0 "kein_Hinweistext";
VAL_ 2463978663 VZE_Verkehrszeichen_Einheit 0 "kmh" 1 "mph";
VAL_ 2463978663 VZE_Anzeigeunterdrueck_Zeichen_3 0 "anzeigerelevant" 1 "nicht_anzeigerelevant";
VAL_ 2463978663 VZE_Anzeigeunterdrueck_Zeichen_2 0 "anzeigerelevant" 1 "nicht_anzeigerelevant";
VAL_ 2463978663 VZE_Verkehrszeichen_1 0 "kein_Verkehrszeichen";
VAL_ 2463978663 VZE_Verkehrszeichen_2 0 "kein_Verkehrszeichen";
VAL_ 2463978663 VZE_Verkehrszeichen_3 0 "kein_Verkehrszeichen";
VAL_ 2463978663 VZE_Warnung_Verkehrszeichen_1 0 "keine_Warnung_Initialwert_Fehlerwert" 1 "Warnung";
VAL_ 2463978663 VZE_Warnung_Verkehrszeichen_2 0 "keine_Warnung_Initialwert_Fehlerwert" 1 "Warnung";
VAL_ 2463978663 VZE_Warnung_Verkehrszeichen_3 0 "keine_Warnung_Initialwert_Fehlerwert" 1 "Warnung";
VAL_ 2463978663 VZE_Zusatzschild_1 0 "keine_Zusatzschild_Initialwert_Fehlerwert";
VAL_ 2463978663 VZE_Zusatzschild_2 0 "keine_Zusatzschild_Initialwert_Fehlerwert";
VAL_ 2463978663 VZE_Zusatzschild_3 0 "keine_Zusatzschild_Initialwert_Fehlerwert";
VAL_ 2463978663 VZE_Anzeigeunterdrueck_Zeichen_1 0 "anzeigerelevant" 1 "nicht_anzeigerelevant";
VAL_ 2463978663 VZE_Zeichen_01_KameraWied 0 "inaktiv" 1 "aktiv";
VAL_ 2463978663 VZE_Zeichen_02_KameraWied 0 "inaktiv" 1 "aktiv";
VAL_ 2463978663 VZE_Zeichen_03_KameraWied 0 "inaktiv" 1 "aktiv";
VAL_ 2463978663 VZE_Zeichen_01_Kamera 0 "nicht_erkannt" 1 "erkannt";
VAL_ 2463978663 VZE_Zeichen_01_Karte 0 "inaktiv" 1 "aktiv";
VAL_ 2463978663 VZE_Zeichen_01_Gesetz 0 "nicht_erkannt" 1 "erkannt";
VAL_ 2463978663 VZE_Zeichen_02_Kamera 0 "nicht_erkannt" 1 "erkannt";
VAL_ 2463978663 VZE_Zeichen_02_Karte 0 "inaktiv" 1 "aktiv";
VAL_ 2463978663 VZE_Zeichen_02_Gesetz 0 "nicht_erkannt" 1 "erkannt";
VAL_ 2463978663 VZE_Zeichen_03_Kamera 0 "nicht_erkannt" 1 "erkannt";
VAL_ 2463978663 VZE_Zeichen_03_Karte 0 "inaktiv" 1 "aktiv";
VAL_ 2463978663 VZE_Zeichen_03_Gesetz 0 "nicht_erkannt" 1 "erkannt";
VAL_ 2463978663 VZE_Gong 0 "Gong_deaktiv" 1 "Gong_aktiv";
VAL_ 2463978663 VZE_Anzeigeunterdrueck_Zeichen_5 0 "anzeigerelevant" 1 "nicht_anzeigerelevant";
VAL_ 2463978663 VZE_Zeichen_05_KameraWied 0 "inaktiv" 1 "aktiv";
VAL_ 2463978663 VZE_Zeichen_05_Kamera 0 "nicht_erkannt" 1 "erkannt";
VAL_ 2463978663 VZE_Verkehrszeichen_4 0 "kein_Verkehrszeichen";
VAL_ 2463978663 VZE_Verkehrszeichen_5 0 "kein_Verkehrszeichen";
VAL_ 2463978663 VZE_Anhaenger_Vmax 14 "Init" 15 "Fehler";
VAL_ 2463978663 VZE_Zeichen_04_Gesetz 0 "nicht_erkannt" 1 "erkannt";
VAL_ 2463978663 VZE_Zeichen_04_Kamera 0 "nicht_erkannt" 1 "erkannt";
VAL_ 2463978663 VZE_Zeichen_04_KameraWied 0 "inaktiv" 1 "aktiv";
VAL_ 2463978663 VZE_Zeichen_04_Karte 0 "inaktiv" 1 "aktiv";
VAL_ 2463978663 VZE_Warnung_Verkehrszeichen_4 0 "keine_Warnung_Initialwert_Fehlerwert" 1 "Warnung";
VAL_ 2463978663 VZE_Warnung_Verkehrszeichen_5 0 "keine_Warnung_Initialwert_Fehlerwert" 1 "Warnung";
VAL_ 2463978663 VZE_Zeichen_05_Gesetz 0 "nicht_erkannt" 1 "erkannt";
VAL_ 2463978663 VZE_Zusatzschild_4 0 "keine_Zusatzschild_Initialwert_Fehlerwert";
VAL_ 2463978663 VZE_Zusatzschild_5 0 "keine_Zusatzschild_Initialwert_Fehlerwert";
VAL_ 2463978663 VZE_Baustelle 0 "Keine_Baustelle" 1 "Baustelle_erkannt";
VAL_ 2463978663 VZE_Zeichen_05_Karte 0 "inaktiv" 1 "aktiv";
VAL_ 2463978663 VZE_Zeichen_05_Entfernung 0 "Init";
VAL_ 2463978663 VZE_Zeichen_05_Entfernung_StdA 0 "Init";
VAL_ 2463978663 VZE_Anzeigeunterdrueck_Zeichen_4 0 "anzeigerelevant" 1 "nicht_anzeigerelevant";
VAL_ 2463978663 VZE_Verkehrszeichen_6 0 "kein_Verkehrszeichen";
VAL_ 2463978663 VZE_Zusatzschild_6 0 "keine_Zusatzschild_Initialwert_Fehlerwert";
VAL_ 2463978663 VZE_Zeichen_06_Entfernung 0 "Init";
VAL_ 2463978663 VZE_Zeichen_06_Entfernung_StdA 0 "Init";
VAL_ 2463978663 VZE_Umweltinfo_Naesse 0 "inaktiv" 1 "aktiv";
VAL_ 2463978663 VZE_Umweltinfo_Nebel 0 "inaktiv" 1 "aktiv";
VAL_ 2463978663 VZE_Umweltinfo_Anhaengerbetrieb 0 "inaktiv" 1 "aktiv";
VAL_ 2463978663 VZE_Erweiterte_Information 0 "keine_Information";
VAL_ 2463978663 VZE_Tempowarnung_Status 0 "inaktiv" 1 "aktiv";
VAL_ 2463978663 VZE_Tempowarnung_Einheit 0 "kmh" 1 "mph";
VAL_ 2463978663 VZE_Tempowarnung_Offset 0 "Init";
VAL_ 2463978663 VZE_FoD_Status 0 "Init" 1 "Funktion_inaktiv" 2 "Funktion_aktiv";
VAL_ 2463978663 VZE_Anzeige_ZS_1 0 "Init";
VAL_ 2463978663 VZE_Anzeige_ZS_2 0 "Init";
VAL_ 2463978663 VZE_Anzeige_ZS_3 0 "Init";
VAL_ 2463978663 VZE_Hinweistext_03 0 "kein_Hinweistext";
VAL_ 2463978663 VZE_Land 0 "Init";
VAL_ 2463978663 VZE_Warnung_VZ_1 0 "keine_Warnung" 1 "Warnung";
VAL_ 2463978663 VZE_Warnung_VZ_2 0 "keine_Warnung" 1 "Warnung";
VAL_ 2463978663 VZE_Warnung_VZ_3 0 "keine_Warnung" 1 "Warnung";
VAL_ 2463978663 VZE_Anzeige_VZ_1 0 "kein_Verkehrszeichen";
VAL_ 2463978663 VZE_Anzeige_VZ_2 0 "kein_Verkehrszeichen";
VAL_ 2463978663 VZE_Anzeige_VZ_3 0 "kein_Verkehrszeichen";
VAL_ 181 WH_gespeicherte_Fahrstufe 0 "keine_Speicherung" 1 "P" 2 "R" 3 "N" 4 "D" 5 "S" 6 "Tipp_Gasse";
VAL_ 181 WH_Initialisierung 0 "keine Initphase" 1 "Initphase";
VAL_ 181 WH_SensorPos_roh 0 "Init" 1 "Pos_1" 2 "Pos_2" 3 "Pos_3" 4 "Pos_4" 5 "Pos_5" 6 "Pos_6" 7 "Pos_7" 8 "Pos_8" 9 "Pos_9" 10 "Pos_10" 11 "Pos_11" 12 "Pos_12" 13 "Pos_13" 14 "Pos_14" 15 "Fehler";
VAL_ 181 WH_SensorPos_roh_inv 0 "Fehler" 1 "Pos_14" 2 "Pos_13" 3 "Pos_12" 4 "Pos_11" 5 "Pos_10" 6 "Pos_9" 7 "Pos_8" 8 "Pos_7" 9 "Pos_6" 10 "Pos_5" 11 "Pos_4" 12 "Pos_3" 13 "Pos_2" 14 "Pos_1" 15 "Init";
VAL_ 181 WH_Test_Aktiv 0 "kein Testergebnis" 1 "Testergebnis";
VAL_ 181 WH_Ist_Haltemagnet 0 "Init__nicht_verbaut" 1 "haelt_nicht" 2 "haelt" 3 "Fehler";
VAL_ 181 WH_Variante 0 "Init" 1 "Rastierter_Waehlhebel" 2 "Tasten" 4 "Monostabil_2x2" 5 "Sport_Tasten" 6 "Monostabil_2x2_reduziert" 7 "Monostabil_2x2_Walzensegment";
VAL_ 181 WH_Entsperrtaste_02 0 "Init_nicht_verbaut" 1 "nicht_betaetigt" 2 "betaetigt" 3 "Fehler";
VAL_ 181 WH_P_Taste 0 "Init" 1 "nicht_betaetigt" 2 "betaetigt" 3 "Fehler";
VAL_ 181 WH_Ende_N_Haltephase 0 "nicht_aktiv" 1 "aktiv";
VAL_ 181 WH_Fahrstufe 8 "P" 0 "Init" 4 "nicht_betaetigt" 5 "D" 6 "N" 7 "R" 9 "N_ohne_Spotausleuchtung" 10 "Tipp_Plus" 11 "Tipp_Minus" 12 "S" 14 "Tipp_Gasse" 15 "Fehler";
VAL_ 181 WH_Status_Shiftlock 0 "Init" 2 "WH_freigegeben" 3 "WH_gesperrt" 6 "Shiftlock_nicht_verbaut" 7 "Fehler";
VAL_ 181 WH_Zustand_N_Haltephase 0 "inaktiv" 1 "aktiv__Timer_laeuft" 2 "beendet__Timer_abgelaufen" 3 "beendet__P_Taste_betaetigt";
VAL_ 2463978687 WH_Fehler_Haltemagnet_Status 0 "Test_nicht_durchgefuehrt" 1 "Test_durchgefuehrt";
VAL_ 2463978687 WH_Fehler_CRC_SBM 0 "Fehler_passiv" 1 "Fehler_aktiv";
VAL_ 2463978687 WH_Fehler_CRC_SBM_Status 0 "Test_nicht_durchgefuehrt" 1 "Test_durchgefuehrt";
VAL_ 2463978687 WH_Fehler_Timeout_SBM 0 "Fehler_passiv" 1 "Fehler_aktiv";
VAL_ 2463978687 WH_Fehler_Timeout_SBM_Status 0 "Test_nicht_durchgefuehrt" 1 "Test_durchgefuehrt";
VAL_ 2463978687 WH_Fehler_Ueberspannung 0 "Fehler_passiv" 1 "Fehler_aktiv";
VAL_ 2463978687 WH_Fehler_Ueberspannung_Status 0 "Test_nicht_durchgefuehrt" 1 "Test_durchgefuehrt";
VAL_ 2463978687 WH_Fehler_BZ_SBM 0 "Fehler_passiv" 1 "Fehler_aktiv";
VAL_ 2463978687 WH_Fehler_BZ_SBM_Status 0 "Test_nicht_durchgefuehrt" 1 "Test_durchgefuehrt";
VAL_ 2463978687 WH_Fehler_Unterspannung 0 "Fehler_passiv" 1 "Fehler_aktiv";
VAL_ 2463978687 WH_Fehler_Unterspannung_Status 0 "Test_nicht_durchgefuehrt" 1 "Test_durchgefuehrt";
VAL_ 2463978687 WH_Fehler_Ausleuchtung 0 "Fehler_passiv" 1 "Fehler_aktiv";
VAL_ 2463978687 WH_Fehler_Ausleuchtung_Status 0 "Test_nicht_durchgefuehrt" 1 "Test_durchgefuehrt";
VAL_ 2463978687 WH_Fehler_Entsperrtaste 0 "Fehler_passiv" 1 "Fehler_aktiv";
VAL_ 2463978687 WH_Fehler_Entsperrtaste_Status 0 "Test_nicht_durchgefuehrt" 1 "Test_durchgefuehrt";
VAL_ 2463978687 WH_Fehler_P_Taste 0 "Fehler_passiv" 1 "Fehler_aktiv";
VAL_ 2463978687 WH_Fehler_P_Taste_Status 0 "Test_nicht_durchgefuehrt" 1 "Test_durchgefuehrt";
VAL_ 2463978687 WH_Fehler_Sensor_einfach 0 "Fehler_passiv" 1 "Fehler_aktiv";
VAL_ 2463978687 WH_Fehler_Sensor_einfach_Status 0 "Test_nicht_durchgefuehrt" 1 "Test_durchgefuehrt";
VAL_ 2463978687 WH_Fehler_Sensor_mehrfach 0 "Fehler_passiv" 1 "Fehler_aktiv";
VAL_ 2463978687 WH_Fehler_Sensor_mehrfach_Status 0 "Test_nicht_durchgefuehrt" 1 "Test_durchgefuehrt";
VAL_ 2463978687 WH_Fehler_Shiftlock 0 "Fehler_passiv" 1 "Fehler_aktiv";
VAL_ 2463978687 WH_Fehler_Shiftlock_Status 0 "Test_nicht_durchgefuehrt" 1 "Test_durchgefuehrt";
VAL_ 916 WBA_Fahrstufe_02 0 "Zwischenstellung_keine_Position" 1 "Position_P" 2 "Position_R" 3 "Position_N" 4 "Position_D" 5 "Position_S" 6 "Position_M_Tippfunktion" 7 "Kurzzeit_M" 8 "Position_E" 9 "Position_MS" 10 "Position_S_Plus" 11 "Position_MS_Plus" 12 "Position_Offroad" 13 "Position_B";
VAL_ 916 WBA_ZielFahrstufe 0 "keine_Gangempfehlung_kein_Gang_eingelegt" 1 "Pfeil_nach_S" 2 "Pfeil_nach_D" 3 "Pfeil_nach_M" 4 "Pfeil_nach_E";
VAL_ 916 WBA_GE_Warnung_02 0 "keine_Anzeige" 1 "Fehlereskalationsstufe_I" 2 "Fehlereskalationsstufe_II" 3 "Weiterfahrt_nur_eingeschraenkt_moeglich__Kein_R_Gang" 4 "Getriebefehler_Weiterfahrt_nur_in_D_moeglich__P_bei_Motor_aus" 5 "Wegrollgefahr__P_nicht_moeglich" 6 "Paddlenotbetrieb_Schema+Warnung" 7 "Paddlenotbetrieb_Schema" 8 "Geschwindigkeitsbegrenzung_Notlauf" 9 "Fehlereskalationsst_o_Einschr" 10 "Fehlereskalationsstufe_v_Limit" 11 "Parksperre_Infostufe" 12 "Parksperre_Warnstufe_I" 13 "Parksperre_Warnstufe_II";
VAL_ 916 WBA_eing_Gang_02 0 "keine_Ganganzeige" 1 "Gang_1" 2 "Gang_2" 3 "Gang_3" 4 "Gang_4" 5 "Gang_5" 6 "Gang_6" 7 "Gang_7" 8 "Gang_8" 9 "Gang_9" 10 "Funktion_Ganganzeigeunterdrueckung" 11 "Gang_10";
VAL_ 916 WBA_GE_Texte 0 "keine_Anzeige" 1 "zum_Einlegen_einer_Fahrstufe_Fussbremse_betaetigen__ShiftLock_Information" 2 "zum_Einlegen_von_R_N_D_Fussbremse_betaetigen_und_Motor_starten" 3 "Wegrollgefahr_bitte_P_einlegen" 4 "Achtung_Zeitueberschreitung_P_wird_eingelegt" 5 "Wiederanmeldeprozedur_Bremse_betaetigen" 6 "P_nur_im_Stillstand_moeglich" 7 "Rennstart_aktiv";
VAL_ 916 WBA_Segeln_aktiv 0 "inaktiv" 1 "aktiv";
VAL_ 916 WBA_Schaltschema_02 0 "kein_Schaltschema" 1 "R_N_DS" 2 "R_N_ES" 3 "R_N_DB" 4 "R_N_D";
VAL_ 916 WBA_Schaltschema_FS_inaktiv 0 "alle_Fahrstufen_aktiv" 1 "Fahrstufe_Rueckwaerts_inaktiv" 2 "nur_P_und_N_aktiv" 3 "alle_Fahrstufen_inaktiv";
VAL_ 916 WBA_GE_Zusatzwarnungen 0 "keine_Anzeige" 1 "Getriebeueberhitzung_Warnstufe_I" 2 "Getriebeueberhitzung_Warnstufe_II" 3 "Getriebefehler_Bitte_anhalten_und_P_einlegen";
VAL_ 916 GE_Sollgang 0 "keine_Empfehlung" 1 "Gang_1" 2 "Gang_2" 3 "Gang_3" 4 "Gang_4" 5 "Gang_5" 6 "Gang_6" 7 "Gang_7" 8 "Gang_8" 9 "Gang_9" 11 "Gang_10";
VAL_ 916 GE_Tipschaltempf_verfuegbar 0 "nicht_verfuegbar" 1 "verfuegbar";
VAL_ 916 WBA_GE_Texte_02 0 "Keine_Anzeige" 1 "Fahrtrichtungswechsel_nur_nach_Stillstandt" 2 "Ladestecker_gesteckt" 3 "zusaetzlicher_Service_erforderlich" 4 "eLaunch_Aktiv" 5 "eLaunch_nicht_moeglich" 6 "WH_S_nicht_moeglich_Offroad" 7 "WH_S_nicht_moeglich_RangeMode";
VAL_ 916 WBA_Schaltschema_Tippgasse 0 "keine_Tippgasse_vorhanden" 1 "Tippgasse_vorhanden";
VAL_ 916 WBA_Schaltschema_Fahreraktion 0 "keine_Fahreraktion" 1 "Fahreraktion";
VAL_ 916 WBA_Schaltschema_FS_vorwaerts 0 "FS1_aktiv__FS2_moeglich" 1 "FS2_aktiv__FS1_moeglich" 2 "FS1_aktiv__FS2_nicht_moeglich" 3 "FS2_aktiv__FS1_nicht_moeglich";
VAL_ 916 WBA_Shiftlock_Lampe 0 "Shiftlock_Lampe_AUS" 1 "Shiftlock_Lampe_EIN";
VAL_ 916 WBA_Anforderung_Akustik 0 "Akustik_aus" 1 "Akustik_ein";
VAL_ 916 WBA_Blinken 0 "kein_WBA_Blinken" 1 "WBA_Blinken";
VAL_ 916 GE_Wiederstart_Anz_Std 0 "keine_Anzeige" 1 "Standard_Wiederstartgrund";
VAL_ 916 GE_Stoppverbot_Anz_01 0 "keine_Anzeige" 1 "Temperaturbedingung";
VAL_ 916 GE_Stoppverbot_Anz_02 0 "keine_Anzeige" 1 "Drucksensorausfall";
VAL_ 916 GE_Stoppverbot_Anz_03 0 "keine_Anzeige" 1 "Grundeinstellung";
VAL_ 916 GE_Stoppverbot_Anz_04 0 "keine_Anzeige" 1 "Demontagestellung";
VAL_ 916 GE_Stoppverbot_Anz_05 0 "keine_Anzeige" 1 "Eingeschraenkte_Fahrfunktion_Notlauf_Liegenbleiber";
VAL_ 916 GE_Stoppverbot_Anz_06 0 "keine_Anzeige" 1 "Stoppverbot_ueber_Applikation";
VAL_ 916 GE_Stoppverbot_Anz_07 0 "keine_Anzeige" 1 "Schaltung_aktiv";
VAL_ 916 GE_Stoppverbot_Anz_Std 0 "keine_Anzeige" 1 "Standard_Stoppvetogrund";
VAL_ 1361 WFS_Schluessel_Fahrberecht 0 "kein authorisierter Schluessel erkannt" 1 "aktive_Funkschluessel_Nr_01" 2 "aktive_Funkschluessel_Nr_02" 3 "aktive_Funkschluessel_Nr_03" 4 "aktive_Funkschluessel_Nr_04" 5 "aktive_Funkschluessel_Nr_05" 6 "aktive_Funkschluessel_Nr_06" 7 "aktive_Funkschluessel_Nr_07" 8 "aktive_Funkschluessel_Nr_08" 9 "ungueltig_09" 10 "ungueltig_10" 11 "ungueltig_11" 12 "ungueltig_12" 13 "ungueltig_13" 14 "ungueltig_14" 15 "digitaler_Schluessel_aktiv";
VAL_ 1361 WFS_Verbauinfo_ELV 0 "ELV_nicht_verbaut" 1 "ELV_verbaut";
VAL_ 1361 WFS_ID_Geb_autorisiert 0 "Schluessel_nicht_authorisiert" 1 "Schluessel authorisiert";
VAL_ 1361 WFS_ID_Geb_autorisiert_in_Kl15 0 "nicht_authorisiert_in_Kl15" 1 "authorisiert_in_Kl15";
VAL_ 1361 WFS_ID_Geb_steckt 0 "kein_Schluessel_im_Zuendschloss" 1 " Schluessel steckt im Zuendschloss";
VAL_ 1361 WFS_Safe 1 "WFS nicht deaktiviert";
VAL_ 1361 WFS_LZ 0 "nicht def." 1 "LZ 1" 2 "LZ 2" 3 "LZ 3";
VAL_ 1361 WFS_ELV_authorisiert 0 "ELV_nicht_authorisiert" 1 "ELV_authorisiert";
VAL_ 1361 WFS_LF_Aktiv 0 "Funktempfang_nicht_aktiv" 1 "LF_Funkempfang_aktiv";
VAL_ 1361 WFS_Betrieb_Lesespule 0 "keine_Schluesselkomm_Lesespule" 1 "Schluesselkomm_Lesespule";
VAL_ 1361 WFS_Klemmenfreigabe 0 "keine_Freigabe" 1 "Freigabe";
VAL_ 1361 WFS_Fahrerhinweise 0 "Keine_Anzeigeanforderung" 1 "Schuessel_Auth_niO" 2 "Notlauf_aktiv" 3 "Schluessel_Kessy_nicht_gefunden";
VAL_ 1361 WFS_Parken_Status 0 "Limitierung_inaktiv" 1 "Limitierung_aktiv" 2 "Abbruch";
VAL_ 1411 ZV_verriegeln_Anf 0 "nicht_betaetigt" 1 "betaetigt";
VAL_ 1411 ZV_STSG_HFS_Anf 0 "keine_Anforderung" 1 "Anforderung";
VAL_ 1411 ZV_STSG_HBFS_Anf 0 "keine_Anforderung" 1 "Anforderung";
VAL_ 1411 ZV_Anf_Challenge_Auth 0 "nicht_aktiv" 1 "aktiv";
VAL_ 1411 BCM_FH_Freigabe 1 "Funktionsfreigabe Fensterheber";
VAL_ 1411 BCM_Komfortfkt_Freigabe 0 "Komfortfunktion gesperrt" 1 "globale Freigabe der Komfortfunktion erteilt";
VAL_ 1411 BCM_HSK_Freigabe 0 "erlauben" 1 "sperren";
VAL_ 1411 BCM_Verdeck_Freigabe 0 "Verdeckbetrieb nicht erlaubt" 1 "Verdeckbetrieb erlaubt";
VAL_ 1411 ZV_verriegelt_intern_ist 1 "Fahrzeug innen verriegelt; Istzustand";
VAL_ 1411 ZV_verriegelt_extern_ist 1 "Fahrzeug_aussen_verriegelt_Istzustand";
VAL_ 1411 ZV_verriegelt_intern_soll 1 "Fahrzeug verriegelt intern; Sollzusstand";
VAL_ 1411 ZV_verriegelt_extern_soll 1 "Fahrzeug verriegelt extern; Sollzusstand";
VAL_ 1411 ZV_gesafet_extern_ist 1 "Fahrzeug aussen gesafet; Istzustand";
VAL_ 1411 ZV_gesafet_extern_soll 1 "Fahrzeug_aussen_gesafet_Sollzustand";
VAL_ 1411 ZV_Einzeltuerentriegelung 1 "Fahrzeug an Einzeltuer entriegelt";
VAL_ 1411 ZV_Heckeinzelentriegelung 1 "Heckdeckeleinzelentriegelung";
VAL_ 1411 ZV_FT_offen 1 "FT_geoeffnet";
VAL_ 1411 ZV_BT_offen 1 "BT_geoeffnet";
VAL_ 1411 ZV_HFS_offen 0 "geschlossen" 1 "offen";
VAL_ 1411 ZV_HBFS_offen 0 "geschlossen" 1 "offen";
VAL_ 1411 ZV_HD_offen 1 "Heckdeckel_auf";
VAL_ 1411 ZV_HS_offen 0 "Heckscheibe_geschlossen" 1 "Heckscheibe auf";
VAL_ 1411 IRUE_aktiv 0 "unscharf" 1 "scharf";
VAL_ 1411 DWA_aktiv 0 "unscharf" 1 "scharf";
VAL_ 1411 FFB_HDF_Taste 0 "Taste_nicht_betaetigt" 1 "HDF_Taste_am_Funkschluessel_betaetigt";
VAL_ 1411 FFB_Panik_Taste 0 "Taste_nicht_betaetigt" 1 "Panik_Taste_am_Funkschluessel_betaetigt";
VAL_ 1411 FFB_Auf_Taste 0 "Taste_nicht_betaetigt" 1 "Oeffnentaste_betaetigt";
VAL_ 1411 FFB_Zu_Taste 0 "Taste_nicht_betaetigt" 1 "Zu_Taste_am_Funkschluessel_betaetigt";
VAL_ 1411 FFB_CarFinder 0 "nicht aktiv" 1 "aktiv";
VAL_ 1411 FFB_Komfortoeffnen 0 "kein_Komfortoeffnen_empfangen" 1 "Komfortoeffnen ueber Funk empfangen";
VAL_ 1411 FFB_Komfortschliessen 0 "kein_Komfortschliessen_empfangen" 1 "Komfortschliessen ueber Funk empfangen";
VAL_ 1411 FBS_IDG_in_Reichweite 0 "ausser_Reichweite_bzw_nicht_ermittelbar" 1 "innerhalb_Reichweite";
VAL_ 1411 ZV_Schluessel_Zugang 0 "kein authorisierter Schluessel erkannt " 1 "aktive_Funkschluessel_Nr_01" 2 "aktive_Funkschluessel_Nr_02" 3 "aktive_Funkschluessel_Nr_03" 4 "aktive_Funkschluessel_Nr_04" 5 "aktive_Funkschluessel_Nr_05" 6 "aktive_Funkschluessel_Nr_06" 7 "aktive_Funkschluessel_Nr_07" 8 "aktive_Funkschluessel_Nr_08" 9 "ungueltig_09" 10 "ungueltig_10" 11 "ungueltig_11" 12 "ungueltig_12" 13 "ungueltig_13" 14 "ungueltig_14" 15 "ungueltig_15";
VAL_ 1411 ZV_SafeFunktion_aktiv 0 "inaktiv" 1 "aktiv";
VAL_ 1411 FBS_Warn_Schluessel_Batt 0 "i.O." 1 "defekt";
VAL_ 1411 ZV_Oeffnungsmodus 0 "globale_Oeffnung" 1 "ZV_mit_Einzeltuerentr" 2 "ZV_individuell_selektiv" 3 "ZV_seitenselektiv";
VAL_ 1411 ZV_ist_Zustand_verfuegbar 0 "nicht_verfuegbar" 1 "verfuegbar_alle_TSGs_am_Bus";
VAL_ 1411 IRUE_Taster_Fkts_LED 0 "LED_aus" 1 "LED_ein";
VAL_ 1411 ZV_Tankklappe_offen 0 "Tankklappe_geschlossen" 1 "Tankklappe_offen";
VAL_ 1411 ZV_Rollo_auf 0 "inaktiv" 1 "aktiv";
VAL_ 1411 ZV_Rollo_zu 0 "inaktiv" 1 "aktiv";
VAL_ 1411 ZV_SAD_auf 0 "inaktiv" 1 "aktiv";
VAL_ 1411 ZV_SAD_zu 0 "inaktiv" 1 "aktiv";
VAL_ 1411 ZV_verriegelt_soll 0 "Init" 1 "nicht_verriegelt" 2 "verriegelt";
